VERSION ""

NS_ :

BS_:

BU_:

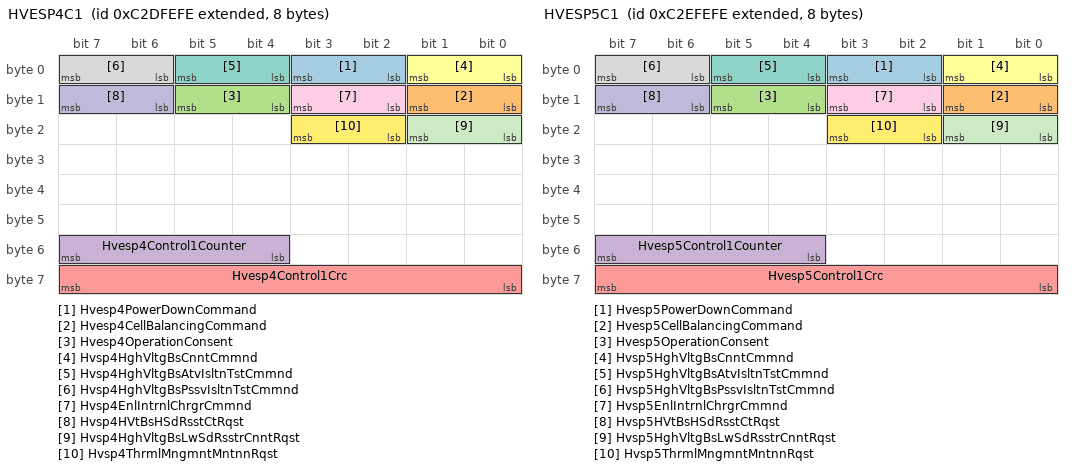
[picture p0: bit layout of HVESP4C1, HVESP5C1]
BO_ 2351824638 HVESP4C1: 8 Vector__XXX
 SG_ Hvesp4PowerDownCommand : 2|2@1+ (1,0) [0|3] "" Vector__XXX
 SG_ Hvesp4CellBalancingCommand : 8|2@1+ (1,0) [0|3] "" Vector__XXX
 SG_ Hvesp4OperationConsent : 12|2@1+ (1,0) [0|3] "" Vector__XXX
 SG_ Hvesp4Control1Counter : 52|4@1+ (1,0) [0|15] "" Vector__XXX
 SG_ Hvesp4Control1Crc : 56|8@1+ (1,0) [0|250] "count" Vector__XXX
 SG_ Hvsp4HghVltgBsCnntCmmnd : 0|2@1+ (1,0) [0|3] "" Vector__XXX
 SG_ Hvsp4HghVltgBsAtvIsltnTstCmmnd : 4|2@1+ (1,0) [0|3] "" Vector__XXX
 SG_ Hvsp4HghVltgBsPssvIsltnTstCmmnd : 6|2@1+ (1,0) [0|3] "" Vector__XXX
 SG_ Hvsp4EnlIntrnlChrgrCmmnd : 10|2@1+ (1,0) [0|3] "" Vector__XXX
 SG_ Hvsp4HVtBsHSdRsstCtRqst : 14|2@1+ (1,0) [0|3] "" Vector__XXX
 SG_ Hvsp4HghVltgBsLwSdRsstrCnntRqst : 16|2@1+ (1,0) [0|3] "" Vector__XXX
 SG_ Hvsp4ThrmlMngmntMntnnRqst : 18|2@1+ (1,0) [0|3] "" Vector__XXX

BO_ 2351890174 HVESP5C1: 8 Vector__XXX
 SG_ Hvesp5PowerDownCommand : 2|2@1+ (1,0) [0|3] "" Vector__XXX
 SG_ Hvesp5CellBalancingCommand : 8|2@1+ (1,0) [0|3] "" Vector__XXX
 SG_ Hvesp5OperationConsent : 12|2@1+ (1,0) [0|3] "" Vector__XXX
 SG_ Hvesp5Control1Counter : 52|4@1+ (1,0) [0|15] "" Vector__XXX
 SG_ Hvesp5Control1Crc : 56|8@1+ (1,0) [0|250] "count" Vector__XXX
 SG_ Hvsp5HghVltgBsCnntCmmnd : 0|2@1+ (1,0) [0|3] "" Vector__XXX
 SG_ Hvsp5HghVltgBsAtvIsltnTstCmmnd : 4|2@1+ (1,0) [0|3] "" Vector__XXX
 SG_ Hvsp5HghVltgBsPssvIsltnTstCmmnd : 6|2@1+ (1,0) [0|3] "" Vector__XXX
 SG_ Hvsp5EnlIntrnlChrgrCmmnd : 10|2@1+ (1,0) [0|3] "" Vector__XXX
 SG_ Hvsp5HVtBsHSdRsstCtRqst : 14|2@1+ (1,0) [0|3] "" Vector__XXX
 SG_ Hvsp5HghVltgBsLwSdRsstrCnntRqst : 16|2@1+ (1,0) [0|3] "" Vector__XXX
 SG_ Hvsp5ThrmlMngmntMntnnRqst : 18|2@1+ (1,0) [0|3] "" Vector__XXX

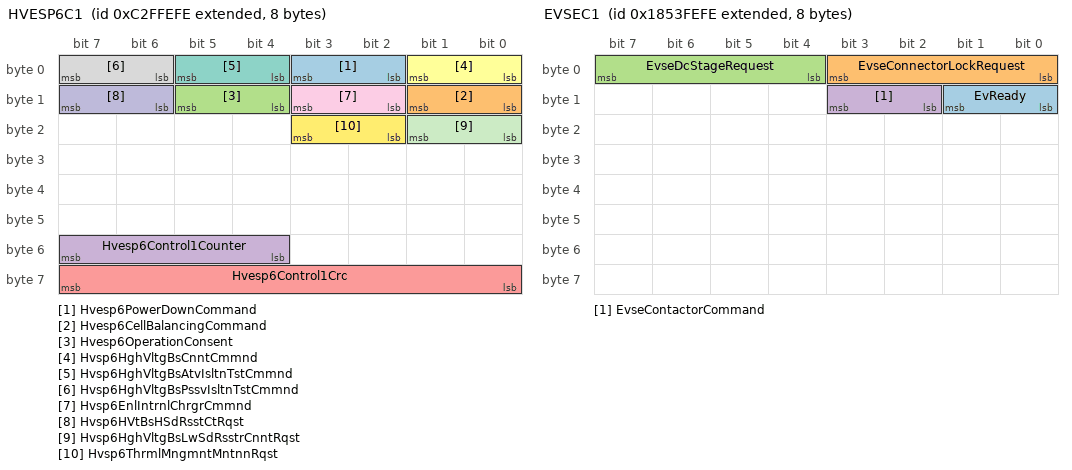
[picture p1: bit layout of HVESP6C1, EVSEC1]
BO_ 2351955710 HVESP6C1: 8 Vector__XXX
 SG_ Hvesp6PowerDownCommand : 2|2@1+ (1,0) [0|3] "" Vector__XXX
 SG_ Hvesp6CellBalancingCommand : 8|2@1+ (1,0) [0|3] "" Vector__XXX
 SG_ Hvesp6OperationConsent : 12|2@1+ (1,0) [0|3] "" Vector__XXX
 SG_ Hvesp6Control1Counter : 52|4@1+ (1,0) [0|15] "" Vector__XXX
 SG_ Hvesp6Control1Crc : 56|8@1+ (1,0) [0|250] "count" Vector__XXX
 SG_ Hvsp6HghVltgBsCnntCmmnd : 0|2@1+ (1,0) [0|3] "" Vector__XXX
 SG_ Hvsp6HghVltgBsAtvIsltnTstCmmnd : 4|2@1+ (1,0) [0|3] "" Vector__XXX
 SG_ Hvsp6HghVltgBsPssvIsltnTstCmmnd : 6|2@1+ (1,0) [0|3] "" Vector__XXX
 SG_ Hvsp6EnlIntrnlChrgrCmmnd : 10|2@1+ (1,0) [0|3] "" Vector__XXX
 SG_ Hvsp6HVtBsHSdRsstCtRqst : 14|2@1+ (1,0) [0|3] "" Vector__XXX
 SG_ Hvsp6HghVltgBsLwSdRsstrCnntRqst : 16|2@1+ (1,0) [0|3] "" Vector__XXX
 SG_ Hvsp6ThrmlMngmntMntnnRqst : 18|2@1+ (1,0) [0|3] "" Vector__XXX

BO_ 2555641598 EVSEC1: 8 Vector__XXX
 SG_ EvReady : 8|2@1+ (1,0) [0|3] "" Vector__XXX
 SG_ EvseConnectorLockRequest : 0|4@1+ (1,0) [0|15] "" Vector__XXX
 SG_ EvseDcStageRequest : 4|4@1+ (1,0) [0|15] "" Vector__XXX
 SG_ EvseContactorCommand : 10|2@1+ (1,0) [0|3] "" Vector__XXX

BO_ 2555707134 WINCH3: 8 Vector__XXX
 SG_ WinchPositionReset : 0|2@1+ (1,0) [0|3] "" Vector__XXX

BO_ 2354446078 ASC8: 8 Vector__XXX
 SG_ LiftAxle3PositionCommand : 0|2@1+ (1,0) [0|3] "" Vector__XXX

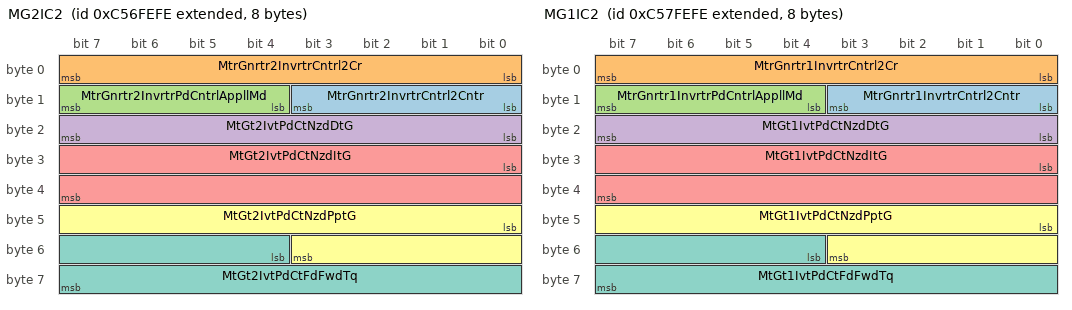
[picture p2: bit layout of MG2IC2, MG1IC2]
BO_ 2354511614 MG2IC2: 8 Vector__XXX
 SG_ MtrGnrtr2InvrtrCntrl2Cntr : 8|4@1+ (1,0) [0|15] "" Vector__XXX
 SG_ MtrGnrtr2InvrtrCntrl2Cr : 0|8@1+ (1,0) [0|250] "count" Vector__XXX
 SG_ MtrGnrtr2InvrtrPdCntrlAppllMd : 12|4@1+ (1,0) [0|15] "" Vector__XXX
 SG_ MtGt2IvtPdCtNzdDtG : 16|8@1+ (0.03125,0) [0|7.8125] "%/(%/s)" Vector__XXX
 SG_ MtGt2IvtPdCtNzdItG : 24|16@1+ (0.015625,0) [0|1003.984375] "%/(%/s)" Vector__XXX
 SG_ MtGt2IvtPdCtNzdPptG : 40|12@1+ (0.0625,0) [0|250.9375] "%/%" Vector__XXX
 SG_ MtGt2IvtPdCtFdFwdTq : 52|12@1+ (0.0625,-125) [-125|125.9375] "%" Vector__XXX

BO_ 2354577150 MG1IC2: 8 Vector__XXX
 SG_ MtrGnrtr1InvrtrCntrl2Cntr : 8|4@1+ (1,0) [0|15] "" Vector__XXX
 SG_ MtrGnrtr1InvrtrCntrl2Cr : 0|8@1+ (1,0) [0|250] "count" Vector__XXX
 SG_ MtrGnrtr1InvrtrPdCntrlAppllMd : 12|4@1+ (1,0) [0|15] "" Vector__XXX
 SG_ MtGt1IvtPdCtNzdDtG : 16|8@1+ (0.03125,0) [0|7.8125] "%/(%/s)" Vector__XXX
 SG_ MtGt1IvtPdCtNzdItG : 24|16@1+ (0.015625,0) [0|1003.984375] "%/(%/s)" Vector__XXX
 SG_ MtGt1IvtPdCtNzdPptG : 40|12@1+ (0.0625,0) [0|250.9375] "%/%" Vector__XXX
 SG_ MtGt1IvtPdCtFdFwdTq : 52|12@1+ (0.0625,-125) [-125|125.9375] "%" Vector__XXX

BO_ 2488860414 HCI2: 8 Vector__XXX
 SG_ HoistCommand : 0|16@1+ (0.005,-150) [-100|100] "%" Vector__XXX
 SG_ HoistDetentStatus : 16|2@1+ (1,0) [0|3] "" Vector__XXX

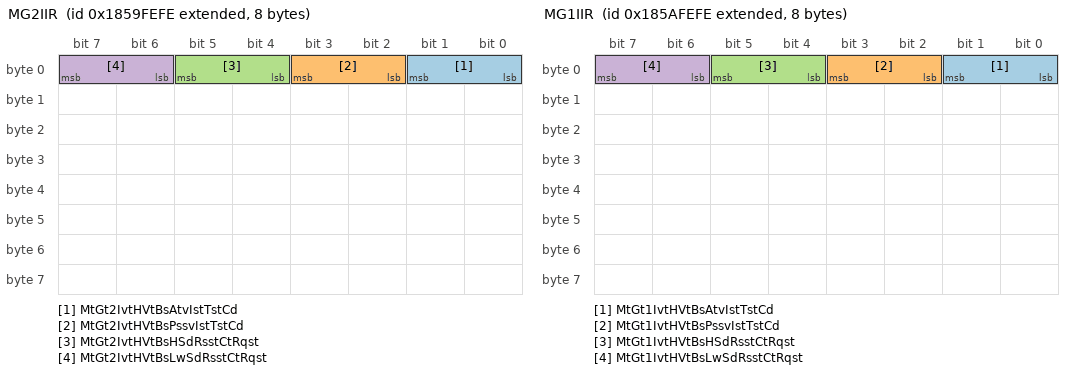
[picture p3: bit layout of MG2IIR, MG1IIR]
BO_ 2556034814 MG2IIR: 8 Vector__XXX
 SG_ MtGt2IvtHVtBsAtvIstTstCd : 0|2@1+ (1,0) [0|3] "" Vector__XXX
 SG_ MtGt2IvtHVtBsPssvIstTstCd : 2|2@1+ (1,0) [0|3] "" Vector__XXX
 SG_ MtGt2IvtHVtBsHSdRsstCtRqst : 4|2@1+ (1,0) [0|3] "" Vector__XXX
 SG_ MtGt2IvtHVtBsLwSdRsstCtRqst : 6|2@1+ (1,0) [0|3] "" Vector__XXX

BO_ 2556100350 MG1IIR: 8 Vector__XXX
 SG_ MtGt1IvtHVtBsAtvIstTstCd : 0|2@1+ (1,0) [0|3] "" Vector__XXX
 SG_ MtGt1IvtHVtBsPssvIstTstCd : 2|2@1+ (1,0) [0|3] "" Vector__XXX
 SG_ MtGt1IvtHVtBsHSdRsstCtRqst : 4|2@1+ (1,0) [0|3] "" Vector__XXX
 SG_ MtGt1IvtHVtBsLwSdRsstCtRqst : 6|2@1+ (1,0) [0|3] "" Vector__XXX

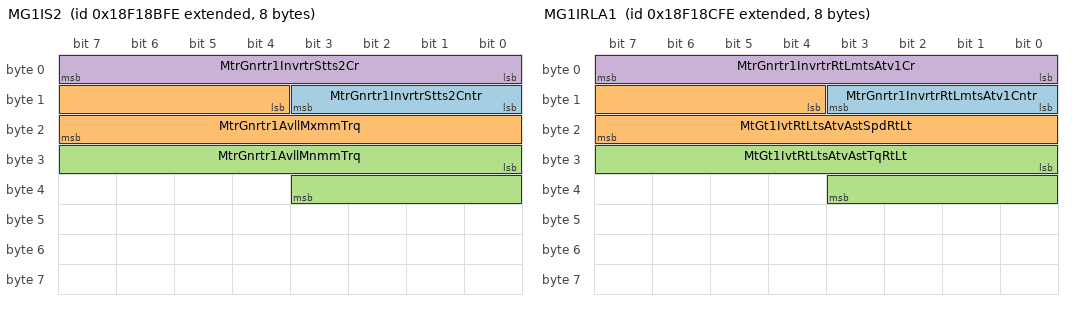
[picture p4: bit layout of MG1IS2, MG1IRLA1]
BO_ 2565966846 MG1IS2: 8 Vector__XXX
 SG_ MtrGnrtr1InvrtrStts2Cntr : 8|4@1+ (1,0) [0|15] "" Vector__XXX
 SG_ MtrGnrtr1AvllMxmmTrq : 12|12@1+ (0.0625,-125) [-125|125.9375] "%" Vector__XXX
 SG_ MtrGnrtr1AvllMnmmTrq : 24|12@1+ (0.0625,-125) [-125|125.9375] "%" Vector__XXX
 SG_ MtrGnrtr1InvrtrStts2Cr : 0|8@1+ (1,0) [0|250] "count" Vector__XXX

BO_ 2565967102 MG1IRLA1: 8 Vector__XXX
 SG_ MtrGnrtr1InvrtrRtLmtsAtv1Cntr : 8|4@1+ (1,0) [0|15] "" Vector__XXX
 SG_ MtGt1IvtRtLtsAtvAstSpdRtLt : 12|12@1+ (0.25,0) [0|1003.75] "%/s" Vector__XXX
 SG_ MtGt1IvtRtLtsAtvAstTqRtLt : 24|12@1+ (2,0) [0|8030] "%/s" Vector__XXX
 SG_ MtrGnrtr1InvrtrRtLmtsAtv1Cr : 0|8@1+ (1,0) [0|250] "count" Vector__XXX

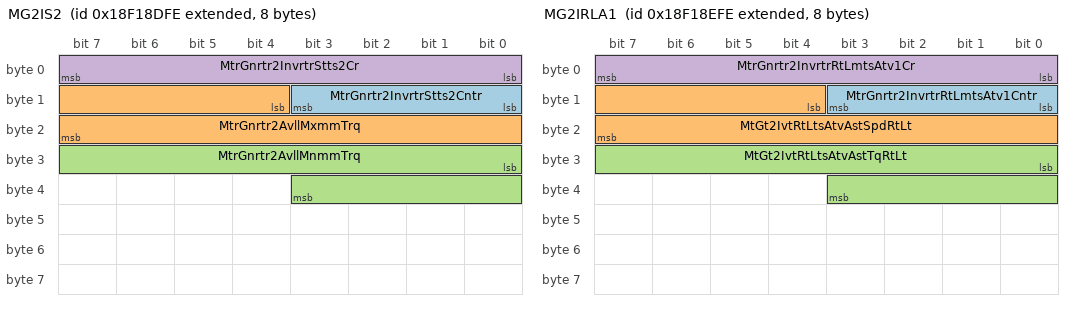
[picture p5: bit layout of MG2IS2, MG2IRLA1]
BO_ 2565967358 MG2IS2: 8 Vector__XXX
 SG_ MtrGnrtr2InvrtrStts2Cntr : 8|4@1+ (1,0) [0|15] "" Vector__XXX
 SG_ MtrGnrtr2AvllMxmmTrq : 12|12@1+ (0.0625,-125) [-125|125.9375] "%" Vector__XXX
 SG_ MtrGnrtr2AvllMnmmTrq : 24|12@1+ (0.0625,-125) [-125|125.9375] "%" Vector__XXX
 SG_ MtrGnrtr2InvrtrStts2Cr : 0|8@1+ (1,0) [0|250] "count" Vector__XXX

BO_ 2565967614 MG2IRLA1: 8 Vector__XXX
 SG_ MtrGnrtr2InvrtrRtLmtsAtv1Cntr : 8|4@1+ (1,0) [0|15] "" Vector__XXX
 SG_ MtGt2IvtRtLtsAtvAstSpdRtLt : 12|12@1+ (0.25,0) [0|1003.75] "%/s" Vector__XXX
 SG_ MtGt2IvtRtLtsAtvAstTqRtLt : 24|12@1+ (2,0) [0|8030] "%/s" Vector__XXX
 SG_ MtrGnrtr2InvrtrRtLmtsAtv1Cr : 0|8@1+ (1,0) [0|250] "count" Vector__XXX

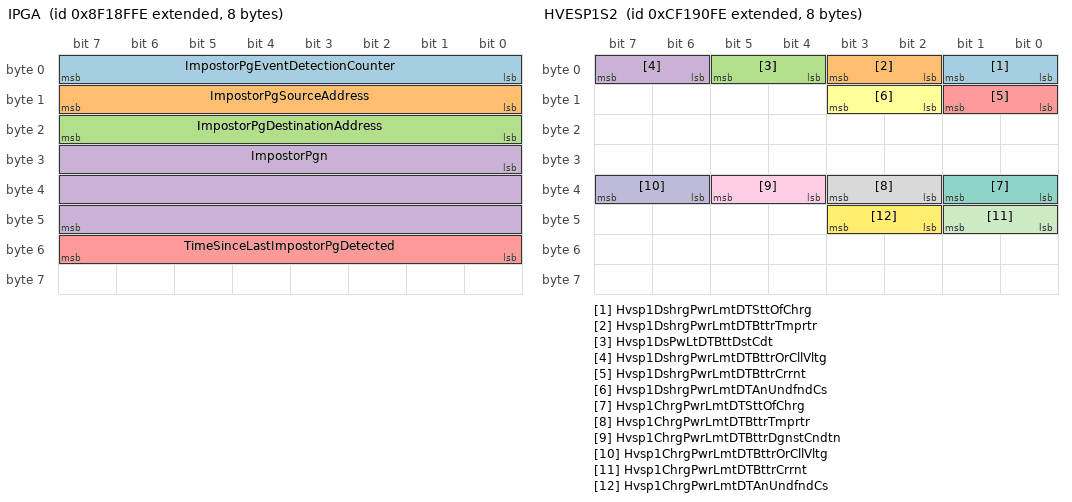
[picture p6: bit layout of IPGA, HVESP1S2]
BO_ 2297532414 IPGA: 8 Vector__XXX
 SG_ ImpostorPgEventDetectionCounter : 0|8@1+ (1,0) [0|250] "count" Vector__XXX
 SG_ ImpostorPgSourceAddress : 8|8@1+ (1,0) [0|250] "sourceadr" Vector__XXX
 SG_ ImpostorPgDestinationAddress : 16|8@1+ (1,0) [0|250] "sourceadr" Vector__XXX
 SG_ ImpostorPgn : 24|24@1+ (1,0) [0|16449535] "" Vector__XXX
 SG_ TimeSinceLastImpostorPgDetected : 48|8@1+ (1,0) [0|250] "min" Vector__XXX

BO_ 2364641534 HVESP1S2: 8 Vector__XXX
 SG_ Hvsp1DshrgPwrLmtDTSttOfChrg : 0|2@1+ (1,0) [0|3] "" Vector__XXX
 SG_ Hvsp1DshrgPwrLmtDTBttrTmprtr : 2|2@1+ (1,0) [0|3] "" Vector__XXX
 SG_ Hvsp1DsPwLtDTBttDstCdt : 4|2@1+ (1,0) [0|3] "" Vector__XXX
 SG_ Hvsp1DshrgPwrLmtDTBttrOrCllVltg : 6|2@1+ (1,0) [0|3] "" Vector__XXX
 SG_ Hvsp1DshrgPwrLmtDTBttrCrrnt : 8|2@1+ (1,0) [0|3] "" Vector__XXX
 SG_ Hvsp1DshrgPwrLmtDTAnUndfndCs : 10|2@1+ (1,0) [0|3] "" Vector__XXX
 SG_ Hvsp1ChrgPwrLmtDTSttOfChrg : 32|2@1+ (1,0) [0|3] "" Vector__XXX
 SG_ Hvsp1ChrgPwrLmtDTBttrTmprtr : 34|2@1+ (1,0) [0|3] "" Vector__XXX
 SG_ Hvsp1ChrgPwrLmtDTBttrDgnstCndtn : 36|2@1+ (1,0) [0|3] "" Vector__XXX
 SG_ Hvsp1ChrgPwrLmtDTBttrOrCllVltg : 38|2@1+ (1,0) [0|3] "" Vector__XXX
 SG_ Hvsp1ChrgPwrLmtDTBttrCrrnt : 40|2@1+ (1,0) [0|3] "" Vector__XXX
 SG_ Hvsp1ChrgPwrLmtDTAnUndfndCs : 42|2@1+ (1,0) [0|3] "" Vector__XXX

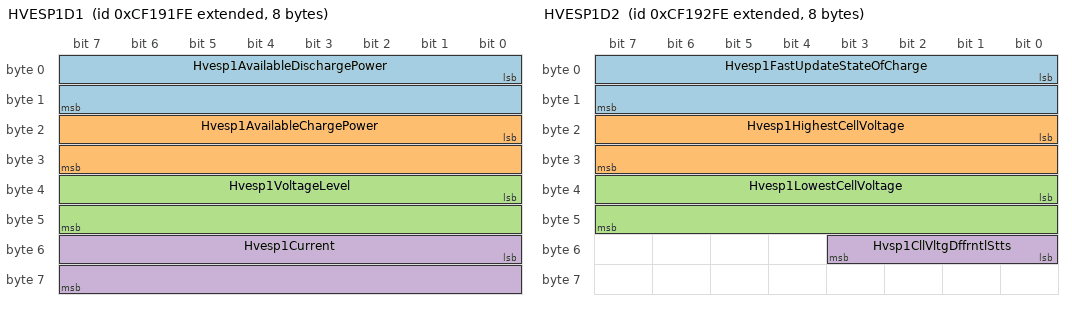
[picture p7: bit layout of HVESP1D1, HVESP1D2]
BO_ 2364641790 HVESP1D1: 8 Vector__XXX
 SG_ Hvesp1AvailableDischargePower : 0|16@1+ (0.05,0) [0|3212.75] "kW" Vector__XXX
 SG_ Hvesp1AvailableChargePower : 16|16@1+ (0.05,0) [0|3212.75] "kW" Vector__XXX
 SG_ Hvesp1VoltageLevel : 32|16@1+ (0.05,0) [0|3212.75] "V" Vector__XXX
 SG_ Hvesp1Current : 48|16@1+ (0.05,-1600) [-1600|1612.75] "A" Vector__XXX

BO_ 2364642046 HVESP1D2: 8 Vector__XXX
 SG_ Hvesp1FastUpdateStateOfCharge : 0|16@1+ (0.0015625,0) [0|100.3984375] "%" Vector__XXX
 SG_ Hvesp1HighestCellVoltage : 16|16@1+ (0.001,0) [0|64.255] "V" Vector__XXX
 SG_ Hvesp1LowestCellVoltage : 32|16@1+ (0.001,0) [0|64.255] "V" Vector__XXX
 SG_ Hvsp1CllVltgDffrntlStts : 48|4@1+ (1,0) [0|15] "" Vector__XXX

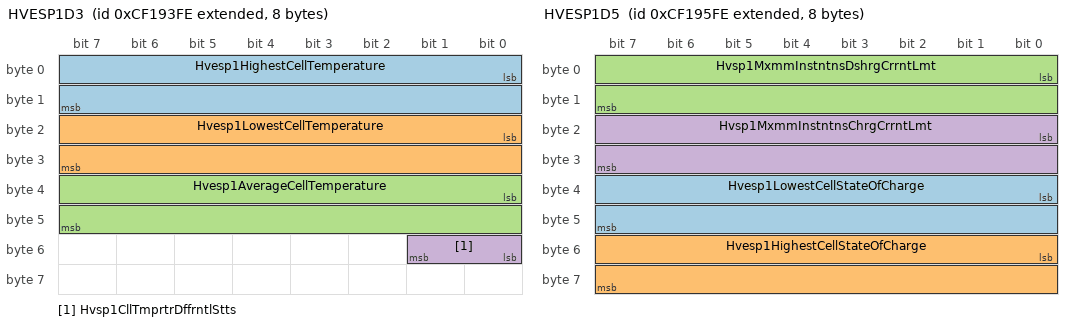
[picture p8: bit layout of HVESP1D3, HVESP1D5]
BO_ 2364642302 HVESP1D3: 8 Vector__XXX
 SG_ Hvesp1HighestCellTemperature : 0|16@1+ (0.03125,-273) [-273|1734.96875] "degC" Vector__XXX
 SG_ Hvesp1LowestCellTemperature : 16|16@1+ (0.03125,-273) [-273|1734.96875] "degC" Vector__XXX
 SG_ Hvesp1AverageCellTemperature : 32|16@1+ (0.03125,-273) [-273|1734.96875] "degC" Vector__XXX
 SG_ Hvsp1CllTmprtrDffrntlStts : 48|2@1+ (1,0) [0|3] "" Vector__XXX

BO_ 2364642558 HVESP1D4: 8 Vector__XXX
 SG_ Hvesp1DischargeCapacity : 0|16@1+ (0.01,0) [0|642.55] "Ah" Vector__XXX
 SG_ Hvesp1ChargeCapacity : 16|16@1+ (0.01,0) [0|642.55] "Ah" Vector__XXX
 SG_ Hvesp1CellBalancingCount : 32|16@1+ (1,0) [0|64255] "count" Vector__XXX

BO_ 2364642814 HVESP1D5: 8 Vector__XXX
 SG_ Hvesp1LowestCellStateOfCharge : 32|16@1+ (0.0015625,0) [0|100.3984375] "%" Vector__XXX
 SG_ Hvesp1HighestCellStateOfCharge : 48|16@1+ (0.0015625,0) [0|100.3984375] "%" Vector__XXX
 SG_ Hvsp1MxmmInstntnsDshrgCrrntLmt : 0|16@1+ (0.05,-1600) [-1600|0] "A" Vector__XXX
 SG_ Hvsp1MxmmInstntnsChrgCrrntLmt : 16|16@1+ (0.05,-1600) [0|1612.75] "A" Vector__XXX

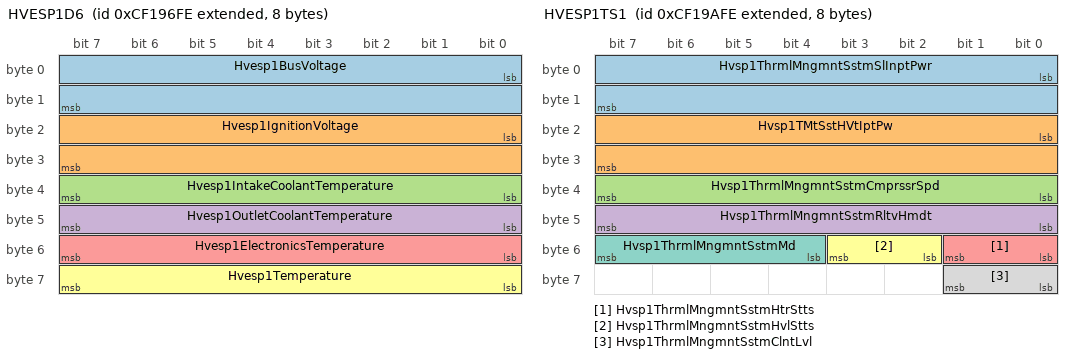
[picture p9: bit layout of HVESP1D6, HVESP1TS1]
BO_ 2364643070 HVESP1D6: 8 Vector__XXX
 SG_ Hvesp1BusVoltage : 0|16@1+ (0.05,0) [0|3212.75] "V" Vector__XXX
 SG_ Hvesp1IgnitionVoltage : 16|16@1+ (0.01,0) [0|642.55] "V" Vector__XXX
 SG_ Hvesp1IntakeCoolantTemperature : 32|8@1+ (1,-40) [-40|210] "degC" Vector__XXX
 SG_ Hvesp1OutletCoolantTemperature : 40|8@1+ (1,-40) [-40|210] "degC" Vector__XXX
 SG_ Hvesp1ElectronicsTemperature : 48|8@1+ (1,-40) [-40|210] "degC" Vector__XXX
 SG_ Hvesp1Temperature : 56|8@1+ (1,-40) [-40|210] "degC" Vector__XXX

BO_ 2364643326 HVESP1S1: 8 Vector__XXX
 SG_ Hvesp1HvilStatus : 20|2@1+ (1,0) [0|3] "" Vector__XXX
 SG_ Hvesp1InertiaSwitchStatus : 22|2@1+ (1,0) [0|3] "" Vector__XXX
 SG_ Hvesp1StateOfChargeStatus : 24|4@1+ (1,0) [0|15] "" Vector__XXX
 SG_ Hvesp1CellBalanceStatus : 28|2@1+ (1,0) [0|3] "" Vector__XXX
 SG_ Hvesp1CellBalancingActive : 30|2@1+ (1,0) [0|3] "" Vector__XXX
 SG_ Hvesp1InternalChargerStatus : 32|2@1+ (1,0) [0|3] "" Vector__XXX
 SG_ Hvesp1OperationalStatus : 44|4@1+ (1,0) [0|15] "" Vector__XXX
 SG_ Hvesp1Status1Counter : 52|4@1+ (1,0) [0|15] "" Vector__XXX
 SG_ Hvesp1Status1Crc : 56|8@1+ (1,0) [0|250] "count" Vector__XXX
 SG_ Hvsp1HghVltgBsPstvCnttrStt : 0|2@1+ (1,0) [0|3] "" Vector__XXX
 SG_ Hvsp1HghVltgBsNgtvCnttrStt : 2|2@1+ (1,0) [0|3] "" Vector__XXX
 SG_ Hvsp1HghVltgBsDsnntFrwrnng : 4|4@1+ (1,0) [0|15] "" Vector__XXX
 SG_ Hvsp1HghVltgBsPrChrgRlStt : 8|2@1+ (1,0) [0|3] "" Vector__XXX
 SG_ Hvsp1CntrOfPkCnttrStt : 10|2@1+ (1,0) [0|3] "" Vector__XXX
 SG_ Hvsp1HghVltgBsAtvIsltnTstStts : 12|4@1+ (1,0) [0|15] "" Vector__XXX
 SG_ Hvsp1HghVltgBsPssvIsltnTstStts : 16|4@1+ (1,0) [0|15] "" Vector__XXX
 SG_ Hvsp1HghVltgBsCnntnStts : 40|4@1+ (1,0) [0|15] "" Vector__XXX

BO_ 2364643582 HVESP1D7: 8 Vector__XXX
 SG_ Hvesp1DischargeEnergyCapacity : 0|24@1+ (0.001,0) [0|16449.535] "kWh" Vector__XXX
 SG_ Hvesp1ChargeEnergyCapacity : 24|24@1+ (0.001,0) [0|16449.535] "kWh" Vector__XXX
 SG_ Hvesp1MaximumChargeVoltageLimit : 48|16@1+ (0.05,0) [0|3212.75] "V" Vector__XXX

BO_ 2364643838 HVESP1MS1: 8 Vector__XXX
 SG_ Hvesp1Module1OperationalStatus : 0|2@1+ (1,0) [0|3] "" Vector__XXX
 SG_ Hvesp1Module2OperationalStatus : 2|2@1+ (1,0) [0|3] "" Vector__XXX
 SG_ Hvesp1Module3OperationalStatus : 4|2@1+ (1,0) [0|3] "" Vector__XXX
 SG_ Hvesp1Module4OperationalStatus : 6|2@1+ (1,0) [0|3] "" Vector__XXX
 SG_ Hvesp1Module5OperationalStatus : 8|2@1+ (1,0) [0|3] "" Vector__XXX
 SG_ Hvesp1Module6OperationalStatus : 10|2@1+ (1,0) [0|3] "" Vector__XXX
 SG_ Hvesp1Module7OperationalStatus : 12|2@1+ (1,0) [0|3] "" Vector__XXX
 SG_ Hvesp1Module8OperationalStatus : 14|2@1+ (1,0) [0|3] "" Vector__XXX
 SG_ Hvesp1Module9OperationalStatus : 16|2@1+ (1,0) [0|3] "" Vector__XXX
 SG_ Hvesp1Module10OperationalStatus : 18|2@1+ (1,0) [0|3] "" Vector__XXX
 SG_ Hvesp1Module11OperationalStatus : 20|2@1+ (1,0) [0|3] "" Vector__XXX
 SG_ Hvesp1Module12OperationalStatus : 22|2@1+ (1,0) [0|3] "" Vector__XXX
 SG_ Hvesp1Module13OperationalStatus : 24|2@1+ (1,0) [0|3] "" Vector__XXX
 SG_ Hvesp1Module14OperationalStatus : 26|2@1+ (1,0) [0|3] "" Vector__XXX
 SG_ Hvesp1Module15OperationalStatus : 28|2@1+ (1,0) [0|3] "" Vector__XXX
 SG_ Hvesp1Module16OperationalStatus : 30|2@1+ (1,0) [0|3] "" Vector__XXX
 SG_ Hvesp1Module17OperationalStatus : 32|2@1+ (1,0) [0|3] "" Vector__XXX
 SG_ Hvesp1Module18OperationalStatus : 34|2@1+ (1,0) [0|3] "" Vector__XXX
 SG_ Hvesp1Module19OperationalStatus : 36|2@1+ (1,0) [0|3] "" Vector__XXX
 SG_ Hvesp1Module20OperationalStatus : 38|2@1+ (1,0) [0|3] "" Vector__XXX
 SG_ Hvesp1Module21OperationalStatus : 40|2@1+ (1,0) [0|3] "" Vector__XXX
 SG_ Hvesp1Module22OperationalStatus : 42|2@1+ (1,0) [0|3] "" Vector__XXX
 SG_ Hvesp1Module23OperationalStatus : 44|2@1+ (1,0) [0|3] "" Vector__XXX
 SG_ Hvesp1Module24OperationalStatus : 46|2@1+ (1,0) [0|3] "" Vector__XXX
 SG_ Hvesp1Module25OperationalStatus : 48|2@1+ (1,0) [0|3] "" Vector__XXX
 SG_ Hvesp1Module26OperationalStatus : 50|2@1+ (1,0) [0|3] "" Vector__XXX
 SG_ Hvesp1Module27OperationalStatus : 52|2@1+ (1,0) [0|3] "" Vector__XXX
 SG_ Hvesp1Module28OperationalStatus : 54|2@1+ (1,0) [0|3] "" Vector__XXX
 SG_ Hvesp1Module29OperationalStatus : 56|2@1+ (1,0) [0|3] "" Vector__XXX
 SG_ Hvesp1Module30OperationalStatus : 58|2@1+ (1,0) [0|3] "" Vector__XXX
 SG_ Hvesp1Module31OperationalStatus : 60|2@1+ (1,0) [0|3] "" Vector__XXX
 SG_ Hvesp1Module32OperationalStatus : 62|2@1+ (1,0) [0|3] "" Vector__XXX

BO_ 2364644094 HVESP1TS1: 8 Vector__XXX
 SG_ Hvsp1ThrmlMngmntSstmSlInptPwr : 0|16@1+ (0.5,0) [0|32127.5] "W" Vector__XXX
 SG_ Hvsp1TMtSstHVtIptPw : 16|16@1+ (0.5,0) [0|32127.5] "W" Vector__XXX
 SG_ Hvsp1ThrmlMngmntSstmCmprssrSpd : 32|8@1+ (32,0) [0|8000] "rpm" Vector__XXX
 SG_ Hvsp1ThrmlMngmntSstmRltvHmdt : 40|8@1+ (0.4,0) [0|100] "%" Vector__XXX
 SG_ Hvsp1ThrmlMngmntSstmHtrStts : 48|2@1+ (1,0) [0|3] "" Vector__XXX
 SG_ Hvsp1ThrmlMngmntSstmHvlStts : 50|2@1+ (1,0) [0|3] "" Vector__XXX
 SG_ Hvsp1ThrmlMngmntSstmMd : 52|4@1+ (1,0) [0|15] "" Vector__XXX
 SG_ Hvsp1ThrmlMngmntSstmClntLvl : 56|2@1+ (1,0) [0|3] "" Vector__XXX

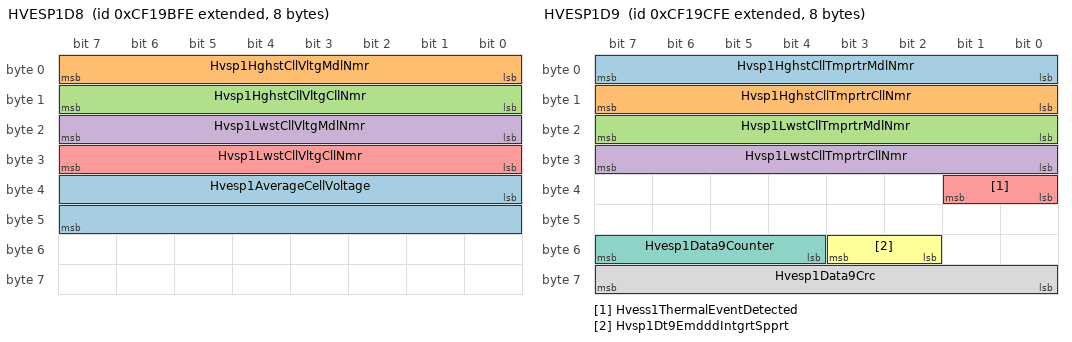
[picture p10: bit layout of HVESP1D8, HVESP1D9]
BO_ 2364644350 HVESP1D8: 8 Vector__XXX
 SG_ Hvesp1AverageCellVoltage : 32|16@1+ (0.001,0) [0|64.255] "V" Vector__XXX
 SG_ Hvsp1HghstCllVltgMdlNmr : 0|8@1+ (1,0) [0|250] "count" Vector__XXX
 SG_ Hvsp1HghstCllVltgCllNmr : 8|8@1+ (1,0) [0|250] "count" Vector__XXX
 SG_ Hvsp1LwstCllVltgMdlNmr : 16|8@1+ (1,0) [0|250] "count" Vector__XXX
 SG_ Hvsp1LwstCllVltgCllNmr : 24|8@1+ (1,0) [0|250] "count" Vector__XXX

BO_ 2364644606 HVESP1D9: 8 Vector__XXX
 SG_ Hvsp1HghstCllTmprtrMdlNmr : 0|8@1+ (1,0) [0|250] "count" Vector__XXX
 SG_ Hvsp1HghstCllTmprtrCllNmr : 8|8@1+ (1,0) [0|250] "count" Vector__XXX
 SG_ Hvsp1LwstCllTmprtrMdlNmr : 16|8@1+ (1,0) [0|250] "count" Vector__XXX
 SG_ Hvsp1LwstCllTmprtrCllNmr : 24|8@1+ (1,0) [0|250] "count" Vector__XXX
 SG_ Hvess1ThermalEventDetected : 32|2@1+ (1,0) [0|3] "" Vector__XXX
 SG_ Hvsp1Dt9EmdddIntgrtSpprt : 50|2@1+ (1,0) [0|3] "" Vector__XXX
 SG_ Hvesp1Data9Counter : 52|4@1+ (1,0) [0|15] "" Vector__XXX
 SG_ Hvesp1Data9Crc : 56|8@1+ (1,0) [0|250] "count" Vector__XXX

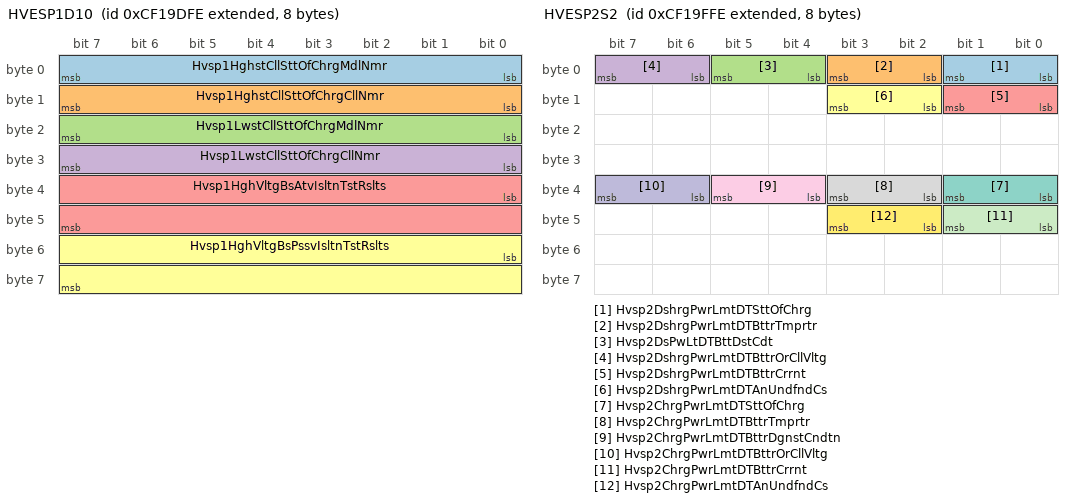
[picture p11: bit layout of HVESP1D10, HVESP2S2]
BO_ 2364644862 HVESP1D10: 8 Vector__XXX
 SG_ Hvsp1HghstCllSttOfChrgMdlNmr : 0|8@1+ (1,0) [0|250] "count" Vector__XXX
 SG_ Hvsp1HghstCllSttOfChrgCllNmr : 8|8@1+ (1,0) [0|250] "count" Vector__XXX
 SG_ Hvsp1LwstCllSttOfChrgMdlNmr : 16|8@1+ (1,0) [0|250] "count" Vector__XXX
 SG_ Hvsp1LwstCllSttOfChrgCllNmr : 24|8@1+ (1,0) [0|250] "count" Vector__XXX
 SG_ Hvsp1HghVltgBsAtvIsltnTstRslts : 32|16@1+ (0.1,0) [0|6425.5] "OhmPerV" Vector__XXX
 SG_ Hvsp1HghVltgBsPssvIsltnTstRslts : 48|16@1+ (0.1,0) [0|6425.5] "OhmPerV" Vector__XXX

BO_ 2364645118 HVESP1D11: 8 Vector__XXX
 SG_ Hvesp1ActualChargeRate : 32|16@1+ (0.05,0) [0|3212.75] "kW" Vector__XXX
 SG_ Hvsp1BsVltgNgtvTChsssGrndVltg : 0|16@1+ (0.05,0) [0|3212.75] "V" Vector__XXX
 SG_ Hvsp1VltgLvlNgtvTChsssGrndVltg : 16|16@1+ (0.05,0) [0|3212.75] "V" Vector__XXX

BO_ 2364645374 HVESP2S2: 8 Vector__XXX
 SG_ Hvsp2DshrgPwrLmtDTSttOfChrg : 0|2@1+ (1,0) [0|3] "" Vector__XXX
 SG_ Hvsp2DshrgPwrLmtDTBttrTmprtr : 2|2@1+ (1,0) [0|3] "" Vector__XXX
 SG_ Hvsp2DsPwLtDTBttDstCdt : 4|2@1+ (1,0) [0|3] "" Vector__XXX
 SG_ Hvsp2DshrgPwrLmtDTBttrOrCllVltg : 6|2@1+ (1,0) [0|3] "" Vector__XXX
 SG_ Hvsp2DshrgPwrLmtDTBttrCrrnt : 8|2@1+ (1,0) [0|3] "" Vector__XXX
 SG_ Hvsp2DshrgPwrLmtDTAnUndfndCs : 10|2@1+ (1,0) [0|3] "" Vector__XXX
 SG_ Hvsp2ChrgPwrLmtDTSttOfChrg : 32|2@1+ (1,0) [0|3] "" Vector__XXX
 SG_ Hvsp2ChrgPwrLmtDTBttrTmprtr : 34|2@1+ (1,0) [0|3] "" Vector__XXX
 SG_ Hvsp2ChrgPwrLmtDTBttrDgnstCndtn : 36|2@1+ (1,0) [0|3] "" Vector__XXX
 SG_ Hvsp2ChrgPwrLmtDTBttrOrCllVltg : 38|2@1+ (1,0) [0|3] "" Vector__XXX
 SG_ Hvsp2ChrgPwrLmtDTBttrCrrnt : 40|2@1+ (1,0) [0|3] "" Vector__XXX
 SG_ Hvsp2ChrgPwrLmtDTAnUndfndCs : 42|2@1+ (1,0) [0|3] "" Vector__XXX

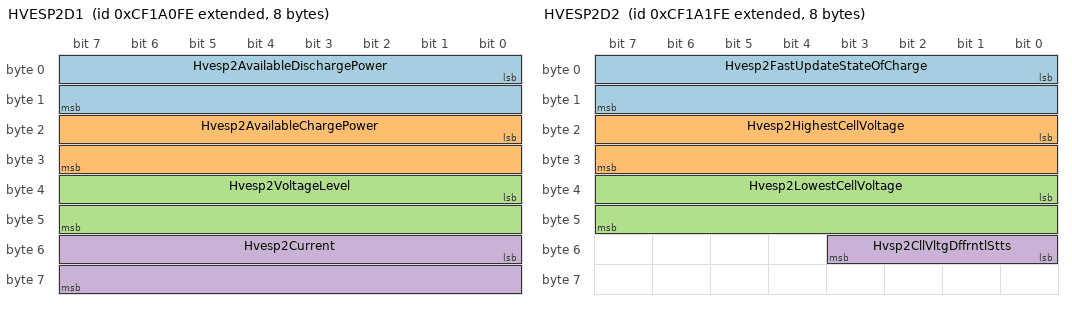
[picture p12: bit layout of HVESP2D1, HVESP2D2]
BO_ 2364645630 HVESP2D1: 8 Vector__XXX
 SG_ Hvesp2AvailableDischargePower : 0|16@1+ (0.05,0) [0|3212.75] "kW" Vector__XXX
 SG_ Hvesp2AvailableChargePower : 16|16@1+ (0.05,0) [0|3212.75] "kW" Vector__XXX
 SG_ Hvesp2VoltageLevel : 32|16@1+ (0.05,0) [0|3212.75] "V" Vector__XXX
 SG_ Hvesp2Current : 48|16@1+ (0.05,-1600) [-1600|1612.75] "A" Vector__XXX

BO_ 2364645886 HVESP2D2: 8 Vector__XXX
 SG_ Hvesp2FastUpdateStateOfCharge : 0|16@1+ (0.0015625,0) [0|100.3984375] "%" Vector__XXX
 SG_ Hvesp2HighestCellVoltage : 16|16@1+ (0.001,0) [0|64.255] "V" Vector__XXX
 SG_ Hvesp2LowestCellVoltage : 32|16@1+ (0.001,0) [0|64.255] "V" Vector__XXX
 SG_ Hvsp2CllVltgDffrntlStts : 48|4@1+ (1,0) [0|15] "" Vector__XXX

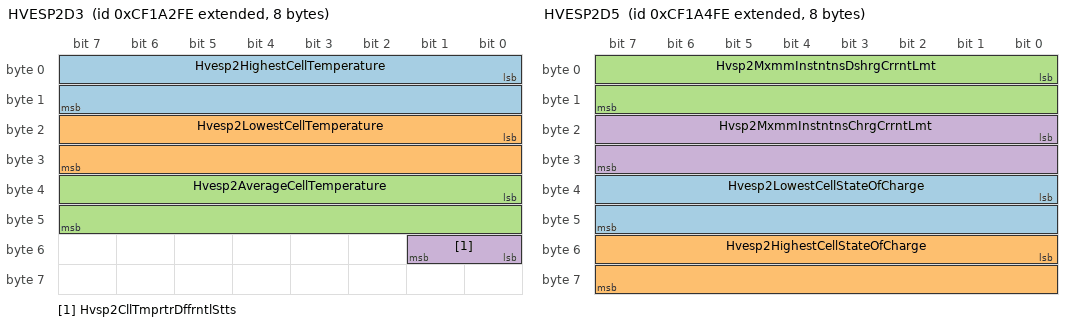
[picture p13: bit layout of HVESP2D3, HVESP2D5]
BO_ 2364646142 HVESP2D3: 8 Vector__XXX
 SG_ Hvesp2HighestCellTemperature : 0|16@1+ (0.03125,-273) [-273|1734.96875] "degC" Vector__XXX
 SG_ Hvesp2LowestCellTemperature : 16|16@1+ (0.03125,-273) [-273|1734.96875] "degC" Vector__XXX
 SG_ Hvesp2AverageCellTemperature : 32|16@1+ (0.03125,-273) [-273|1734.96875] "degC" Vector__XXX
 SG_ Hvsp2CllTmprtrDffrntlStts : 48|2@1+ (1,0) [0|3] "" Vector__XXX

BO_ 2364646398 HVESP2D4: 8 Vector__XXX
 SG_ Hvesp2DischargeCapacity : 0|16@1+ (0.01,0) [0|642.55] "Ah" Vector__XXX
 SG_ Hvesp2ChargeCapacity : 16|16@1+ (0.01,0) [0|642.55] "Ah" Vector__XXX
 SG_ Hvesp2CellBalancingCount : 32|16@1+ (1,0) [0|64255] "count" Vector__XXX

BO_ 2364646654 HVESP2D5: 8 Vector__XXX
 SG_ Hvesp2LowestCellStateOfCharge : 32|16@1+ (0.0015625,0) [0|100.3984375] "%" Vector__XXX
 SG_ Hvesp2HighestCellStateOfCharge : 48|16@1+ (0.0015625,0) [0|100.3984375] "%" Vector__XXX
 SG_ Hvsp2MxmmInstntnsDshrgCrrntLmt : 0|16@1+ (0.05,-1600) [-1600|0] "A" Vector__XXX
 SG_ Hvsp2MxmmInstntnsChrgCrrntLmt : 16|16@1+ (0.05,-1600) [0|1612.75] "A" Vector__XXX

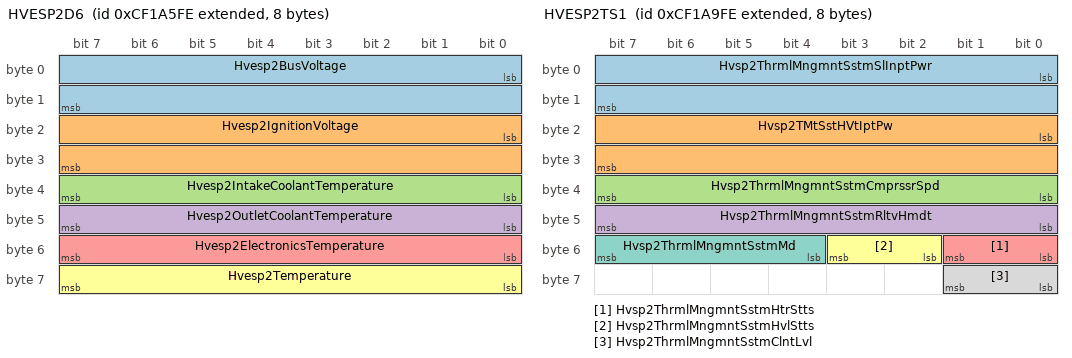
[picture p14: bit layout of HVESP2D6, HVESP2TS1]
BO_ 2364646910 HVESP2D6: 8 Vector__XXX
 SG_ Hvesp2BusVoltage : 0|16@1+ (0.05,0) [0|3212.75] "V" Vector__XXX
 SG_ Hvesp2IgnitionVoltage : 16|16@1+ (0.01,0) [0|642.55] "V" Vector__XXX
 SG_ Hvesp2IntakeCoolantTemperature : 32|8@1+ (1,-40) [-40|210] "degC" Vector__XXX
 SG_ Hvesp2OutletCoolantTemperature : 40|8@1+ (1,-40) [-40|210] "degC" Vector__XXX
 SG_ Hvesp2ElectronicsTemperature : 48|8@1+ (1,-40) [-40|210] "degC" Vector__XXX
 SG_ Hvesp2Temperature : 56|8@1+ (1,-40) [-40|210] "degC" Vector__XXX

BO_ 2364647166 HVESP2S1: 8 Vector__XXX
 SG_ Hvesp2HvilStatus : 20|2@1+ (1,0) [0|3] "" Vector__XXX
 SG_ Hvesp2InertiaSwitchStatus : 22|2@1+ (1,0) [0|3] "" Vector__XXX
 SG_ Hvesp2StateOfChargeStatus : 24|4@1+ (1,0) [0|15] "" Vector__XXX
 SG_ Hvesp2CellBalanceStatus : 28|2@1+ (1,0) [0|3] "" Vector__XXX
 SG_ Hvesp2CellBalancingActive : 30|2@1+ (1,0) [0|3] "" Vector__XXX
 SG_ Hvesp2InternalChargerStatus : 32|2@1+ (1,0) [0|3] "" Vector__XXX
 SG_ Hvesp2OperationalStatus : 44|4@1+ (1,0) [0|15] "" Vector__XXX
 SG_ Hvesp2Status1Counter : 52|4@1+ (1,0) [0|15] "" Vector__XXX
 SG_ Hvesp2Status1Crc : 56|8@1+ (1,0) [0|250] "count" Vector__XXX
 SG_ Hvsp2HghVltgBsPstvCnttrStt : 0|2@1+ (1,0) [0|3] "" Vector__XXX
 SG_ Hvsp2HghVltgBsNgtvCnttrStt : 2|2@1+ (1,0) [0|3] "" Vector__XXX
 SG_ Hvsp2HghVltgBsDsnntFrwrnng : 4|4@1+ (1,0) [0|15] "" Vector__XXX
 SG_ Hvsp2HghVltgBsPrChrgRlStt : 8|2@1+ (1,0) [0|3] "" Vector__XXX
 SG_ Hvsp2CntrOfPkCnttrStt : 10|2@1+ (1,0) [0|3] "" Vector__XXX
 SG_ Hvsp2HghVltgBsAtvIsltnTstStts : 12|4@1+ (1,0) [0|15] "" Vector__XXX
 SG_ Hvsp2HghVltgBsPssvIsltnTstStts : 16|4@1+ (1,0) [0|15] "" Vector__XXX
 SG_ Hvsp2HghVltgBsCnntnStts : 40|4@1+ (1,0) [0|15] "" Vector__XXX

BO_ 2364647422 HVESP2D7: 8 Vector__XXX
 SG_ Hvesp2DischargeEnergyCapacity : 0|24@1+ (0.001,0) [0|16449.535] "kWh" Vector__XXX
 SG_ Hvesp2ChargeEnergyCapacity : 24|24@1+ (0.001,0) [0|16449.535] "kWh" Vector__XXX
 SG_ Hvesp2MaximumChargeVoltageLimit : 48|16@1+ (0.05,0) [0|3212.75] "V" Vector__XXX

BO_ 2364647678 HVESP2MS1: 8 Vector__XXX
 SG_ Hvesp2Module1OperationalStatus : 0|2@1+ (1,0) [0|3] "" Vector__XXX
 SG_ Hvesp2Module2OperationalStatus : 2|2@1+ (1,0) [0|3] "" Vector__XXX
 SG_ Hvesp2Module3OperationalStatus : 4|2@1+ (1,0) [0|3] "" Vector__XXX
 SG_ Hvesp2Module4OperationalStatus : 6|2@1+ (1,0) [0|3] "" Vector__XXX
 SG_ Hvesp2Module5OperationalStatus : 8|2@1+ (1,0) [0|3] "" Vector__XXX
 SG_ Hvesp2Module6OperationalStatus : 10|2@1+ (1,0) [0|3] "" Vector__XXX
 SG_ Hvesp2Module7OperationalStatus : 12|2@1+ (1,0) [0|3] "" Vector__XXX
 SG_ Hvesp2Module8OperationalStatus : 14|2@1+ (1,0) [0|3] "" Vector__XXX
 SG_ Hvesp2Module9OperationalStatus : 16|2@1+ (1,0) [0|3] "" Vector__XXX
 SG_ Hvesp2Module10OperationalStatus : 18|2@1+ (1,0) [0|3] "" Vector__XXX
 SG_ Hvesp2Module11OperationalStatus : 20|2@1+ (1,0) [0|3] "" Vector__XXX
 SG_ Hvesp2Module12OperationalStatus : 22|2@1+ (1,0) [0|3] "" Vector__XXX
 SG_ Hvesp2Module13OperationalStatus : 24|2@1+ (1,0) [0|3] "" Vector__XXX
 SG_ Hvesp2Module14OperationalStatus : 26|2@1+ (1,0) [0|3] "" Vector__XXX
 SG_ Hvesp2Module15OperationalStatus : 28|2@1+ (1,0) [0|3] "" Vector__XXX
 SG_ Hvesp2Module16OperationalStatus : 30|2@1+ (1,0) [0|3] "" Vector__XXX
 SG_ Hvesp2Module17OperationalStatus : 32|2@1+ (1,0) [0|3] "" Vector__XXX
 SG_ Hvesp2Module18OperationalStatus : 34|2@1+ (1,0) [0|3] "" Vector__XXX
 SG_ Hvesp2Module19OperationalStatus : 36|2@1+ (1,0) [0|3] "" Vector__XXX
 SG_ Hvesp2Module20OperationalStatus : 38|2@1+ (1,0) [0|3] "" Vector__XXX
 SG_ Hvesp2Module21OperationalStatus : 40|2@1+ (1,0) [0|3] "" Vector__XXX
 SG_ Hvesp2Module22OperationalStatus : 42|2@1+ (1,0) [0|3] "" Vector__XXX
 SG_ Hvesp2Module23OperationalStatus : 44|2@1+ (1,0) [0|3] "" Vector__XXX
 SG_ Hvesp2Module24OperationalStatus : 46|2@1+ (1,0) [0|3] "" Vector__XXX
 SG_ Hvesp2Module25OperationalStatus : 48|2@1+ (1,0) [0|3] "" Vector__XXX
 SG_ Hvesp2Module26OperationalStatus : 50|2@1+ (1,0) [0|3] "" Vector__XXX
 SG_ Hvesp2Module27OperationalStatus : 52|2@1+ (1,0) [0|3] "" Vector__XXX
 SG_ Hvesp2Module28OperationalStatus : 54|2@1+ (1,0) [0|3] "" Vector__XXX
 SG_ Hvesp2Module29OperationalStatus : 56|2@1+ (1,0) [0|3] "" Vector__XXX
 SG_ Hvesp2Module30OperationalStatus : 58|2@1+ (1,0) [0|3] "" Vector__XXX
 SG_ Hvesp2Module31OperationalStatus : 60|2@1+ (1,0) [0|3] "" Vector__XXX
 SG_ Hvesp2Module32OperationalStatus : 62|2@1+ (1,0) [0|3] "" Vector__XXX

BO_ 2364647934 HVESP2TS1: 8 Vector__XXX
 SG_ Hvsp2ThrmlMngmntSstmSlInptPwr : 0|16@1+ (0.5,0) [0|32127.5] "W" Vector__XXX
 SG_ Hvsp2TMtSstHVtIptPw : 16|16@1+ (0.5,0) [0|32127.5] "W" Vector__XXX
 SG_ Hvsp2ThrmlMngmntSstmCmprssrSpd : 32|8@1+ (32,0) [0|8000] "rpm" Vector__XXX
 SG_ Hvsp2ThrmlMngmntSstmRltvHmdt : 40|8@1+ (0.4,0) [0|100] "%" Vector__XXX
 SG_ Hvsp2ThrmlMngmntSstmHtrStts : 48|2@1+ (1,0) [0|3] "" Vector__XXX
 SG_ Hvsp2ThrmlMngmntSstmHvlStts : 50|2@1+ (1,0) [0|3] "" Vector__XXX
 SG_ Hvsp2ThrmlMngmntSstmMd : 52|4@1+ (1,0) [0|15] "" Vector__XXX
 SG_ Hvsp2ThrmlMngmntSstmClntLvl : 56|2@1+ (1,0) [0|3] "" Vector__XXX

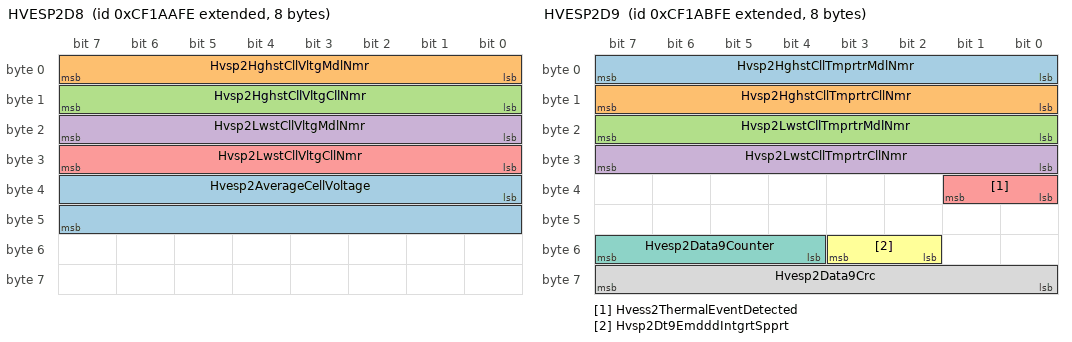
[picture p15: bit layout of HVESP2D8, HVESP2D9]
BO_ 2364648190 HVESP2D8: 8 Vector__XXX
 SG_ Hvesp2AverageCellVoltage : 32|16@1+ (0.001,0) [0|64.255] "V" Vector__XXX
 SG_ Hvsp2HghstCllVltgMdlNmr : 0|8@1+ (1,0) [0|250] "count" Vector__XXX
 SG_ Hvsp2HghstCllVltgCllNmr : 8|8@1+ (1,0) [0|250] "count" Vector__XXX
 SG_ Hvsp2LwstCllVltgMdlNmr : 16|8@1+ (1,0) [0|250] "count" Vector__XXX
 SG_ Hvsp2LwstCllVltgCllNmr : 24|8@1+ (1,0) [0|250] "count" Vector__XXX

BO_ 2364648446 HVESP2D9: 8 Vector__XXX
 SG_ Hvsp2HghstCllTmprtrMdlNmr : 0|8@1+ (1,0) [0|250] "count" Vector__XXX
 SG_ Hvsp2HghstCllTmprtrCllNmr : 8|8@1+ (1,0) [0|250] "count" Vector__XXX
 SG_ Hvsp2LwstCllTmprtrMdlNmr : 16|8@1+ (1,0) [0|250] "count" Vector__XXX
 SG_ Hvsp2LwstCllTmprtrCllNmr : 24|8@1+ (1,0) [0|250] "count" Vector__XXX
 SG_ Hvess2ThermalEventDetected : 32|2@1+ (1,0) [0|3] "" Vector__XXX
 SG_ Hvsp2Dt9EmdddIntgrtSpprt : 50|2@1+ (1,0) [0|3] "" Vector__XXX
 SG_ Hvesp2Data9Counter : 52|4@1+ (1,0) [0|15] "" Vector__XXX
 SG_ Hvesp2Data9Crc : 56|8@1+ (1,0) [0|250] "count" Vector__XXX

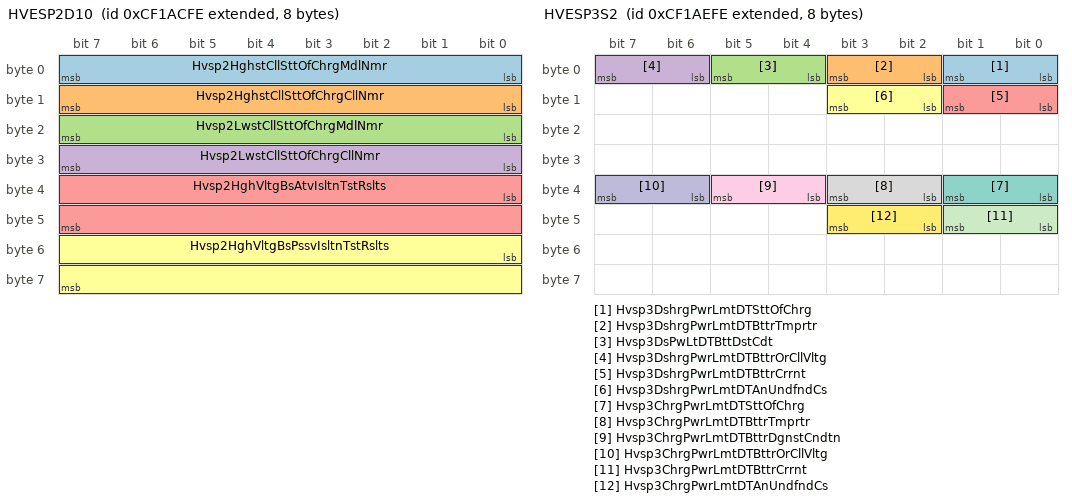
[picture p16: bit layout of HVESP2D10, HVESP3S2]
BO_ 2364648702 HVESP2D10: 8 Vector__XXX
 SG_ Hvsp2HghstCllSttOfChrgMdlNmr : 0|8@1+ (1,0) [0|250] "count" Vector__XXX
 SG_ Hvsp2HghstCllSttOfChrgCllNmr : 8|8@1+ (1,0) [0|250] "count" Vector__XXX
 SG_ Hvsp2LwstCllSttOfChrgMdlNmr : 16|8@1+ (1,0) [0|250] "count" Vector__XXX
 SG_ Hvsp2LwstCllSttOfChrgCllNmr : 24|8@1+ (1,0) [0|250] "count" Vector__XXX
 SG_ Hvsp2HghVltgBsAtvIsltnTstRslts : 32|16@1+ (0.1,0) [0|6425.5] "OhmPerV" Vector__XXX
 SG_ Hvsp2HghVltgBsPssvIsltnTstRslts : 48|16@1+ (0.1,0) [0|6425.5] "OhmPerV" Vector__XXX

BO_ 2364648958 HVESP2D11: 8 Vector__XXX
 SG_ Hvesp2ActualChargeRate : 32|16@1+ (0.05,0) [0|3212.75] "kW" Vector__XXX
 SG_ Hvsp2BsVltgNgtvTChsssGrndVltg : 0|16@1+ (0.05,0) [0|3212.75] "V" Vector__XXX
 SG_ Hvsp2VltgLvlNgtvTChsssGrndVltg : 16|16@1+ (0.05,0) [0|3212.75] "V" Vector__XXX

BO_ 2364649214 HVESP3S2: 8 Vector__XXX
 SG_ Hvsp3DshrgPwrLmtDTSttOfChrg : 0|2@1+ (1,0) [0|3] "" Vector__XXX
 SG_ Hvsp3DshrgPwrLmtDTBttrTmprtr : 2|2@1+ (1,0) [0|3] "" Vector__XXX
 SG_ Hvsp3DsPwLtDTBttDstCdt : 4|2@1+ (1,0) [0|3] "" Vector__XXX
 SG_ Hvsp3DshrgPwrLmtDTBttrOrCllVltg : 6|2@1+ (1,0) [0|3] "" Vector__XXX
 SG_ Hvsp3DshrgPwrLmtDTBttrCrrnt : 8|2@1+ (1,0) [0|3] "" Vector__XXX
 SG_ Hvsp3DshrgPwrLmtDTAnUndfndCs : 10|2@1+ (1,0) [0|3] "" Vector__XXX
 SG_ Hvsp3ChrgPwrLmtDTSttOfChrg : 32|2@1+ (1,0) [0|3] "" Vector__XXX
 SG_ Hvsp3ChrgPwrLmtDTBttrTmprtr : 34|2@1+ (1,0) [0|3] "" Vector__XXX
 SG_ Hvsp3ChrgPwrLmtDTBttrDgnstCndtn : 36|2@1+ (1,0) [0|3] "" Vector__XXX
 SG_ Hvsp3ChrgPwrLmtDTBttrOrCllVltg : 38|2@1+ (1,0) [0|3] "" Vector__XXX
 SG_ Hvsp3ChrgPwrLmtDTBttrCrrnt : 40|2@1+ (1,0) [0|3] "" Vector__XXX
 SG_ Hvsp3ChrgPwrLmtDTAnUndfndCs : 42|2@1+ (1,0) [0|3] "" Vector__XXX

BO_ 2364649470 HVESP3D1: 8 Vector__XXX
 SG_ Hvesp3AvailableDischargePower : 0|16@1+ (0.05,0) [0|3212.75] "kW" Vector__XXX
 SG_ Hvesp3AvailableChargePower : 16|16@1+ (0.05,0) [0|3212.75] "kW" Vector__XXX
 SG_ Hvesp3VoltageLevel : 32|16@1+ (0.05,0) [0|3212.75] "V" Vector__XXX
 SG_ Hvesp3Current : 48|16@1+ (0.05,-1600) [-1600|1612.75] "A" Vector__XXX

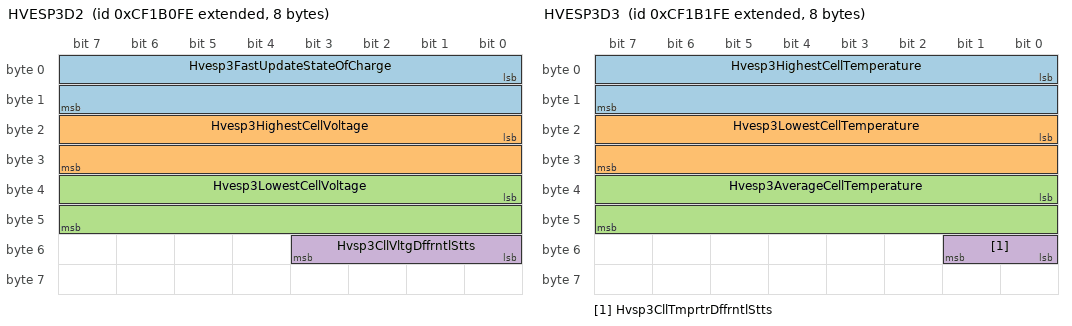
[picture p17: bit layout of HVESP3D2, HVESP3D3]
BO_ 2364649726 HVESP3D2: 8 Vector__XXX
 SG_ Hvesp3FastUpdateStateOfCharge : 0|16@1+ (0.0015625,0) [0|100.3984375] "%" Vector__XXX
 SG_ Hvesp3HighestCellVoltage : 16|16@1+ (0.001,0) [0|64.255] "V" Vector__XXX
 SG_ Hvesp3LowestCellVoltage : 32|16@1+ (0.001,0) [0|64.255] "V" Vector__XXX
 SG_ Hvsp3CllVltgDffrntlStts : 48|4@1+ (1,0) [0|15] "" Vector__XXX

BO_ 2364649982 HVESP3D3: 8 Vector__XXX
 SG_ Hvesp3HighestCellTemperature : 0|16@1+ (0.03125,-273) [-273|1734.96875] "degC" Vector__XXX
 SG_ Hvesp3LowestCellTemperature : 16|16@1+ (0.03125,-273) [-273|1734.96875] "degC" Vector__XXX
 SG_ Hvesp3AverageCellTemperature : 32|16@1+ (0.03125,-273) [-273|1734.96875] "degC" Vector__XXX
 SG_ Hvsp3CllTmprtrDffrntlStts : 48|2@1+ (1,0) [0|3] "" Vector__XXX

BO_ 2364650238 HVESP3D4: 8 Vector__XXX
 SG_ Hvesp3DischargeCapacity : 0|16@1+ (0.01,0) [0|642.55] "Ah" Vector__XXX
 SG_ Hvesp3ChargeCapacity : 16|16@1+ (0.01,0) [0|642.55] "Ah" Vector__XXX
 SG_ Hvesp3CellBalancingCount : 32|16@1+ (1,0) [0|64255] "count" Vector__XXX

BO_ 2364650494 HVESP3D5: 8 Vector__XXX
 SG_ Hvesp3LowestCellStateOfCharge : 32|16@1+ (0.0015625,0) [0|100.3984375] "%" Vector__XXX
 SG_ Hvesp3HighestCellStateOfCharge : 48|16@1+ (0.0015625,0) [0|100.3984375] "%" Vector__XXX
 SG_ Hvsp3MxmmInstntnsDshrgCrrntLmt : 0|16@1+ (0.05,-1600) [-1600|0] "A" Vector__XXX
 SG_ Hvsp3MxmmInstntnsChrgCrrntLmt : 16|16@1+ (0.05,-1600) [0|1612.75] "A" Vector__XXX

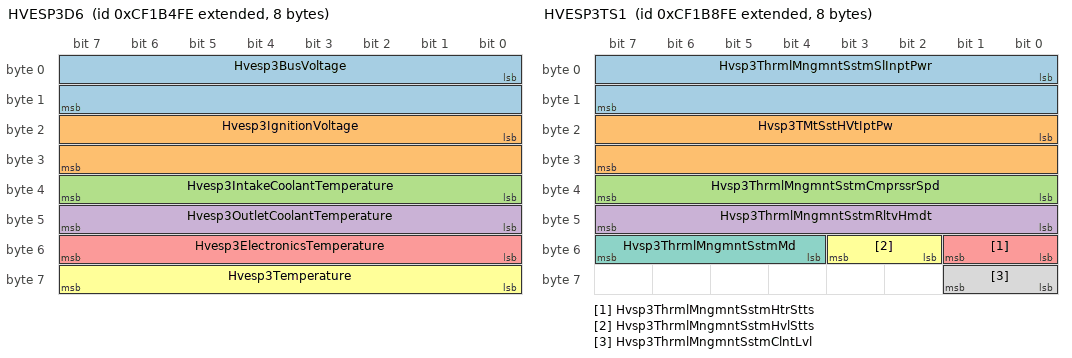
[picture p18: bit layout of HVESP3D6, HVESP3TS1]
BO_ 2364650750 HVESP3D6: 8 Vector__XXX
 SG_ Hvesp3BusVoltage : 0|16@1+ (0.05,0) [0|3212.75] "V" Vector__XXX
 SG_ Hvesp3IgnitionVoltage : 16|16@1+ (0.01,0) [0|642.55] "V" Vector__XXX
 SG_ Hvesp3IntakeCoolantTemperature : 32|8@1+ (1,-40) [-40|210] "degC" Vector__XXX
 SG_ Hvesp3OutletCoolantTemperature : 40|8@1+ (1,-40) [-40|210] "degC" Vector__XXX
 SG_ Hvesp3ElectronicsTemperature : 48|8@1+ (1,-40) [-40|210] "degC" Vector__XXX
 SG_ Hvesp3Temperature : 56|8@1+ (1,-40) [-40|210] "degC" Vector__XXX

BO_ 2364651006 HVESP3S1: 8 Vector__XXX
 SG_ Hvesp3HvilStatus : 20|2@1+ (1,0) [0|3] "" Vector__XXX
 SG_ Hvesp3InertiaSwitchStatus : 22|2@1+ (1,0) [0|3] "" Vector__XXX
 SG_ Hvesp3StateOfChargeStatus : 24|4@1+ (1,0) [0|15] "" Vector__XXX
 SG_ Hvesp3CellBalanceStatus : 28|2@1+ (1,0) [0|3] "" Vector__XXX
 SG_ Hvesp3CellBalancingActive : 30|2@1+ (1,0) [0|3] "" Vector__XXX
 SG_ Hvesp3InternalChargerStatus : 32|2@1+ (1,0) [0|3] "" Vector__XXX
 SG_ Hvesp3OperationalStatus : 44|4@1+ (1,0) [0|15] "" Vector__XXX
 SG_ Hvesp3Status1Counter : 52|4@1+ (1,0) [0|15] "" Vector__XXX
 SG_ Hvesp3Status1Crc : 56|8@1+ (1,0) [0|250] "count" Vector__XXX
 SG_ Hvsp3HghVltgBsPstvCnttrStt : 0|2@1+ (1,0) [0|3] "" Vector__XXX
 SG_ Hvsp3HghVltgBsNgtvCnttrStt : 2|2@1+ (1,0) [0|3] "" Vector__XXX
 SG_ Hvsp3HghVltgBsDsnntFrwrnng : 4|4@1+ (1,0) [0|15] "" Vector__XXX
 SG_ Hvsp3HghVltgBsPrChrgRlStt : 8|2@1+ (1,0) [0|3] "" Vector__XXX
 SG_ Hvsp3CntrOfPkCnttrStt : 10|2@1+ (1,0) [0|3] "" Vector__XXX
 SG_ Hvsp3HghVltgBsAtvIsltnTstStts : 12|4@1+ (1,0) [0|15] "" Vector__XXX
 SG_ Hvsp3HghVltgBsPssvIsltnTstStts : 16|4@1+ (1,0) [0|15] "" Vector__XXX
 SG_ Hvsp3HghVltgBsCnntnStts : 40|4@1+ (1,0) [0|15] "" Vector__XXX

BO_ 2364651262 HVESP3D7: 8 Vector__XXX
 SG_ Hvesp3DischargeEnergyCapacity : 0|24@1+ (0.001,0) [0|16449.535] "kWh" Vector__XXX
 SG_ Hvesp3ChargeEnergyCapacity : 24|24@1+ (0.001,0) [0|16449.535] "kWh" Vector__XXX
 SG_ Hvesp3MaximumChargeVoltageLimit : 48|16@1+ (0.05,0) [0|3212.75] "V" Vector__XXX

BO_ 2364651518 HVESP3MS1: 8 Vector__XXX
 SG_ Hvesp3Module1OperationalStatus : 0|2@1+ (1,0) [0|3] "" Vector__XXX
 SG_ Hvesp3Module2OperationalStatus : 2|2@1+ (1,0) [0|3] "" Vector__XXX
 SG_ Hvesp3Module3OperationalStatus : 4|2@1+ (1,0) [0|3] "" Vector__XXX
 SG_ Hvesp3Module4OperationalStatus : 6|2@1+ (1,0) [0|3] "" Vector__XXX
 SG_ Hvesp3Module5OperationalStatus : 8|2@1+ (1,0) [0|3] "" Vector__XXX
 SG_ Hvesp3Module6OperationalStatus : 10|2@1+ (1,0) [0|3] "" Vector__XXX
 SG_ Hvesp3Module7OperationalStatus : 12|2@1+ (1,0) [0|3] "" Vector__XXX
 SG_ Hvesp3Module8OperationalStatus : 14|2@1+ (1,0) [0|3] "" Vector__XXX
 SG_ Hvesp3Module9OperationalStatus : 16|2@1+ (1,0) [0|3] "" Vector__XXX
 SG_ Hvesp3Module10OperationalStatus : 18|2@1+ (1,0) [0|3] "" Vector__XXX
 SG_ Hvesp3Module11OperationalStatus : 20|2@1+ (1,0) [0|3] "" Vector__XXX
 SG_ Hvesp3Module12OperationalStatus : 22|2@1+ (1,0) [0|3] "" Vector__XXX
 SG_ Hvesp3Module13OperationalStatus : 24|2@1+ (1,0) [0|3] "" Vector__XXX
 SG_ Hvesp3Module14OperationalStatus : 26|2@1+ (1,0) [0|3] "" Vector__XXX
 SG_ Hvesp3Module15OperationalStatus : 28|2@1+ (1,0) [0|3] "" Vector__XXX
 SG_ Hvesp3Module16OperationalStatus : 30|2@1+ (1,0) [0|3] "" Vector__XXX
 SG_ Hvesp3Module17OperationalStatus : 32|2@1+ (1,0) [0|3] "" Vector__XXX
 SG_ Hvesp3Module18OperationalStatus : 34|2@1+ (1,0) [0|3] "" Vector__XXX
 SG_ Hvesp3Module19OperationalStatus : 36|2@1+ (1,0) [0|3] "" Vector__XXX
 SG_ Hvesp3Module20OperationalStatus : 38|2@1+ (1,0) [0|3] "" Vector__XXX
 SG_ Hvesp3Module21OperationalStatus : 40|2@1+ (1,0) [0|3] "" Vector__XXX
 SG_ Hvesp3Module22OperationalStatus : 42|2@1+ (1,0) [0|3] "" Vector__XXX
 SG_ Hvesp3Module23OperationalStatus : 44|2@1+ (1,0) [0|3] "" Vector__XXX
 SG_ Hvesp3Module24OperationalStatus : 46|2@1+ (1,0) [0|3] "" Vector__XXX
 SG_ Hvesp3Module25OperationalStatus : 48|2@1+ (1,0) [0|3] "" Vector__XXX
 SG_ Hvesp3Module26OperationalStatus : 50|2@1+ (1,0) [0|3] "" Vector__XXX
 SG_ Hvesp3Module27OperationalStatus : 52|2@1+ (1,0) [0|3] "" Vector__XXX
 SG_ Hvesp3Module28OperationalStatus : 54|2@1+ (1,0) [0|3] "" Vector__XXX
 SG_ Hvesp3Module29OperationalStatus : 56|2@1+ (1,0) [0|3] "" Vector__XXX
 SG_ Hvesp3Module30OperationalStatus : 58|2@1+ (1,0) [0|3] "" Vector__XXX
 SG_ Hvesp3Module31OperationalStatus : 60|2@1+ (1,0) [0|3] "" Vector__XXX
 SG_ Hvesp3Module32OperationalStatus : 62|2@1+ (1,0) [0|3] "" Vector__XXX

BO_ 2364651774 HVESP3TS1: 8 Vector__XXX
 SG_ Hvsp3ThrmlMngmntSstmSlInptPwr : 0|16@1+ (0.5,0) [0|32127.5] "W" Vector__XXX
 SG_ Hvsp3TMtSstHVtIptPw : 16|16@1+ (0.5,0) [0|32127.5] "W" Vector__XXX
 SG_ Hvsp3ThrmlMngmntSstmCmprssrSpd : 32|8@1+ (32,0) [0|8000] "rpm" Vector__XXX
 SG_ Hvsp3ThrmlMngmntSstmRltvHmdt : 40|8@1+ (0.4,0) [0|100] "%" Vector__XXX
 SG_ Hvsp3ThrmlMngmntSstmHtrStts : 48|2@1+ (1,0) [0|3] "" Vector__XXX
 SG_ Hvsp3ThrmlMngmntSstmHvlStts : 50|2@1+ (1,0) [0|3] "" Vector__XXX
 SG_ Hvsp3ThrmlMngmntSstmMd : 52|4@1+ (1,0) [0|15] "" Vector__XXX
 SG_ Hvsp3ThrmlMngmntSstmClntLvl : 56|2@1+ (1,0) [0|3] "" Vector__XXX

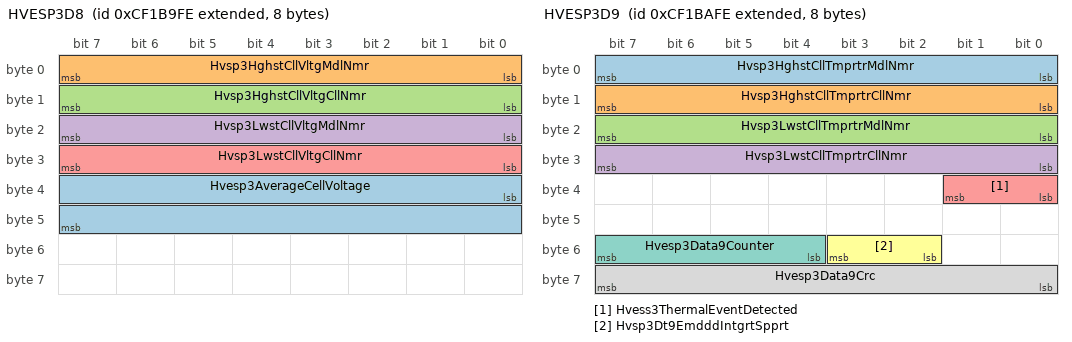
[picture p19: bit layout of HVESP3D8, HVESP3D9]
BO_ 2364652030 HVESP3D8: 8 Vector__XXX
 SG_ Hvesp3AverageCellVoltage : 32|16@1+ (0.001,0) [0|64.255] "V" Vector__XXX
 SG_ Hvsp3HghstCllVltgMdlNmr : 0|8@1+ (1,0) [0|250] "count" Vector__XXX
 SG_ Hvsp3HghstCllVltgCllNmr : 8|8@1+ (1,0) [0|250] "count" Vector__XXX
 SG_ Hvsp3LwstCllVltgMdlNmr : 16|8@1+ (1,0) [0|250] "count" Vector__XXX
 SG_ Hvsp3LwstCllVltgCllNmr : 24|8@1+ (1,0) [0|250] "count" Vector__XXX

BO_ 2364652286 HVESP3D9: 8 Vector__XXX
 SG_ Hvsp3HghstCllTmprtrMdlNmr : 0|8@1+ (1,0) [0|250] "count" Vector__XXX
 SG_ Hvsp3HghstCllTmprtrCllNmr : 8|8@1+ (1,0) [0|250] "count" Vector__XXX
 SG_ Hvsp3LwstCllTmprtrMdlNmr : 16|8@1+ (1,0) [0|250] "count" Vector__XXX
 SG_ Hvsp3LwstCllTmprtrCllNmr : 24|8@1+ (1,0) [0|250] "count" Vector__XXX
 SG_ Hvess3ThermalEventDetected : 32|2@1+ (1,0) [0|3] "" Vector__XXX
 SG_ Hvsp3Dt9EmdddIntgrtSpprt : 50|2@1+ (1,0) [0|3] "" Vector__XXX
 SG_ Hvesp3Data9Counter : 52|4@1+ (1,0) [0|15] "" Vector__XXX
 SG_ Hvesp3Data9Crc : 56|8@1+ (1,0) [0|250] "count" Vector__XXX

CM_ BO_ 2351824638 "High Voltage Energy Storage Pack 4 Control 1";
CM_ SG_ 2351824638 Hvesp4PowerDownCommand "HVESP4 Power-Down Command: Command to shut down this High Voltage Energy Storage Pack instance.  A normal power-down may involve steps that take some period of time (tests, writing of data, etc.).  However, an emergency power-down should shut down th...";
CM_ SG_ 2351824638 Hvesp4CellBalancingCommand "HVESP4 Cell Balancing Command: Command for this High Voltage Energy Storage Pack instance to perform cell balancing.This parameter is for one of multiple packs in an HVESS.  If there is only one pack in the system, the HVESS parameters should be used...";
CM_ SG_ 2351824638 Hvesp4OperationConsent "HVESP4 Operation Consent: This parameter provides an indication to this High Voltage Energy Storage Pack instance that an external device is ready for this HVES instance to proceed with normal operation.  In applications which support this parameter,...";
CM_ SG_ 2351824638 Hvesp4Control1Counter "HVESP4 Control 1 Counter: The message counter is used to detect situations where the transmitting ECU malfunction repeats the same frame all the time. The receiver of the information may use the counter parameter to detect this situation. The transmi...";
CM_ SG_ 2351824638 Hvesp4Control1Crc "HVESP4 Control 1 CRC: The CRC is defined as follows: - Length: 8 bits- Polynomial: x^8+x^5+x^3+x^2+x+1- Initial Value: FFh- Input Data Reflection: Not reflected- Result Data Reflection: Not reflected- XOR value: FFh SAE makes no claim of the function...";
CM_ SG_ 2351824638 Hvsp4HghVltgBsCnntCmmnd "HVESP4 High-Voltage Bus Connect Command: Command to connect this High Voltage Energy Storage Pack instance to the high-voltage bus.  The emergency contactor closure request may be used in situations where one or more faults in the hybrid or EV powert...";
CM_ SG_ 2351824638 Hvsp4HghVltgBsAtvIsltnTstCmmnd "HVESP4 High-Voltage Bus Active Isolation Test Command: Command for this High Voltage Energy Storage Pack instance to perform an active electrical isolation test on the high voltage bus.An active isolation test might use a generated signal (e.g. an in...";
CM_ SG_ 2351824638 Hvsp4HghVltgBsPssvIsltnTstCmmnd "HVESP4 High-Voltage Bus Passive Isolation Test Command: Command for this High Voltage Energy Storage Pack instance to perform a passive electrical isolation test on the high voltage bus.A passive isolation test uses additional circuitry (e.g. a high ...";
CM_ SG_ 2351824638 Hvsp4EnlIntrnlChrgrCmmnd "HVESP4 Enable Internal Charger Command: When the HVES has an internal charger this parameter will enable it.   External chargers may use the External Energy Source Connection Demand (SPN 7890) and related SPs.This parameter is for one of multiple pac...";
CM_ SG_ 2351824638 Hvsp4HVtBsHSdRsstCtRqst "HVESP4 High-Voltage Bus High Side Resistor Connect Request: This parameter is used to request connection of this HVES instance High-Voltage bus high side resistor in order to perform an isolation test.  See also SPN 11385  (HVESP4 High-Voltage Bus Lo...";
CM_ SG_ 2351824638 Hvsp4HghVltgBsLwSdRsstrCnntRqst "HVESP4 High-Voltage Bus Low Side Resistor Connect Request: This parameter is used to request connection of this HVES instance High-Voltage bus low side resistor in order to perform an isolation test.  See also SPN 11384  (HVESP4 High-Voltage Bus High...";
CM_ SG_ 2351824638 Hvsp4ThrmlMngmntMntnnRqst "HVESP4 Thermal Management Maintenance Request: Request to engage Thermal Management Maintenance Mode for this High Voltage Energy Storage System Pack instance.00b = HVESS Thermal Management Maintenance Mode is not requested01b = HVESS Thermal Managem...";
CM_ BO_ 2351890174 "High Voltage Energy Storage Pack 5 Control 1";
CM_ SG_ 2351890174 Hvesp5PowerDownCommand "HVESP5 Power-Down Command: Command to shut down this High Voltage Energy Storage Pack instance.  A normal power-down may involve steps that take some period of time (tests, writing of data, etc.).  However, an emergency power-down should shut down th...";
CM_ SG_ 2351890174 Hvesp5CellBalancingCommand "HVESP5 Cell Balancing Command: Command for this High Voltage Energy Storage Pack instance to perform cell balancing.This parameter is for one of multiple packs in an HVESS.  If there is only one pack in the system, the HVESS parameters should be used...";
CM_ SG_ 2351890174 Hvesp5OperationConsent "HVESP5 Operation Consent: This parameter provides an indication to this High Voltage Energy Storage Pack instance that an external device is ready for this HVES instance to proceed with normal operation.  In applications which support this parameter,...";
CM_ SG_ 2351890174 Hvesp5Control1Counter "HVESP5 Control 1 Counter: The message counter is used to detect situations where the transmitting ECU malfunction repeats the same frame all the time. The receiver of the information may use the counter parameter to detect this situation. The transmi...";
CM_ SG_ 2351890174 Hvesp5Control1Crc "HVESP5 Control 1 CRC: The CRC is defined as follows: - Length: 8 bits- Polynomial: x^8+x^5+x^3+x^2+x+1- Initial Value: FFh- Input Data Reflection: Not reflected- Result Data Reflection: Not reflected- XOR value: FFh SAE makes no claim of the function...";
CM_ SG_ 2351890174 Hvsp5HghVltgBsCnntCmmnd "HVESP5 High-Voltage Bus Connect Command: Command to connect this High Voltage Energy Storage Pack instance to the high-voltage bus.  The emergency contactor closure request may be used in situations where one or more faults in the hybrid or EV powert...";
CM_ SG_ 2351890174 Hvsp5HghVltgBsAtvIsltnTstCmmnd "HVESP5 High-Voltage Bus Active Isolation Test Command: Command for this High Voltage Energy Storage Pack instance to perform an active electrical isolation test on the high voltage bus.An active isolation test might use a generated signal (e.g. an in...";
CM_ SG_ 2351890174 Hvsp5HghVltgBsPssvIsltnTstCmmnd "HVESP5 High-Voltage Bus Passive Isolation Test Command: Command for this High Voltage Energy Storage Pack instance to perform a passive electrical isolation test on the high voltage bus.A passive isolation test uses additional circuitry (e.g. a high ...";
CM_ SG_ 2351890174 Hvsp5EnlIntrnlChrgrCmmnd "HVESP5 Enable Internal Charger Command: When the HVES has an internal charger this parameter will enable it.   External chargers may use the External Energy Source Connection Demand (SPN 7890) and related SPs.This parameter is for one of multiple pac...";
CM_ SG_ 2351890174 Hvsp5HVtBsHSdRsstCtRqst "HVESP5 High-Voltage Bus High Side Resistor Connect Request: This parameter is used to request connection of this HVES instance High-Voltage bus high side resistor in order to perform an isolation test.  See also SPN 11501  (HVESP5 High-Voltage Bus Lo...";
CM_ SG_ 2351890174 Hvsp5HghVltgBsLwSdRsstrCnntRqst "HVESP5 High-Voltage Bus Low Side Resistor Connect Request: This parameter is used to request connection of this HVES instance High-Voltage bus low side resistor in order to perform an isolation test.  See also SPN 11500  (HVESP5 High-Voltage Bus High...";
CM_ SG_ 2351890174 Hvsp5ThrmlMngmntMntnnRqst "HVESP5 Thermal Management Maintenance Request: Request to engage Thermal Management Maintenance Mode for this High Voltage Energy Storage System Pack instance.00b = HVESS Thermal Management Maintenance Mode is not requested01b = HVESS Thermal Managem...";
CM_ BO_ 2351955710 "High Voltage Energy Storage Pack 6 Control 1";
CM_ SG_ 2351955710 Hvesp6PowerDownCommand "HVESP6 Power-Down Command: Command to shut down this High Voltage Energy Storage Pack instance.  A normal power-down may involve steps that take some period of time (tests, writing of data, etc.).  However, an emergency power-down should shut down th...";
CM_ SG_ 2351955710 Hvesp6CellBalancingCommand "HVESP6 Cell Balancing Command: Command for this High Voltage Energy Storage Pack instance to perform cell balancing.This parameter is for one of multiple packs in an HVESS.  If there is only one pack in the system, the HVESS parameters should be used...";
CM_ SG_ 2351955710 Hvesp6OperationConsent "HVESP6 Operation Consent: This parameter provides an indication to this High Voltage Energy Storage Pack instance that an external device is ready for this HVES instance to proceed with normal operation.  In applications which support this parameter,...";
CM_ SG_ 2351955710 Hvesp6Control1Counter "HVESP6 Control 1 Counter: The message counter is used to detect situations where the transmitting ECU malfunction repeats the same frame all the time. The receiver of the information may use the counter parameter to detect this situation. The transmi...";
CM_ SG_ 2351955710 Hvesp6Control1Crc "HVESP6 Control 1 CRC: The CRC is defined as follows: - Length: 8 bits- Polynomial: x^8+x^5+x^3+x^2+x+1- Initial Value: FFh- Input Data Reflection: Not reflected- Result Data Reflection: Not reflected- XOR value: FFh SAE makes no claim of the function...";
CM_ SG_ 2351955710 Hvsp6HghVltgBsCnntCmmnd "HVESP6 High-Voltage Bus Connect Command: Command to connect this High Voltage Energy Storage Pack instance to the high-voltage bus.  The emergency contactor closure request may be used in situations where one or more faults in the hybrid or EV powert...";
CM_ SG_ 2351955710 Hvsp6HghVltgBsAtvIsltnTstCmmnd "HVESP6 High-Voltage Bus Active Isolation Test Command: Command for this High Voltage Energy Storage Pack instance to perform an active electrical isolation test on the high voltage bus.An active isolation test might use a generated signal (e.g. an in...";
CM_ SG_ 2351955710 Hvsp6HghVltgBsPssvIsltnTstCmmnd "HVESP6 High-Voltage Bus Passive Isolation Test Command: Command for this High Voltage Energy Storage Pack instance to perform a passive electrical isolation test on the high voltage bus.A passive isolation test uses additional circuitry (e.g. a high ...";
CM_ SG_ 2351955710 Hvsp6EnlIntrnlChrgrCmmnd "HVESP6 Enable Internal Charger Command: When the HVES has an internal charger this parameter will enable it.   External chargers may use the External Energy Source Connection Demand (SPN 7890) and related SPs.This parameter is for one of multiple pac...";
CM_ SG_ 2351955710 Hvsp6HVtBsHSdRsstCtRqst "HVESP6 High-Voltage Bus High Side Resistor Connect Request: This parameter is used to request connection of this HVES instance High-Voltage bus high side resistor in order to perform an isolation test.  See also SPN 11617  (HVESP6 High-Voltage Bus Lo...";
CM_ SG_ 2351955710 Hvsp6HghVltgBsLwSdRsstrCnntRqst "HVESP6 High-Voltage Bus Low Side Resistor Connect Request: This parameter is used to request connection of this HVES instance High-Voltage bus low side resistor in order to perform an isolation test.  See also SPN 11616  (HVESP6 High-Voltage Bus High...";
CM_ SG_ 2351955710 Hvsp6ThrmlMngmntMntnnRqst "HVESP6 Thermal Management Maintenance Request: Request to engage Thermal Management Maintenance Mode for this High Voltage Energy Storage System Pack instance.00b = HVESS Thermal Management Maintenance Mode is not requested01b = HVESS Thermal Managem...";
CM_ BO_ 2555641598 "EVSE Control 1";
CM_ SG_ 2555641598 EvReady "EV Ready: Informs the EVSE that the EV is ready to charge.Intended for use by systems that support multiple active power sources. If the connection to the EVSE has a control pilot signal, this parameter can be used to to switch the Control Pilot betw...";
CM_ SG_ 2555641598 EvseConnectorLockRequest "EVSE Connector Lock Request: Request to engage or disengage the locking mechanism fitted to this EVSE connector to the vehicle.The actual Lock state will be reported via SPN 12863 (EVSE1 Connector Lock State).This parameter shall be from only one sou...";
CM_ SG_ 2555641598 EvseDcStageRequest "EVSE DC Stage Request: DC EVSE Charging stage request that may be used to cycle the connection to the EVSE through various phases of the charging cycle.Some EVCC implementations will handle this sequencing internally, in which case this SP should be ...";
CM_ SG_ 2555641598 EvseContactorCommand "EVSE Contactor Command: Contactor command to control any contactors between the vehicle inlet and the internal AC or DC bus.00b = Open Contactor01b = Close Contactor10b = Reserved11b = Don't Care / Take no action";
CM_ BO_ 2555707134 "Winch Information 3";
CM_ SG_ 2555707134 WinchPositionReset "Winch Position Reset: Command to reset or zero the Winch Motor Encoder Position (SPN 12309) and Winch Revolution Counter (SPN 12310). The Winch Lifetime Revolution Counter (SPN 12311) is not reset.00b = Reset not requested01b = Reset requested10b = R...";
CM_ BO_ 2354446078 "Air Suspension Control 8";
CM_ SG_ 2354446078 LiftAxle3PositionCommand "Lift Axle 3 Position Command: Signal to command the position/load condition of lift/tag axle 3. Numbering of lift/tag axles starts at front axle.00b = Lift axle position down / tag axle laden01b = Lift axle position up / tag axle unladen10b = Reserve...";
CM_ BO_ 2354511614 "Motor/Generator 2 Inverter Control 2";
CM_ SG_ 2354511614 MtrGnrtr2InvrtrCntrl2Cntr "Motor/Generator 2 Inverter Control 2 Counter: The message counter is used to detect situations where the transmitting ECU malfunction repeats the same frame all the time. The receiver of the information may use the counter parameter to detect this si...";
CM_ SG_ 2354511614 MtrGnrtr2InvrtrCntrl2Cr "Motor/Generator 2 Inverter Control 2 CRC: The CRC is defined as follows: - Length: 8 bits- Polynomial: x^8+x^5+x^3+x^2+x+1- Initial Value: FFh- Input Data Reflection: Not reflected- Result Data Reflection: Not reflected- XOR value: FFh SAE makes no c...";
CM_ SG_ 2354511614 MtrGnrtr2InvrtrPdCntrlAppllMd "Motor/Generator 2 Inverter PID Control Applicable Mode : Defines the Mode for which the PID Gain parameters apply within this instance of the inverter. See SPN 10233 [Control Setpoint Mode] for a definition of modes for control purposes.Applicable mo...";
CM_ SG_ 2354511614 MtGt2IvtPdCtNzdDtG "Motor/Generator 2 Inverter PID Control Normalized Differential Gain: A PID controller can be parametrized by factors Kp, Ki and Kd. This parameter defines the normalized differential gain (Kdn) for control applications in this inverter instance. The ...";
CM_ SG_ 2354511614 MtGt2IvtPdCtNzdItG "Motor/Generator 2 Inverter PID Control Normalized Integral Gain: A PID controller can be parametrized by factors Kp, Ki and Kd. This parameter defines the normalized integral gain (Kin) for control applications in this inverter instance. The normaliz...";
CM_ SG_ 2354511614 MtGt2IvtPdCtNzdPptG "Motor/Generator 2 Inverter PID Control Normalized Proportional Gain: A PID controller can be parametrized by factors Kp, Ki and Kd. This parameter defines the normalized proportional gain (Kpn) for control applications in this inverter instance. The ...";
CM_ SG_ 2354511614 MtGt2IvtPdCtFdFwdTq "Motor/Generator 2 Inverter PID Control Feed-Forward Torque: A PID controller can have a Feed-Forward Torque added to its output. This parameter defines the Feed-Forward Torque Setpoint for control applications in this inverter instance. The Setpoint ...";
CM_ BO_ 2354577150 "Motor/Generator 1 Inverter Control 2";
CM_ SG_ 2354577150 MtrGnrtr1InvrtrCntrl2Cntr "Motor/Generator 1 Inverter Control 2 Counter: The message counter is used to detect situations where the transmitting ECU malfunction repeats the same frame all the time. The receiver of the information may use the counter parameter to detect this si...";
CM_ SG_ 2354577150 MtrGnrtr1InvrtrCntrl2Cr "Motor/Generator 1 Inverter Control 2 CRC: The CRC is defined as follows: - Length: 8 bits- Polynomial: x^8+x^5+x^3+x^2+x+1- Initial Value: FFh- Input Data Reflection: Not reflected- Result Data Reflection: Not reflected- XOR value: FFh SAE makes no c...";
CM_ SG_ 2354577150 MtrGnrtr1InvrtrPdCntrlAppllMd "Motor/Generator 1 Inverter PID Control Applicable Mode : Defines the Mode for which the PID Gain parameters apply within this instance of the inverter. See SPN 10167 [Control Setpoint Mode] for a definition of modes for control purposes.Applicable mo...";
CM_ SG_ 2354577150 MtGt1IvtPdCtNzdDtG "Motor/Generator 1 Inverter PID Control Normalized Differential Gain: A PID controller can be parametrized by factors Kp, Ki and Kd. This parameter defines the normalized differential gain (Kdn) for control applications in this inverter instance. The ...";
CM_ SG_ 2354577150 MtGt1IvtPdCtNzdItG "Motor/Generator 1 Inverter PID Control Normalized Integral Gain: A PID controller can be parametrized by factors Kp, Ki and Kd. This parameter defines the normalized integral gain (Kin) for control applications in this inverter instance. The normaliz...";
CM_ SG_ 2354577150 MtGt1IvtPdCtNzdPptG "Motor/Generator 1 Inverter PID Control Normalized Proportional Gain: A PID controller can be parametrized by factors Kp, Ki and Kd. This parameter defines the normalized proportional gain (Kpn) for control applications in this inverter instance. The ...";
CM_ SG_ 2354577150 MtGt1IvtPdCtFdFwdTq "Motor/Generator 1 Inverter PID Control Feed-Forward Torque: A PID controller can have a Feed-Forward Torque added to its output. This parameter defines the Feed-Forward Torque Setpoint for control applications in this inverter instance. The Setpoint ...";
CM_ BO_ 2488860414 "Hoist Command Information";
CM_ SG_ 2488860414 HoistCommand "Hoist Command: Hoist operation being requested to the control that directly controls the hoist used for a dump body.  The sign of the value indicates mode of operation (raise or lower) and the magnitude of the value indicates the speed as a percentag...";
CM_ SG_ 2488860414 HoistDetentStatus "Hoist Detent Status: Indicates the detent status for the hoist command used for a dump body.00b = Not in the Detent01b = In the Detent10b = Error Indicator11b = Not Available";
CM_ BO_ 2556034814 "Motor/Generator 2 Inverter Isolation Integrity Request";
CM_ SG_ 2556034814 MtGt2IvtHVtBsAtvIstTstCd "Motor/Generator 2 Inverter High-Voltage Bus Active Isolation Test Command: Command for the inverter to perform an active electrical isolation test on the high voltage bus.An active isolation test might use a generated signal (e.g. an injected AC sign...";
CM_ SG_ 2556034814 MtGt2IvtHVtBsPssvIstTstCd "Motor/Generator 2 Inverter High-Voltage Bus Passive Isolation Test Command: Command for the inverter to perform a passive electrical isolation test on the high voltage bus.A passive isolation test uses additional circuitry (e.g. a high impedance netw...";
CM_ SG_ 2556034814 MtGt2IvtHVtBsHSdRsstCtRqst "Motor/Generator 2 Inverter High-Voltage Bus High Side Resistor Connect Request: This parameter is used to request connection of the inverter High-Voltage bus high side resistor in order to perform an isolation test.00b = Connection not Requested01b =...";
CM_ SG_ 2556034814 MtGt2IvtHVtBsLwSdRsstCtRqst "Motor/Generator 2 Inverter High-Voltage Bus Low Side Resistor Connect Request: This parameter is used to request connection of the inverter High-Voltage bus low side resistor in order to perform an isolation test.00b = Connection not Requested01b = C...";
CM_ BO_ 2556100350 "Motor/Generator 1 Inverter Isolation Integrity Request";
CM_ SG_ 2556100350 MtGt1IvtHVtBsAtvIstTstCd "Motor/Generator 1 Inverter High-Voltage Bus Active Isolation Test Command: Command for the inverter to perform an active electrical isolation test on the high voltage bus.An active isolation test might use a generated signal (e.g. an injected AC sign...";
CM_ SG_ 2556100350 MtGt1IvtHVtBsPssvIstTstCd "Motor/Generator 1 Inverter High-Voltage Bus Passive Isolation Test Command: Command for the inverter to perform a passive electrical isolation test on the high voltage bus.A passive isolation test uses additional circuitry (e.g. a high impedance netw...";
CM_ SG_ 2556100350 MtGt1IvtHVtBsHSdRsstCtRqst "Motor/Generator 1 Inverter High-Voltage Bus High Side Resistor Connect Request: This parameter is used to request connection of the inverter High-Voltage bus high side resistor in order to perform an isolation test. 00b = Connection not Requested01b ...";
CM_ SG_ 2556100350 MtGt1IvtHVtBsLwSdRsstCtRqst "Motor/Generator 1 Inverter High-Voltage Bus Low Side Resistor Connect Request: This parameter is used to request connection of the inverter High-Voltage bus low side resistor in order to perform an isolation test.  00b = Connection not Requested01b =...";
CM_ BO_ 2565966846 "Motor/Generator 1 Inverter Status 2";
CM_ SG_ 2565966846 MtrGnrtr1InvrtrStts2Cntr "Motor/Generator 1 Inverter Status 2 Counter: The message counter is used to detect situations where the transmitting ECU malfunction repeats the same frame all the time. The receiver of the information may use the counter parameter to detect this sit...";
CM_ SG_ 2565966846 MtrGnrtr1AvllMxmmTrq "Motor/Generator 1 Available Maximum Torque: This is an estimate of the maximum available motor torque including active deratings at the present motor speed.  This refers to the motor rotor output and excludes any gearbox that may be attached to the m...";
CM_ SG_ 2565966846 MtrGnrtr1AvllMnmmTrq "Motor/Generator 1 Available Minimum Torque: This is an estimate of the minimum available motor torque including active deratings at the present motor speed.  This refers to the motor rotor output and excludes any gearbox that may be attached to the m...";
CM_ SG_ 2565966846 MtrGnrtr1InvrtrStts2Cr "Motor/Generator 1 Inverter Status 2 CRC: The CRC is defined as follows: - Length: 8 bits- Polynomial: x^8+x^5+x^3+x^2+x+1- Initial Value: FFh- Input Data Reflection: Not reflected- Result Data Reflection: Not reflected- XOR value: FFh SAE makes no cl...";
CM_ BO_ 2565967102 "Motor/Generator 1 Inverter Rate Limits Active 1";
CM_ SG_ 2565967102 MtrGnrtr1InvrtrRtLmtsAtv1Cntr "Motor/Generator 1 Inverter Rate Limits Active 1 Counter: The message counter is used to detect situations where the transmitting ECU malfunction repeats the same frame all the time. The receiver of the information may use the counter parameter to det...";
CM_ SG_ 2565967102 MtGt1IvtRtLtsAtvAstSpdRtLt "Motor/Generator 1 Inverter Rate Limits Active Absolute Speed Rate Limit: The active maximum rate of change for the absolute motor speed  (i.e. |d(speed)|/dt) in all control modes of this motor/generator inverter instance. Refer to SPN 10171 [Referenc...";
CM_ SG_ 2565967102 MtGt1IvtRtLtsAtvAstTqRtLt "Motor/Generator 1 Inverter Rate Limits Active Absolute Torque Rate Limit: The active maximum rate of change for the absolute motor torque (i.e. |d(torque)|/dt) in all control modes of this motor/generator inverter instance. Refer to SPN 10170 [Refere...";
CM_ SG_ 2565967102 MtrGnrtr1InvrtrRtLmtsAtv1Cr "Motor/Generator 1 Inverter Rate Limits Active 1 CRC: The CRC is defined as follows: - Length: 8 bits- Polynomial: x^8+x^5+x^3+x^2+x+1- Initial Value: FFh- Input Data Reflection: Not reflected- Result Data Reflection: Not reflected- XOR value: FFh SAE...";
CM_ BO_ 2565967358 "Motor/Generator 2 Inverter Status 2";
CM_ SG_ 2565967358 MtrGnrtr2InvrtrStts2Cntr "Motor/Generator 2 Inverter Status 2 Counter: The message counter is used to detect situations where the transmitting ECU malfunction repeats the same frame all the time. The receiver of the information may use the counter parameter to detect this sit...";
CM_ SG_ 2565967358 MtrGnrtr2AvllMxmmTrq "Motor/Generator 2 Available Maximum Torque: This is an estimate of the maximum available motor torque including active deratings at the present motor speed.  This refers to the motor rotor output and excludes any gearbox that may be attached to the m...";
CM_ SG_ 2565967358 MtrGnrtr2AvllMnmmTrq "Motor/Generator 2 Available Minimum Torque: This is an estimate of the minimum available motor torque including active deratings at the present motor speed.  This refers to the motor rotor output and excludes any gearbox that may be attached to the m...";
CM_ SG_ 2565967358 MtrGnrtr2InvrtrStts2Cr "Motor/Generator 2 Inverter Status 2 CRC: The CRC is defined as follows: - Length: 8 bits- Polynomial: x^8+x^5+x^3+x^2+x+1- Initial Value: FFh- Input Data Reflection: Not reflected- Result Data Reflection: Not reflected- XOR value: FFh SAE makes no cl...";
CM_ BO_ 2565967614 "Motor/Generator 2 Inverter Rate Limits Active 1";
CM_ SG_ 2565967614 MtrGnrtr2InvrtrRtLmtsAtv1Cntr "Motor/Generator 2 Inverter Rate Limits Active 1 Counter: The message counter is used to detect situations where the transmitting ECU malfunction repeats the same frame all the time. The receiver of the information may use the counter parameter to det...";
CM_ SG_ 2565967614 MtGt2IvtRtLtsAtvAstSpdRtLt "Motor/Generator 2 Inverter Rate Limits Active Absolute Speed Rate Limit: The Inverter reports its active maximum rate of change for the absolute motor speed  (i.e. |d(speed)|/dt) in all control modes. Refer to SPN 10237 [Reference Speed] to convert %...";
CM_ SG_ 2565967614 MtGt2IvtRtLtsAtvAstTqRtLt "Motor/Generator 2 Inverter Rate Limits Active Absolute Torque Rate Limit: The inverter reports its active maximum rate of change for the absolute motor torque (i.e. |d(torque)|/dt) in all control modes. Refer to SPN 10236 [Reference Torque] to conver...";
CM_ SG_ 2565967614 MtrGnrtr2InvrtrRtLmtsAtv1Cr "Motor/Generator 2 Inverter Rate Limits Active 1 CRC: The CRC is defined as follows: - Length: 8 bits- Polynomial: x^8+x^5+x^3+x^2+x+1- Initial Value: FFh- Input Data Reflection: Not reflected- Result Data Reflection: Not reflected- XOR value: FFh SAE...";
CM_ BO_ 2297532414 "Impostor PG Alert";
CM_ SG_ 2297532414 ImpostorPgEventDetectionCounter "Impostor PG Event Detection Counter: For a given detected impostor PG being reported on, this parameter indicates the number of impostor message sequences that have been detected by the legitimate sender since the counter was last reset.The counter i...";
CM_ SG_ 2297532414 ImpostorPgSourceAddress "Impostor PG Source Address: Indicates the source address from which an impostor is broadcasting the detected PG. If no impostor PG(s) have been detected, this parameter shall be set to a value of 254.";
CM_ SG_ 2297532414 ImpostorPgDestinationAddress "Impostor PG Destination Address: Indicates the destination address to which the impostor is broadcasting the detected PG. If no impostor PG(s) have been detected, this parameter shall be set to a value of 254.";
CM_ SG_ 2297532414 ImpostorPgn "Impostor PGN: This parameter identifies an unexpected duplicate PG (message) being broadcast from a source address that is already rightfully claimed. If no impostor PG(s) have been detected, each byte of this parameter shall be set to a value of 255...";
CM_ SG_ 2297532414 TimeSinceLastImpostorPgDetected "Time Since Last Impostor PG Detected: For the given impostor PG being reported on, this parameter indicates how much time has elapsed since the impostor PG instance was last detected during the current ECU power cycle, i.e. when the last attack ended...";
CM_ BO_ 2364641534 "High Voltage Energy Storage Pack 1 Status 2";
CM_ SG_ 2364641534 Hvsp1DshrgPwrLmtDTSttOfChrg "HVESP1 Discharge Power Limit Due to State of Charge: Indicates whether or not discharge power of this HVES instance is being limited due to state of charge.This parameter is for one of multiple packs in an HVESS.  If there is only one pack in the sys...";
CM_ SG_ 2364641534 Hvsp1DshrgPwrLmtDTBttrTmprtr "HVESP1 Discharge Power Limit Due to Battery Temperature: Indicates whether or not discharge power of this HVES instance is being limited due to battery temperature.This parameter is for one of multiple packs in an HVESS.  If there is only one pack in...";
CM_ SG_ 2364641534 Hvsp1DsPwLtDTBttDstCdt "HVESP1 Discharge Power Limit Due to Battery Diagnostic Condition: Indicates whether or not discharge power of this HVES instance is being limited due to a battery diagnostic condition.This parameter is for one of multiple packs in an HVESS.  If there...";
CM_ SG_ 2364641534 Hvsp1DshrgPwrLmtDTBttrOrCllVltg "HVESP1 Discharge Power Limit Due to Battery or Cell Voltage: Indicates whether or not discharge power of this HVES instance is being limited due to a battery or cell voltage level.This parameter is for one of multiple packs in an HVESS.  If there is ...";
CM_ SG_ 2364641534 Hvsp1DshrgPwrLmtDTBttrCrrnt "HVESP1 Discharge Power Limit Due to Battery Current: Indicates whether or not discharge power of this HVES instance is being limited due to battery current.This parameter is for one of multiple packs in an HVESS.  If there is only one pack in the sys...";
CM_ SG_ 2364641534 Hvsp1DshrgPwrLmtDTAnUndfndCs "HVESP1 Discharge Power Limit Due to an Undefined Cause: Indicates whether or not discharge power of this HVES instance is being limited due to an undefined cause.This parameter is for one of multiple packs in an HVESS.  If there is only one pack in t...";
CM_ SG_ 2364641534 Hvsp1ChrgPwrLmtDTSttOfChrg "HVESP1 Charge Power Limit Due to State of Charge: Indicates whether or not charge power of this HVES instance is being limited due to state of charge.This parameter is for one of multiple packs in an HVESS.  If there is only one pack in the system, t...";
CM_ SG_ 2364641534 Hvsp1ChrgPwrLmtDTBttrTmprtr "HVESP1 Charge Power Limit Due to Battery Temperature: Indicates whether or not charge power of this HVES instance is being limited due to battery temperature.This parameter is for one of multiple packs in an HVESS.  If there is only one pack in the s...";
CM_ SG_ 2364641534 Hvsp1ChrgPwrLmtDTBttrDgnstCndtn "HVESP1 Charge Power Limit Due to Battery Diagnostic Condition: Indicates whether or not charge power of this HVES instance is being limited due to a battery diagnostic condition.This parameter is for one of multiple packs in an HVESS.  If there is on...";
CM_ SG_ 2364641534 Hvsp1ChrgPwrLmtDTBttrOrCllVltg "HVESP1 Charge Power Limit Due to Battery or Cell Voltage: Indicates whether or not charge power of this HVES instance is being limited due to a battery or cell voltage level.This parameter is for one of multiple packs in an HVESS.  If there is only o...";
CM_ SG_ 2364641534 Hvsp1ChrgPwrLmtDTBttrCrrnt "HVESP1 Charge Power Limit Due to Battery Current: Indicates whether or not charge power of this HVES instance is being limited due to battery current.This parameter is for one of multiple packs in an HVESS.  If there is only one pack in the system, t...";
CM_ SG_ 2364641534 Hvsp1ChrgPwrLmtDTAnUndfndCs "HVESP1 Charge Power Limit Due to an Undefined Cause: Indicates whether or not charge power of this HVES instance is being limited due to an undefined cause.This parameter is for one of multiple packs in an HVESS.  If there is only one pack in the sys...";
CM_ BO_ 2364641790 "High Voltage Energy Storage Pack 1 Data 1";
CM_ SG_ 2364641790 Hvesp1AvailableDischargePower "HVESP1 Available Discharge Power: The rate at which this High Voltage Energy Storage Pack instance can currently provide energy for propulsion or other uses.This parameter is for one of multiple packs in an HVESS.  If there is only one pack in the sy...";
CM_ SG_ 2364641790 Hvesp1AvailableChargePower "HVESP1 Available Charge Power: The rate at which this High Voltage Energy Storage Pack instance can currently receive energy from a regenerative or recharging system.This parameter is for one of multiple packs in an HVESS.  If there is only one pack ...";
CM_ SG_ 2364641790 Hvesp1VoltageLevel "HVESP1 Voltage Level: The voltage level of this High Voltage Energy Storage Pack instance. This parameter should be synchronized with SPN 11053 (HVESP1 Current) such that a realized power value can be calculated.  If the HVES component physically con...";
CM_ SG_ 2364641790 Hvesp1Current "HVESP1 Current: The current in or out of this High Voltage Energy Storage Pack instance. This parameter should be synchronized with SPN 11052 (HVESP1 Voltage Level) such that a realized power value can be calculated.  This parameter is defined from t...";
CM_ BO_ 2364642046 "High Voltage Energy Storage Pack 1 Data 2";
CM_ SG_ 2364642046 Hvesp1FastUpdateStateOfCharge "HVESP1 Fast Update State of Charge: Indicates this High Voltage Energy Storage Pack instance state of charge.  0% means no charge remaining, 100% means the system is fully charged in terms of physical limits of this energy storage pack instance.  Acc...";
CM_ SG_ 2364642046 Hvesp1HighestCellVoltage "HVESP1 Highest Cell Voltage: The highest voltage level reported by any cell in this High Voltage Energy Storage Pack instance. If a single voltage sensor covers more than one cell, the value in this parameter is for the smallest group of cells measur...";
CM_ SG_ 2364642046 Hvesp1LowestCellVoltage "HVESP1 Lowest Cell Voltage: The lowest voltage level reported by any cell in this High Voltage Energy Storage Pack instance. If a single voltage sensor covers more than one cell, the value in this parameter is for the smallest group of cells measured...";
CM_ SG_ 2364642046 Hvsp1CllVltgDffrntlStts "HVESP1 Cell Voltage Differential Status: Indicates whether or not the differential between the highest and lowest cell voltages are within acceptable limits, according to this High Voltage Energy Storage Pack instance. The actual voltage differential...";
CM_ BO_ 2364642302 "High Voltage Energy Storage Pack 1 Data 3";
CM_ SG_ 2364642302 Hvesp1HighestCellTemperature "HVESP1 Highest Cell Temperature: The highest temperature level reported by any cell in this High Voltage Energy Storage Pack instance.  If a single temperature sensor covers more than one cell, the value in this parameter is for the smallest group of...";
CM_ SG_ 2364642302 Hvesp1LowestCellTemperature "HVESP1 Lowest Cell Temperature: The lowest temperature level reported by any cell in this High Voltage Energy Storage Pack instance.  If a single temperature sensor covers more than one cell, the value in this parameter is for the smallest group of c...";
CM_ SG_ 2364642302 Hvesp1AverageCellTemperature "HVESP1 Average Cell Temperature: The average temperature level of all cells in this High Voltage Energy Storage Pack instance.This parameter is for one of multiple packs in an HVESS.  If there is only one pack in the system, the HVESS parameters shou...";
CM_ SG_ 2364642302 Hvsp1CllTmprtrDffrntlStts "HVESP1 Cell Temperature Differential Status: Indicates whether or not the differential between the highest and lowest cell temperatures are within acceptable limits per this High Voltage Energy Storage Pack instance.  The actual temperature different...";
CM_ BO_ 2364642558 "High Voltage Energy Storage Pack 1 Data 4";
CM_ SG_ 2364642558 Hvesp1DischargeCapacity "HVESP1 Discharge Capacity: The amount of stored electrical charge in this High Voltage Energy Storage Pack instance that is available for use by the hybrid or EV system, i.e. 'how full is the tank'.  See SPN 11090 (HVESP1 Discharge Energy Capacity) f...";
CM_ SG_ 2364642558 Hvesp1ChargeCapacity "HVESP1 Charge Capacity: The amount of unused electrical charge storage in this High Voltage Energy Storage Pack instance that is available to be filled by charging, i.e. 'how much empty space is remaining in the tank'.  See SPN 11091 (HVESP1 Charge E...";
CM_ SG_ 2364642558 Hvesp1CellBalancingCount "HVESP1 Cell Balancing Count: The number of cells that are currently being balanced in this High Voltage Energy Storage Pack instance.This parameter is for one of multiple packs in an HVESS.  If there is only one pack in the system, the HVESS paramete...";
CM_ BO_ 2364642814 "High Voltage Energy Storage Pack 1 Data 5";
CM_ SG_ 2364642814 Hvesp1LowestCellStateOfCharge "HVESP1 Lowest Cell State of Charge: Indicates the state of charge of the lowest-charged cell in this High Voltage Energy Storage Pack instance.  0% means no charge remaining, 100% means the cell is fully charged.   If a single state of charge value c...";
CM_ SG_ 2364642814 Hvesp1HighestCellStateOfCharge "HVESP1 Highest Cell State of Charge: Indicates the state of charge of the highest-charged cell in this High Voltage Energy Storage Pack instance.  0% means no charge remaining, 100% means the cell is fully charged.  If a single state of charge value ...";
CM_ SG_ 2364642814 Hvsp1MxmmInstntnsDshrgCrrntLmt "HVESP1 Maximum Instantaneous Discharge Current Limit: The maximum instantaneous current flow limit out of this High Voltage Energy Storage Pack instance. This parameter is defined from the high voltage energy storage pack's point of view and should r...";
CM_ SG_ 2364642814 Hvsp1MxmmInstntnsChrgCrrntLmt "HVESP1 Maximum Instantaneous Charge Current Limit: The maximum instantaneous current flow limit into this High Voltage Energy Storage Pack instance. This parameter is defined from the high voltage energy storage pack's point of view and should reflec...";
CM_ BO_ 2364643070 "High Voltage Energy Storage Pack 1 Data 6";
CM_ SG_ 2364643070 Hvesp1BusVoltage "HVESP1 Bus Voltage: The voltage level of the high voltage bus, as measured by this High Voltage Energy Storage Pack instance on the bus side (not the battery side) of its contactors.This parameter is for one of multiple packs in an HVESS.  If there i...";
CM_ SG_ 2364643070 Hvesp1IgnitionVoltage "HVESP1 Ignition Voltage: The voltage level at the ignition input of this High Voltage Energy Storage Pack controller.This parameter is for one of multiple packs in an HVESS.  If there is only one pack in the system, the HVESS parameters should be use...";
CM_ SG_ 2364643070 Hvesp1IntakeCoolantTemperature "HVESP1 Intake Coolant Temperature: The temperature of liquid coolant as it enters this High Voltage Energy Storage Pack instance.This parameter is for one of multiple packs in an HVESS.  If there is only one pack in the system, the HVESS parameters s...";
CM_ SG_ 2364643070 Hvesp1OutletCoolantTemperature "HVESP1 Outlet Coolant Temperature: The temperature of liquid coolant as it exits this High Voltage Energy Storage Pack instance.This parameter is for one of multiple packs in an HVESS.  If there is only one pack in the system, the HVESS parameters sh...";
CM_ SG_ 2364643070 Hvesp1ElectronicsTemperature "HVESP1 Electronics Temperature: The temperature of the electronics or control modules in this High Voltage Energy Storage Pack instance.  If there are multiple temperature sensors then this parameter would be set to the maximum sensor reading.This pa...";
CM_ SG_ 2364643070 Hvesp1Temperature "HVESP1 Temperature: The temperature of this High Voltage Energy Storage Pack instance. The value may be determined from a unique sensor specifically for this purpose, or by aggregating various temperature sensor readings within the pack.This paramete...";
CM_ BO_ 2364643326 "High Voltage Energy Storage Pack 1 Status 1";
CM_ SG_ 2364643326 Hvesp1HvilStatus "HVESP1 HVIL Status: Status of the High Voltage Interlock Loop from the viewpoint of this High Voltage Energy Storage Pack instance.This parameter is for one of multiple packs in an HVESS. If there is only one pack in the system, the HVESS parameters ...";
CM_ SG_ 2364643326 Hvesp1InertiaSwitchStatus "HVESP1 Inertia Switch Status: Switch indicating that an impact has been sensed by this High Voltage Energy Storage Pack instance. The impact indication may require action by another controller, or by this HVES instance itself.  For example, a control...";
CM_ SG_ 2364643326 Hvesp1StateOfChargeStatus "HVESP1 State of Charge Status: Status of this High Voltage Energy Storage Pack instance State of Charge (SOC).  Note:  A given HVES controller may not support all of the states.This parameter is for one of multiple packs in an HVESS.  If there is onl...";
CM_ SG_ 2364643326 Hvesp1CellBalanceStatus "HVESP1 Cell Balance Status: Indicates whether or not the cells in this High Voltage Energy Storage Pack instance are balanced.This parameter is for one of multiple packs in an HVESS.  If there is only one pack in the system, the HVESS parameters shou...";
CM_ SG_ 2364643326 Hvesp1CellBalancingActive "HVESP1 Cell Balancing Active: Indicates whether or not the cells in this High Voltage Energy Storage Pack instance are currently being balanced.This parameter is for one of multiple packs in an HVESS.  If there is only one pack in the system, the HVE...";
CM_ SG_ 2364643326 Hvesp1InternalChargerStatus "HVESP1 Internal Charger Status: Indicates that the charger in this HVES instance is on.  External chargers may use the External Energy Source Connection Status (SPN 7898) and related SPs.This parameter is for one of multiple packs in an HVESS. If the...";
CM_ SG_ 2364643326 Hvesp1OperationalStatus "HVESP1 Operational Status: Provides feedback on where this High Voltage Energy Storage Pack instance is in its operating spectrum, and includes feedback in response to the Operation Consent [i.e. SPN 11035 (HVESP1 Operation Consent)] and Power Down C...";
CM_ SG_ 2364643326 Hvesp1Status1Counter "HVESP1 Status 1 Counter: The message counter is used to detect situations where the transmitting ECU malfunction repeats the same frame all the time. The receiver of the information may use the counter parameter to detect this situation. The transmit...";
CM_ SG_ 2364643326 Hvesp1Status1Crc "HVESP1 Status 1 CRC: The CRC is defined as follows: - Length: 8 bits- Polynomial: x^8+x^5+x^3+x^2+x+1- Initial Value: FFh- Input Data Reflection: Not reflected- Result Data Reflection: Not reflected- XOR value: FFh SAE makes no claim of the functiona...";
CM_ SG_ 2364643326 Hvsp1HghVltgBsPstvCnttrStt "HVESP1 High-Voltage Bus (Positive) Contactor State: Position of this High Voltage Energy Storage Pack instance positive side bus contactor.  When this contactor is closed, the positive side of this HVES instance is connected to the positive side of t...";
CM_ SG_ 2364643326 Hvsp1HghVltgBsNgtvCnttrStt "HVESP1 High-Voltage Bus (Negative) Contactor State: Position of this High Voltage Energy Storage Pack instance negative side bus contactor.  When this contactor is closed, the negative side of this HVES instance is connected to the negative side of t...";
CM_ SG_ 2364643326 Hvsp1HghVltgBsDsnntFrwrnng "HVESP1 High-Voltage Bus Disconnect Forewarning: Indicates that this High Voltage Energy Storage Pack instance is about to disconnect from the high voltage bus due to unacceptable conditions.This parameter is for one of multiple packs in an HVESS. If ...";
CM_ SG_ 2364643326 Hvsp1HghVltgBsPrChrgRlStt "HVESP1 High-Voltage Bus Pre-Charge Relay State: Position of the high-voltage bus contactor pre-charge relay.  When this relay is closed, this High Voltage Energy Storage Pack instance is bringing the high-voltage bus up to its operating level.This pa...";
CM_ SG_ 2364643326 Hvsp1CntrOfPkCnttrStt "HVESP1 Center of Pack Contactor State: Position of the center high-voltage contactor.  When this contactor is closed, the positive half of this High Voltage Energy Storage Pack instance is connected to the negative half.  If a system controls the pos...";
CM_ SG_ 2364643326 Hvsp1HghVltgBsAtvIsltnTstStts "HVESP1 High-Voltage Bus Active Isolation Test Status: Status of the high-voltage bus electrical active isolation test as performed by this High Voltage Energy Storage Pack instance.This parameter is for one of multiple packs in an HVESS. If there is ...";
CM_ SG_ 2364643326 Hvsp1HghVltgBsPssvIsltnTstStts "HVESP1 High-Voltage Bus Passive Isolation Test Status: Status of the high-voltage bus electrical passive isolation test as performed by this High Voltage Energy Storage Pack instance.This parameter is for one of multiple packs in an HVESS. If there i...";
CM_ SG_ 2364643326 Hvsp1HghVltgBsCnntnStts "HVESP1 High-Voltage Bus Connection Status: This parameter provides high level feedback on this High Voltage Energy Storage Pack instance high voltage bus connection.  For specific contactor information, see SPN 11075 (HVESP1 High-Voltage Bus (Positiv...";
CM_ BO_ 2364643582 "High Voltage Energy Storage Pack 1 Data 7";
CM_ SG_ 2364643582 Hvesp1DischargeEnergyCapacity "HVESP1 Discharge Energy Capacity: The amount of stored electrical energy in this High Voltage Energy Storage Pack instance that is available for use by the hybrid or EV system, i.e. 'how full is the tank'.  See SPN 11062 (HVESP1 Discharge Capacity) f...";
CM_ SG_ 2364643582 Hvesp1ChargeEnergyCapacity "HVESP1 Charge Energy Capacity: The amount of unused electrical energy storage available to be filled by charging this High Voltage Energy Storage Pack instance, i.e. 'how much empty space is remaining in the tank'.  See SPN 11063 (HVESP1 Charge Capac...";
CM_ SG_ 2364643582 Hvesp1MaximumChargeVoltageLimit "HVESP1 Maximum Charge Voltage Limit: The maximum voltage level not to be exceeded while charging this High Voltage Energy Storage Pack instance.  If this parameter is not supported, the maximum charge voltage should be limited to SPN 11134 (HVESP1 Re...";
CM_ BO_ 2364643838 "High Voltage Energy Storage Pack 1 Module Status 1";
CM_ SG_ 2364643838 Hvesp1Module1OperationalStatus "HVESP1 Module 1 Operational Status: Operational Status of Module 1 in this High Voltage Energy Storage Pack Instance.  Not Operational is used when the module is initializing or not able to function (e.g. internal module level monitors have failed). ...";
CM_ SG_ 2364643838 Hvesp1Module2OperationalStatus "HVESP1 Module 2 Operational Status: Operational Status of Module 2 in this High Voltage Energy Storage Pack Instance.  Not Operational is used when the module is initializing or not able to function (e.g. internal module level monitors have failed). ...";
CM_ SG_ 2364643838 Hvesp1Module3OperationalStatus "HVESP1 Module 3 Operational Status: Operational Status of Module 3 in this High Voltage Energy Storage Pack Instance.  Not Operational is used when the module is initializing or not able to function (e.g. internal module level monitors have failed). ...";
CM_ SG_ 2364643838 Hvesp1Module4OperationalStatus "HVESP1 Module 4 Operational Status: Operational Status of Module 4 in this High Voltage Energy Storage Pack Instance.  Not Operational is used when the module is initializing or not able to function (e.g. internal module level monitors have failed). ...";
CM_ SG_ 2364643838 Hvesp1Module5OperationalStatus "HVESP1 Module 5 Operational Status: Operational Status of Module 5 in this High Voltage Energy Storage Pack Instance.  Not Operational is used when the module is initializing or not able to function (e.g. internal module level monitors have failed). ...";
CM_ SG_ 2364643838 Hvesp1Module6OperationalStatus "HVESP1 Module 6 Operational Status: Operational Status of Module 6 in this High Voltage Energy Storage Pack Instance.  Not Operational is used when the module is initializing or not able to function (e.g. internal module level monitors have failed). ...";
CM_ SG_ 2364643838 Hvesp1Module7OperationalStatus "HVESP1 Module 7 Operational Status: Operational Status of Module 7 in this High Voltage Energy Storage Pack Instance.  Not Operational is used when the module is initializing or not able to function (e.g. internal module level monitors have failed). ...";
CM_ SG_ 2364643838 Hvesp1Module8OperationalStatus "HVESP1 Module 8 Operational Status: Operational Status of Module 8 in this High Voltage Energy Storage Pack Instance.  Not Operational is used when the module is initializing or not able to function (e.g. internal module level monitors have failed). ...";
CM_ SG_ 2364643838 Hvesp1Module9OperationalStatus "HVESP1 Module 9 Operational Status: Operational Status of Module 9 in this High Voltage Energy Storage Pack Instance.  Not Operational is used when the module is initializing or not able to function (e.g. internal module level monitors have failed). ...";
CM_ SG_ 2364643838 Hvesp1Module10OperationalStatus "HVESP1 Module 10 Operational Status: Operational Status of Module 10 in this High Voltage Energy Storage Pack Instance.  Not Operational is used when the module is initializing or not able to function (e.g. internal module level monitors have failed)...";
CM_ SG_ 2364643838 Hvesp1Module11OperationalStatus "HVESP1 Module 11 Operational Status: Operational Status of Module 11 in this High Voltage Energy Storage Pack Instance.  Not Operational is used when the module is initializing or not able to function (e.g. internal module level monitors have failed)...";
CM_ SG_ 2364643838 Hvesp1Module12OperationalStatus "HVESP1 Module 12 Operational Status: Operational Status of Module 12 in this High Voltage Energy Storage Pack Instance.  Not Operational is used when the module is initializing or not able to function (e.g. internal module level monitors have failed)...";
CM_ SG_ 2364643838 Hvesp1Module13OperationalStatus "HVESP1 Module 13 Operational Status: Operational Status of Module 13 in this High Voltage Energy Storage Pack Instance.  Not Operational is used when the module is initializing or not able to function (e.g. internal module level monitors have failed)...";
CM_ SG_ 2364643838 Hvesp1Module14OperationalStatus "HVESP1 Module 14 Operational Status: Operational Status of Module 14 in this High Voltage Energy Storage Pack Instance.  Not Operational is used when the module is initializing or not able to function (e.g. internal module level monitors have failed)...";
CM_ SG_ 2364643838 Hvesp1Module15OperationalStatus "HVESP1 Module 15 Operational Status: Operational Status of Module 15 in this High Voltage Energy Storage Pack Instance.  Not Operational is used when the module is initializing or not able to function (e.g. internal module level monitors have failed)...";
CM_ SG_ 2364643838 Hvesp1Module16OperationalStatus "HVESP1 Module 16 Operational Status: Operational Status of Module 16 in this High Voltage Energy Storage Pack Instance.  Not Operational is used when the module is initializing or not able to function (e.g. internal module level monitors have failed)...";
CM_ SG_ 2364643838 Hvesp1Module17OperationalStatus "HVESP1 Module 17 Operational Status: Operational Status of Module 17 in this High Voltage Energy Storage System (or Pack 1 in systems with only one pack).  Not Operational is used when the module is initializing or not able to function (e.g. internal...";
CM_ SG_ 2364643838 Hvesp1Module18OperationalStatus "HVESP1 Module 18 Operational Status: Operational Status of Module 18 in this High Voltage Energy Storage System (or Pack 1 in systems with only one pack).  Not Operational is used when the module is initializing or not able to function (e.g. internal...";
CM_ SG_ 2364643838 Hvesp1Module19OperationalStatus "HVESP1 Module 19 Operational Status: Operational Status of Module 19 in this High Voltage Energy Storage System (or Pack 1 in systems with only one pack).  Not Operational is used when the module is initializing or not able to function (e.g. internal...";
CM_ SG_ 2364643838 Hvesp1Module20OperationalStatus "HVESP1 Module 20 Operational Status: Operational Status of Module 20 in this High Voltage Energy Storage System (or Pack 1 in systems with only one pack).  Not Operational is used when the module is initializing or not able to function (e.g. internal...";
CM_ SG_ 2364643838 Hvesp1Module21OperationalStatus "HVESP1 Module 21 Operational Status: Operational Status of Module 21 in this High Voltage Energy Storage System (or Pack 1 in systems with only one pack).  Not Operational is used when the module is initializing or not able to function (e.g. internal...";
CM_ SG_ 2364643838 Hvesp1Module22OperationalStatus "HVESP1 Module 22 Operational Status: Operational Status of Module 22 in this High Voltage Energy Storage System (or Pack 1 in systems with only one pack).  Not Operational is used when the module is initializing or not able to function (e.g. internal...";
CM_ SG_ 2364643838 Hvesp1Module23OperationalStatus "HVESP1 Module 23 Operational Status: Operational Status of Module 23 in this High Voltage Energy Storage System (or Pack 1 in systems with only one pack).  Not Operational is used when the module is initializing or not able to function (e.g. internal...";
CM_ SG_ 2364643838 Hvesp1Module24OperationalStatus "HVESP1 Module 24 Operational Status: Operational Status of Module 24 in this High Voltage Energy Storage System (or Pack 1 in systems with only one pack).  Not Operational is used when the module is initializing or not able to function (e.g. internal...";
CM_ SG_ 2364643838 Hvesp1Module25OperationalStatus "HVESP1 Module 25 Operational Status: Operational Status of Module 25 in this High Voltage Energy Storage System (or Pack 1 in systems with only one pack).  Not Operational is used when the module is initializing or not able to function (e.g. internal...";
CM_ SG_ 2364643838 Hvesp1Module26OperationalStatus "HVESP1 Module 26 Operational Status: Operational Status of Module 26 in this High Voltage Energy Storage System (or Pack 1 in systems with only one pack).  Not Operational is used when the module is initializing or not able to function (e.g. internal...";
CM_ SG_ 2364643838 Hvesp1Module27OperationalStatus "HVESP1 Module 27 Operational Status: Operational Status of Module 27 in this High Voltage Energy Storage System (or Pack 1 in systems with only one pack).  Not Operational is used when the module is initializing or not able to function (e.g. internal...";
CM_ SG_ 2364643838 Hvesp1Module28OperationalStatus "HVESP1 Module 28 Operational Status: Operational Status of Module 28 in this High Voltage Energy Storage System (or Pack 1 in systems with only one pack).  Not Operational is used when the module is initializing or not able to function (e.g. internal...";
CM_ SG_ 2364643838 Hvesp1Module29OperationalStatus "HVESP1 Module 29 Operational Status: Operational Status of Module 29 in this High Voltage Energy Storage System (or Pack 1 in systems with only one pack).  Not Operational is used when the module is initializing or not able to function (e.g. internal...";
CM_ SG_ 2364643838 Hvesp1Module30OperationalStatus "HVESP1 Module 30 Operational Status: Operational Status of Module 30 in this High Voltage Energy Storage System (or Pack 1 in systems with only one pack).  Not Operational is used when the module is initializing or not able to function (e.g. internal...";
CM_ SG_ 2364643838 Hvesp1Module31OperationalStatus "HVESP1 Module 31 Operational Status: Operational Status of Module 31 in this High Voltage Energy Storage System (or Pack 1 in systems with only one pack).  Not Operational is used when the module is initializing or not able to function (e.g. internal...";
CM_ SG_ 2364643838 Hvesp1Module32OperationalStatus "HVESP1 Module 32 Operational Status: Operational Status of Module 32 in this High Voltage Energy Storage System (or Pack 1 in systems with only one pack).  Not Operational is used when the module is initializing or not able to function (e.g. internal...";
CM_ BO_ 2364644094 "High Voltage Energy Storage Pack 1 Thermal Management System Status 1";
CM_ SG_ 2364644094 Hvsp1ThrmlMngmntSstmSlInptPwr "HVESP1 Thermal Management System SLI Input Power: This is the low-voltage power consumed by this HVES Thermal Management System (TMS).This parameter is for one of multiple packs in an HVESS.  If there is only one pack in the system, the HVESS paramet...";
CM_ SG_ 2364644094 Hvsp1TMtSstHVtIptPw "HVESP1 Thermal Management System High-Voltage Input Power: This is the high-voltage power consumed by this HVES Thermal Management System (TMS).This parameter is for one of multiple packs in an HVESS.  If there is only one pack in the system, the HVE...";
CM_ SG_ 2364644094 Hvsp1ThrmlMngmntSstmCmprssrSpd "HVESP1 Thermal Management System Compressor Speed: When this High Voltage Energy Storage Pack Thermal Management System is equipped with an active cooling system (e.g. air conditioner), this is the Compressor Speed.This parameter is for one of multip...";
CM_ SG_ 2364644094 Hvsp1ThrmlMngmntSstmRltvHmdt "HVESP1 Thermal Management System Relative Humidty: When this High Voltage Energy Storage Pack Thermal Management System is equipped with a relative humidity sensor, this is the  measured Relative Humidity.This parameter is for one of multiple packs i...";
CM_ SG_ 2364644094 Hvsp1ThrmlMngmntSstmHtrStts "HVESP1 Thermal Management System Heater Status: The state of this High Voltage Energy Storage Pack heaterThis parameter is for one of multiple packs in an HVESS.  If there is only one pack in the system, the HVESS parameters should be used. If there ...";
CM_ SG_ 2364644094 Hvsp1ThrmlMngmntSstmHvlStts "HVESP1 Thermal Management System HVIL Status: In multiple HVES configurations, this is the status of the High Voltage Interlock Loop from the viewpoint of this Thermal Management System.00b = HVIL Closed01b = HVIL Open10b = Error11b = Not AvailableTh...";
CM_ SG_ 2364644094 Hvsp1ThrmlMngmntSstmMd "HVESP1 Thermal Management System Mode: Indicates the operating mode of the Thermal Management System.  The heat transfer medium may be (e.g. liquid or air).  The cooling system may be fans, liquid coolant, or a combination of mediums.  The system may...";
CM_ SG_ 2364644094 Hvsp1ThrmlMngmntSstmClntLvl "HVESP1 Thermal Management System Coolant Level: Indicates the coolant level in this HVES Thermal Management System (TMS).This parameter is for one of multiple packs in an HVESS.  If there is only one pack in the system, the HVESS parameters should be...";
CM_ BO_ 2364644350 "High Voltage Energy Storage Pack 1 Data 8";
CM_ SG_ 2364644350 Hvesp1AverageCellVoltage "HVESP1 Average Cell Voltage: The average cell voltage in this High Voltage Energy Storage Pack instance.This parameter is for one of multiple packs in an HVESS.  If there is only one pack in the system, the HVESS parameters should be used. If there a...";
CM_ SG_ 2364644350 Hvsp1HghstCllVltgMdlNmr "HVESP1 Highest Cell Voltage Module Number: Identifies the location of the module containing SPN 11055 (HVESP1 Highest Cell Voltage).This parameter is for one of multiple packs in an HVESS.  If there is only one pack in the system, the HVESS parameter...";
CM_ SG_ 2364644350 Hvsp1HghstCllVltgCllNmr "HVESP1 Highest Cell Voltage Cell Number: Identifies the location of SPN 11055 (HVESP1 Highest Cell Voltage) within SPN 11115 (HVESP1 Highest Cell Voltage Module Number).This parameter is for one of multiple packs in an HVESS.  If there is only one pa...";
CM_ SG_ 2364644350 Hvsp1LwstCllVltgMdlNmr "HVESP1 Lowest Cell Voltage Module Number: Identifies the location of the module containing SPN 11056 (HVESP1 Lowest Cell Voltage).This parameter is for one of multiple packs in an HVESS.  If there is only one pack in the system, the HVESS parameters ...";
CM_ SG_ 2364644350 Hvsp1LwstCllVltgCllNmr "HVESP1 Lowest Cell Voltage Cell Number: Identifies the location of SPN 11056 (HVESP1 Lowest Cell Voltage) within SPN 11117 (HVESP1 Lowest Cell Voltage Module Number).This parameter is for one of multiple packs in an HVESS.  If there is only one pack ...";
CM_ BO_ 2364644606 "High Voltage Energy Storage Pack 1 Data 9";
CM_ SG_ 2364644606 Hvsp1HghstCllTmprtrMdlNmr "HVESP1 Highest Cell Temperature Module Number: Identifies the location of the module containing SPN 11058 (HVESP1 Highest Cell Temperature).This parameter is for one of multiple packs in an HVESS.  If there is only one pack in the system, the HVESS p...";
CM_ SG_ 2364644606 Hvsp1HghstCllTmprtrCllNmr "HVESP1 Highest Cell Temperature Cell Number: Identifies the location of SPN 11058 (HVESP1 Highest Cell Temperature) within SPN 11120 (HVESP1 Highest Cell Temperature Module Number).This parameter is for one of multiple packs in an HVESS.  If there is...";
CM_ SG_ 2364644606 Hvsp1LwstCllTmprtrMdlNmr "HVESP1 Lowest Cell Temperature Module Number: Identifies the location of the module containing SPN 11059 (HVESP1 Lowest Cell Temperature).This parameter is for one of multiple packs in an HVESS.  If there is only one pack in the system, the HVESS par...";
CM_ SG_ 2364644606 Hvsp1LwstCllTmprtrCllNmr "HVESP1 Lowest Cell Temperature Cell Number: Identifies the location of SPN 11059 (HVESP1 Lowest Cell Temperature) within SPN 11122 (HVESP1 Lowest Cell Temperature Module Number).This parameter is for one of multiple packs in an HVESS.  If there is on...";
CM_ SG_ 2364644606 Hvess1ThermalEventDetected "HVESS1 Thermal Event Detected: A sensor has detected the presence of a thermal event at or near High Voltage Energy Storage Pack instance.00b = No Thermal Event Detected01b = Thermal Event Detected10b = Error11b = Not availableThis parameter is for o...";
CM_ SG_ 2364644606 Hvsp1Dt9EmdddIntgrtSpprt "HVESP1 Data 9 Embedded Integrity Support: Indicates SPN 22976 (HVESP1 Data 9 CRC) and SPN 22975 (HVESP1 Data 9 Counter) are supported by the sender.00b = Embedded CRC and Counter are supported by the sender01b = Protection is provided using an extern...";
CM_ SG_ 2364644606 Hvesp1Data9Counter "HVESP1 Data 9 Counter: The message counter is used to detect situations where the transmitting ECU malfunction repeats the same frame all the time. The receiver of the information may use the counter parameter to detect this situation. The transmitti...";
CM_ SG_ 2364644606 Hvesp1Data9Crc "HVESP1 Data 9 CRC: The CRC is defined as follows: - Length: 8 bits- Polynomial: x^8+x^5+x^3+x^2+x+1- Initial Value: FFh- Input Data Reflection: Not reflected- Result Data Reflection: Not reflected- XOR value: FFh SAE makes no claim of the functional ...";
CM_ BO_ 2364644862 "High Voltage Energy Storage Pack 1 Data 10";
CM_ SG_ 2364644862 Hvsp1HghstCllSttOfChrgMdlNmr "HVESP1 Highest Cell State of Charge Module Number: Identifies the location of the module containing SPN 11068 (HVESP1 Highest Cell State of Charge).This parameter is for one of multiple packs in an HVESS.  If there is only one pack in the system, the...";
CM_ SG_ 2364644862 Hvsp1HghstCllSttOfChrgCllNmr "HVESP1 Highest Cell State of Charge Cell Number: Identifies the location of SPN 11068 (HVESP1 Highest Cell State of Charge) within SPN 11124 (HVESP1 Highest Cell State of Charge Module Number).This parameter is for one of multiple packs in an HVESS. ...";
CM_ SG_ 2364644862 Hvsp1LwstCllSttOfChrgMdlNmr "HVESP1 Lowest Cell State of Charge Module Number: Identifies the location of the module containing SPN 11067 (HVESP1 Lowest Cell State of Charge).This parameter is for one of multiple packs in an HVESS.  If there is only one pack in the system, the H...";
CM_ SG_ 2364644862 Hvsp1LwstCllSttOfChrgCllNmr "HVESP1 Lowest Cell State of Charge Cell Number: Identifies the location of SPN 11067 (HVESP1 Lowest Cell State of Charge) within SPN 11126 (HVESP1 Lowest Cell State of Charge Module Number).This parameter is for one of multiple packs in an HVESS.  If...";
CM_ SG_ 2364644862 Hvsp1HghVltgBsAtvIsltnTstRslts "HVESP1 High-Voltage Bus Active Isolation Test Results: The isolation resistance expressed in Ohms per Volt that resulted from the High-Voltage Bus Active Isolation Test.See SPN 11080 (HVESP1 High-Voltage Bus Active Isolation Test Status) for test sta...";
CM_ SG_ 2364644862 Hvsp1HghVltgBsPssvIsltnTstRslts "HVESP1 High-Voltage Bus Passive Isolation Test Results: The isolation resistance expressed in Ohms per Volt that resulted from the High-Voltage Bus Passive Isolation Test.See SPN 11081 (HVESP1 High-Voltage Bus Passive Isolation Test Status) for test ...";
CM_ BO_ 2364645118 "High Voltage Energy Storage Pack 1 Data 11";
CM_ SG_ 2364645118 Hvesp1ActualChargeRate "HVESP1 Actual Charge Rate: This signal represents the actual present charge rate of this High Voltage Energy Storage Pack instance.This parameter is for one of multiple packs in an HVESS. If there is only one pack in the system, the HVESS parameters ...";
CM_ SG_ 2364645118 Hvsp1BsVltgNgtvTChsssGrndVltg "HVESP1 Bus Voltage Negative to Chassis Ground Voltage: Voltage difference between the most negative terminal of the HVES battery and chassis measured on the hybrid or EV system bus side (not the battery side) of any HVES contained output contactor.  ...";
CM_ SG_ 2364645118 Hvsp1VltgLvlNgtvTChsssGrndVltg "HVESP1 Voltage Level Negative to Chassis Ground Voltage: Voltage difference between the most negative terminal of the HVES battery and chassis measured at the battery side of any HVES contained output contactor.  This voltage may be used for system l...";
CM_ BO_ 2364645374 "High Voltage Energy Storage Pack 2 Status 2";
CM_ SG_ 2364645374 Hvsp2DshrgPwrLmtDTSttOfChrg "HVESP2 Discharge Power Limit Due to State of Charge: Indicates whether or not discharge power of this HVES instance is being limited due to state of charge.This parameter is for one of multiple packs in an HVESS.  If there is only one pack in the sys...";
CM_ SG_ 2364645374 Hvsp2DshrgPwrLmtDTBttrTmprtr "HVESP2 Discharge Power Limit Due to Battery Temperature: Indicates whether or not discharge power of this HVES instance is being limited due to battery temperature.This parameter is for one of multiple packs in an HVESS.  If there is only one pack in...";
CM_ SG_ 2364645374 Hvsp2DsPwLtDTBttDstCdt "HVESP2 Discharge Power Limit Due to Battery Diagnostic Condition: Indicates whether or not discharge power of this HVES instance is being limited due to a battery diagnostic condition.This parameter is for one of multiple packs in an HVESS.  If there...";
CM_ SG_ 2364645374 Hvsp2DshrgPwrLmtDTBttrOrCllVltg "HVESP2 Discharge Power Limit Due to Battery or Cell Voltage: Indicates whether or not discharge power of this HVES instance is being limited due to a battery or cell voltage level.This parameter is for one of multiple packs in an HVESS.  If there is ...";
CM_ SG_ 2364645374 Hvsp2DshrgPwrLmtDTBttrCrrnt "HVESP2 Discharge Power Limit Due to Battery Current: Indicates whether or not discharge power of this HVES instance is being limited due to battery current.This parameter is for one of multiple packs in an HVESS.  If there is only one pack in the sys...";
CM_ SG_ 2364645374 Hvsp2DshrgPwrLmtDTAnUndfndCs "HVESP2 Discharge Power Limit Due to an Undefined Cause: Indicates whether or not discharge power of this HVES instance is being limited due to an undefined cause.This parameter is for one of multiple packs in an HVESS.  If there is only one pack in t...";
CM_ SG_ 2364645374 Hvsp2ChrgPwrLmtDTSttOfChrg "HVESP2 Charge Power Limit Due to State of Charge: Indicates whether or not charge power of this HVES instance is being limited due to state of charge.This parameter is for one of multiple packs in an HVESS.  If there is only one pack in the system, t...";
CM_ SG_ 2364645374 Hvsp2ChrgPwrLmtDTBttrTmprtr "HVESP2 Charge Power Limit Due to Battery Temperature: Indicates whether or not charge power of this HVES instance is being limited due to battery temperature.This parameter is for one of multiple packs in an HVESS.  If there is only one pack in the s...";
CM_ SG_ 2364645374 Hvsp2ChrgPwrLmtDTBttrDgnstCndtn "HVESP2 Charge Power Limit Due to Battery Diagnostic Condition: Indicates whether or not charge power of this HVES instance is being limited due to a battery diagnostic condition.This parameter is for one of multiple packs in an HVESS.  If there is on...";
CM_ SG_ 2364645374 Hvsp2ChrgPwrLmtDTBttrOrCllVltg "HVESP2 Charge Power Limit Due to Battery or Cell Voltage: Indicates whether or not charge power of this HVES instance is being limited due to a battery or cell voltage level.This parameter is for one of multiple packs in an HVESS.  If there is only o...";
CM_ SG_ 2364645374 Hvsp2ChrgPwrLmtDTBttrCrrnt "HVESP2 Charge Power Limit Due to Battery Current: Indicates whether or not charge power of this HVES instance is being limited due to battery current.This parameter is for one of multiple packs in an HVESS.  If there is only one pack in the system, t...";
CM_ SG_ 2364645374 Hvsp2ChrgPwrLmtDTAnUndfndCs "HVESP2 Charge Power Limit Due to an Undefined Cause: Indicates whether or not charge power of this HVES instance is being limited due to an undefined cause.This parameter is for one of multiple packs in an HVESS.  If there is only one pack in the sys...";
CM_ BO_ 2364645630 "High Voltage Energy Storage Pack 2 Data 1";
CM_ SG_ 2364645630 Hvesp2AvailableDischargePower "HVESP2 Available Discharge Power: The rate at which this High Voltage Energy Storage Pack instance can currently provide energy for propulsion or other uses.This parameter is for one of multiple packs in an HVESS.  If there is only one pack in the sy...";
CM_ SG_ 2364645630 Hvesp2AvailableChargePower "HVESP2 Available Charge Power: The rate at which this High Voltage Energy Storage Pack instance can currently receive energy from a regenerative or recharging system.This parameter is for one of multiple packs in an HVESS.  If there is only one pack ...";
CM_ SG_ 2364645630 Hvesp2VoltageLevel "HVESP2 Voltage Level: The voltage level of this High Voltage Energy Storage Pack instance. This parameter should be synchronized with SPN 11169 (HVESP2 Current) such that a realized power value can be calculated.  If the HVES component physically con...";
CM_ SG_ 2364645630 Hvesp2Current "HVESP2 Current: The current in or out of this High Voltage Energy Storage Pack instance. This parameter should be synchronized with SPN 11168 (HVESP2 Voltage Level) such that a realized power value can be calculated.  This parameter is defined from t...";
CM_ BO_ 2364645886 "High Voltage Energy Storage Pack 2 Data 2";
CM_ SG_ 2364645886 Hvesp2FastUpdateStateOfCharge "HVESP2 Fast Update State of Charge: Indicates this High Voltage Energy Storage Pack instance state of charge.  0% means no charge remaining, 100% means the system is fully charged in terms of physical limits of this energy storage pack instance.  Acc...";
CM_ SG_ 2364645886 Hvesp2HighestCellVoltage "HVESP2 Highest Cell Voltage: The highest voltage level reported by any cell in this High Voltage Energy Storage Pack instance. If a single voltage sensor covers more than one cell, the value in this parameter is for the smallest group of cells measur...";
CM_ SG_ 2364645886 Hvesp2LowestCellVoltage "HVESP2 Lowest Cell Voltage: The lowest voltage level reported by any cell in this High Voltage Energy Storage Pack instance. If a single voltage sensor covers more than one cell, the value in this parameter is for the smallest group of cells measured...";
CM_ SG_ 2364645886 Hvsp2CllVltgDffrntlStts "HVESP2 Cell Voltage Differential Status: Indicates whether or not the differential between the highest and lowest cell voltages are within acceptable limits, according to this High Voltage Energy Storage Pack instance. The actual voltage differential...";
CM_ BO_ 2364646142 "High Voltage Energy Storage Pack 2 Data 3";
CM_ SG_ 2364646142 Hvesp2HighestCellTemperature "HVESP2 Highest Cell Temperature: The highest temperature level reported by any cell in this High Voltage Energy Storage Pack instance.  If a single temperature sensor covers more than one cell, the value in this parameter is for the smallest group of...";
CM_ SG_ 2364646142 Hvesp2LowestCellTemperature "HVESP2 Lowest Cell Temperature: The lowest temperature level reported by any cell in this High Voltage Energy Storage Pack instance.  If a single temperature sensor covers more than one cell, the value in this parameter is for the smallest group of c...";
CM_ SG_ 2364646142 Hvesp2AverageCellTemperature "HVESP2 Average Cell Temperature: The average temperature level of all cells in this High Voltage Energy Storage Pack instance.This parameter is for one of multiple packs in an HVESS.  If there is only one pack in the system, the HVESS parameters shou...";
CM_ SG_ 2364646142 Hvsp2CllTmprtrDffrntlStts "HVESP2 Cell Temperature Differential Status: Indicates whether or not the differential between the highest and lowest cell temperatures are within acceptable limits per this High Voltage Energy Storage Pack instance.  The actual temperature different...";
CM_ BO_ 2364646398 "High Voltage Energy Storage Pack 2 Data 4";
CM_ SG_ 2364646398 Hvesp2DischargeCapacity "HVESP2 Discharge Capacity: The amount of stored electrical charge in this High Voltage Energy Storage Pack instance that is available for use by the hybrid or EV system, i.e. 'how full is the tank'.  See SPN 11206 (HVESP2 Discharge Energy Capacity) f...";
CM_ SG_ 2364646398 Hvesp2ChargeCapacity "HVESP2 Charge Capacity: The amount of unused electrical charge storage in this High Voltage Energy Storage Pack instance that is available to be filled by charging, i.e. 'how much empty space is remaining in the tank'.  See SPN 11207 (HVESP2 Charge E...";
CM_ SG_ 2364646398 Hvesp2CellBalancingCount "HVESP2 Cell Balancing Count: The number of cells that are currently being balanced in this High Voltage Energy Storage Pack instance.This parameter is for one of multiple packs in an HVESS.  If there is only one pack in the system, the HVESS paramete...";
CM_ BO_ 2364646654 "High Voltage Energy Storage Pack 2 Data 5";
CM_ SG_ 2364646654 Hvesp2LowestCellStateOfCharge "HVESP2 Lowest Cell State of Charge: Indicates the state of charge of the lowest-charged cell in this High Voltage Energy Storage Pack instance.  0% means no charge remaining, 100% means the cell is fully charged.   If a single state of charge value c...";
CM_ SG_ 2364646654 Hvesp2HighestCellStateOfCharge "HVESP2 Highest Cell State of Charge: Indicates the state of charge of the highest-charged cell in this High Voltage Energy Storage Pack instance.  0% means no charge remaining, 100% means the cell is fully charged.  If a single state of charge value ...";
CM_ SG_ 2364646654 Hvsp2MxmmInstntnsDshrgCrrntLmt "HVESP2 Maximum Instantaneous Discharge Current Limit: The maximum instantaneous current flow limit out of this High Voltage Energy Storage Pack instance. This parameter is defined from the high voltage energy storage pack's point of view and should r...";
CM_ SG_ 2364646654 Hvsp2MxmmInstntnsChrgCrrntLmt "HVESP2 Maximum Instantaneous Charge Current Limit: The maximum instantaneous current flow limit into this High Voltage Energy Storage Pack instance. This parameter is defined from the high voltage energy storage pack's point of view and should reflec...";
CM_ BO_ 2364646910 "High Voltage Energy Storage Pack 2 Data 6";
CM_ SG_ 2364646910 Hvesp2BusVoltage "HVESP2 Bus Voltage: The voltage level of the high voltage bus, as measured by this High Voltage Energy Storage Pack instance on the bus side (not the battery side) of its contactors.This parameter is for one of multiple packs in an HVESS.  If there i...";
CM_ SG_ 2364646910 Hvesp2IgnitionVoltage "HVESP2 Ignition Voltage: The voltage level at the ignition input of this High Voltage Energy Storage Pack controller.This parameter is for one of multiple packs in an HVESS.  If there is only one pack in the system, the HVESS parameters should be use...";
CM_ SG_ 2364646910 Hvesp2IntakeCoolantTemperature "HVESP2 Intake Coolant Temperature: The temperature of liquid coolant as it enters this High Voltage Energy Storage Pack instance.This parameter is for one of multiple packs in an HVESS.  If there is only one pack in the system, the HVESS parameters s...";
CM_ SG_ 2364646910 Hvesp2OutletCoolantTemperature "HVESP2 Outlet Coolant Temperature: The temperature of liquid coolant as it exits this High Voltage Energy Storage Pack instance.This parameter is for one of multiple packs in an HVESS.  If there is only one pack in the system, the HVESS parameters sh...";
CM_ SG_ 2364646910 Hvesp2ElectronicsTemperature "HVESP2 Electronics Temperature: The temperature of the electronics or control modules in this High Voltage Energy Storage Pack instance.  If there are multiple temperature sensors then this parameter would be set to the maximum sensor reading.This pa...";
CM_ SG_ 2364646910 Hvesp2Temperature "HVESP2 Temperature: The temperature of this High Voltage Energy Storage Pack instance. The value may be determined from a unique sensor specifically for this purpose, or by aggregating various temperature sensor readings within the pack.This paramete...";
CM_ BO_ 2364647166 "High Voltage Energy Storage Pack 2 Status 1";
CM_ SG_ 2364647166 Hvesp2HvilStatus "HVESP2 HVIL Status: Status of the High Voltage Interlock Loop from the viewpoint of this High Voltage Energy Storage Pack instance.This parameter is for one of multiple packs in an HVESS. If there is only one pack in the system, the HVESS parameters ...";
CM_ SG_ 2364647166 Hvesp2InertiaSwitchStatus "HVESP2 Inertia Switch Status: Switch indicating that an impact has been sensed by this High Voltage Energy Storage Pack instance. The impact indication may require action by another controller, or by this HVES instance itself.  For example, a control...";
CM_ SG_ 2364647166 Hvesp2StateOfChargeStatus "HVESP2 State of Charge Status: Status of this High Voltage Energy Storage Pack instance State of Charge (SOC).  Note:  A given HVES controller may not support all of the states.This parameter is for one of multiple packs in an HVESS.  If there is onl...";
CM_ SG_ 2364647166 Hvesp2CellBalanceStatus "HVESP2 Cell Balance Status: Indicates whether or not the cells in this High Voltage Energy Storage Pack instance are balanced.This parameter is for one of multiple packs in an HVESS.  If there is only one pack in the system, the HVESS parameters shou...";
CM_ SG_ 2364647166 Hvesp2CellBalancingActive "HVESP2 Cell Balancing Active: Indicates whether or not the cells in this High Voltage Energy Storage Pack instance are currently being balanced.This parameter is for one of multiple packs in an HVESS.  If there is only one pack in the system, the HVE...";
CM_ SG_ 2364647166 Hvesp2InternalChargerStatus "HVESP2 Internal Charger Status: Indicates that the charger in this HVES instance is on.  External chargers may use the External Energy Source Connection Status (SPN 7898) and related SPs.This parameter is for one of multiple packs in an HVESS. If the...";
CM_ SG_ 2364647166 Hvesp2OperationalStatus "HVESP2 Operational Status: Provides feedback on where this High Voltage Energy Storage Pack instance is in its operating spectrum, and includes feedback in response to the Operation Consent [i.e. SPN 11151 (HVESP2 Operation Consent)] and Power Down C...";
CM_ SG_ 2364647166 Hvesp2Status1Counter "HVESP2 Status 1 Counter: The message counter is used to detect situations where the transmitting ECU malfunction repeats the same frame all the time. The receiver of the information may use the counter parameter to detect this situation. The transmit...";
CM_ SG_ 2364647166 Hvesp2Status1Crc "HVESP2 Status 1 CRC: The CRC is defined as follows: - Length: 8 bits- Polynomial: x^8+x^5+x^3+x^2+x+1- Initial Value: FFh- Input Data Reflection: Not reflected- Result Data Reflection: Not reflected- XOR value: FFh SAE makes no claim of the functiona...";
CM_ SG_ 2364647166 Hvsp2HghVltgBsPstvCnttrStt "HVESP2 High-Voltage Bus (Positive) Contactor State: Position of this High Voltage Energy Storage Pack instance positive side bus contactor.  When this contactor is closed, the positive side of this HVES instance is connected to the positive side of t...";
CM_ SG_ 2364647166 Hvsp2HghVltgBsNgtvCnttrStt "HVESP2 High-Voltage Bus (Negative) Contactor State: Position of this High Voltage Energy Storage Pack instance negative side bus contactor.  When this contactor is closed, the negative side of this HVES instance is connected to the negative side of t...";
CM_ SG_ 2364647166 Hvsp2HghVltgBsDsnntFrwrnng "HVESP2 High-Voltage Bus Disconnect Forewarning: Indicates that this High Voltage Energy Storage Pack instance is about to disconnect from the high voltage bus due to unacceptable conditions.This parameter is for one of multiple packs in an HVESS. If ...";
CM_ SG_ 2364647166 Hvsp2HghVltgBsPrChrgRlStt "HVESP2 High-Voltage Bus Pre-Charge Relay State: Position of the high-voltage bus contactor pre-charge relay.  When this relay is closed, this High Voltage Energy Storage Pack instance is bringing the high-voltage bus up to its operating level.This pa...";
CM_ SG_ 2364647166 Hvsp2CntrOfPkCnttrStt "HVESP2 Center of Pack Contactor State: Position of the center high-voltage contactor.  When this contactor is closed, the positive half of this High Voltage Energy Storage Pack instance is connected to the negative half.  If a system controls the pos...";
CM_ SG_ 2364647166 Hvsp2HghVltgBsAtvIsltnTstStts "HVESP2 High-Voltage Bus Active Isolation Test Status: Status of the high-voltage bus electrical active isolation test as performed by this High Voltage Energy Storage Pack instance.This parameter is for one of multiple packs in an HVESS. If there is ...";
CM_ SG_ 2364647166 Hvsp2HghVltgBsPssvIsltnTstStts "HVESP2 High-Voltage Bus Passive Isolation Test Status: Status of the high-voltage bus electrical passive isolation test as performed by this High Voltage Energy Storage Pack instance.This parameter is for one of multiple packs in an HVESS. If there i...";
CM_ SG_ 2364647166 Hvsp2HghVltgBsCnntnStts "HVESP2 High-Voltage Bus Connection Status: This parameter provides high level feedback on this High Voltage Energy Storage Pack instance high voltage bus connection.  For specific contactor information, see SPN 11191 (HVESP2 High-Voltage Bus (Positiv...";
CM_ BO_ 2364647422 "High Voltage Energy Storage Pack 2 Data 7";
CM_ SG_ 2364647422 Hvesp2DischargeEnergyCapacity "HVESP2 Discharge Energy Capacity: The amount of stored electrical energy in this High Voltage Energy Storage Pack instance that is available for use by the hybrid or EV system, i.e. 'how full is the tank'.  See SPN 11178 (HVESP2 Discharge Capacity) f...";
CM_ SG_ 2364647422 Hvesp2ChargeEnergyCapacity "HVESP2 Charge Energy Capacity: The amount of unused electrical energy storage available to be filled by charging this High Voltage Energy Storage Pack instance, i.e. 'how much empty space is remaining in the tank'.  See SPN 11179 (HVESP2 Charge Capac...";
CM_ SG_ 2364647422 Hvesp2MaximumChargeVoltageLimit "HVESP2 Maximum Charge Voltage Limit: The maximum voltage level not to be exceeded while charging this High Voltage Energy Storage Pack instance.  If this parameter is not supported, the maximum charge voltage should be limited to SPN 11250 (HVESP2 Re...";
CM_ BO_ 2364647678 "High Voltage Energy Storage Pack 2 Module Status 1";
CM_ SG_ 2364647678 Hvesp2Module1OperationalStatus "HVESP2 Module 1 Operational Status: Operational Status of Module 1 in this High Voltage Energy Storage Pack Instance.  Not Operational is used when the module is initializing or not able to function (e.g. internal module level monitors have failed). ...";
CM_ SG_ 2364647678 Hvesp2Module2OperationalStatus "HVESP2 Module 2 Operational Status: Operational Status of Module 2 in this High Voltage Energy Storage Pack Instance.  Not Operational is used when the module is initializing or not able to function (e.g. internal module level monitors have failed). ...";
CM_ SG_ 2364647678 Hvesp2Module3OperationalStatus "HVESP2 Module 3 Operational Status: Operational Status of Module 3 in this High Voltage Energy Storage Pack Instance.  Not Operational is used when the module is initializing or not able to function (e.g. internal module level monitors have failed). ...";
CM_ SG_ 2364647678 Hvesp2Module4OperationalStatus "HVESP2 Module 4 Operational Status: Operational Status of Module 4 in this High Voltage Energy Storage Pack Instance.  Not Operational is used when the module is initializing or not able to function (e.g. internal module level monitors have failed). ...";
CM_ SG_ 2364647678 Hvesp2Module5OperationalStatus "HVESP2 Module 5 Operational Status: Operational Status of Module 5 in this High Voltage Energy Storage Pack Instance.  Not Operational is used when the module is initializing or not able to function (e.g. internal module level monitors have failed). ...";
CM_ SG_ 2364647678 Hvesp2Module6OperationalStatus "HVESP2 Module 6 Operational Status: Operational Status of Module 6 in this High Voltage Energy Storage Pack Instance.  Not Operational is used when the module is initializing or not able to function (e.g. internal module level monitors have failed). ...";
CM_ SG_ 2364647678 Hvesp2Module7OperationalStatus "HVESP2 Module 7 Operational Status: Operational Status of Module 7 in this High Voltage Energy Storage Pack Instance.  Not Operational is used when the module is initializing or not able to function (e.g. internal module level monitors have failed). ...";
CM_ SG_ 2364647678 Hvesp2Module8OperationalStatus "HVESP2 Module 8 Operational Status: Operational Status of Module 8 in this High Voltage Energy Storage Pack Instance.  Not Operational is used when the module is initializing or not able to function (e.g. internal module level monitors have failed). ...";
CM_ SG_ 2364647678 Hvesp2Module9OperationalStatus "HVESP2 Module 9 Operational Status: Operational Status of Module 9 in this High Voltage Energy Storage Pack Instance.  Not Operational is used when the module is initializing or not able to function (e.g. internal module level monitors have failed). ...";
CM_ SG_ 2364647678 Hvesp2Module10OperationalStatus "HVESP2 Module 10 Operational Status: Operational Status of Module 10 in this High Voltage Energy Storage Pack Instance.  Not Operational is used when the module is initializing or not able to function (e.g. internal module level monitors have failed)...";
CM_ SG_ 2364647678 Hvesp2Module11OperationalStatus "HVESP2 Module 11 Operational Status: Operational Status of Module 11 in this High Voltage Energy Storage Pack Instance.  Not Operational is used when the module is initializing or not able to function (e.g. internal module level monitors have failed)...";
CM_ SG_ 2364647678 Hvesp2Module12OperationalStatus "HVESP2 Module 12 Operational Status: Operational Status of Module 12 in this High Voltage Energy Storage Pack Instance.  Not Operational is used when the module is initializing or not able to function (e.g. internal module level monitors have failed)...";
CM_ SG_ 2364647678 Hvesp2Module13OperationalStatus "HVESP2 Module 13 Operational Status: Operational Status of Module 13 in this High Voltage Energy Storage Pack Instance.  Not Operational is used when the module is initializing or not able to function (e.g. internal module level monitors have failed)...";
CM_ SG_ 2364647678 Hvesp2Module14OperationalStatus "HVESP2 Module 14 Operational Status: Operational Status of Module 14 in this High Voltage Energy Storage Pack Instance.  Not Operational is used when the module is initializing or not able to function (e.g. internal module level monitors have failed)...";
CM_ SG_ 2364647678 Hvesp2Module15OperationalStatus "HVESP2 Module 15 Operational Status: Operational Status of Module 15 in this High Voltage Energy Storage Pack Instance.  Not Operational is used when the module is initializing or not able to function (e.g. internal module level monitors have failed)...";
CM_ SG_ 2364647678 Hvesp2Module16OperationalStatus "HVESP2 Module 16 Operational Status: Operational Status of Module 16 in this High Voltage Energy Storage Pack Instance.  Not Operational is used when the module is initializing or not able to function (e.g. internal module level monitors have failed)...";
CM_ SG_ 2364647678 Hvesp2Module17OperationalStatus "HVESP2 Module 17 Operational Status: Operational Status of Module 17 in this High Voltage Energy Storage System (or Pack 1 in systems with only one pack).  Not Operational is used when the module is initializing or not able to function (e.g. internal...";
CM_ SG_ 2364647678 Hvesp2Module18OperationalStatus "HVESP2 Module 18 Operational Status: Operational Status of Module 18 in this High Voltage Energy Storage System (or Pack 1 in systems with only one pack).  Not Operational is used when the module is initializing or not able to function (e.g. internal...";
CM_ SG_ 2364647678 Hvesp2Module19OperationalStatus "HVESP2 Module 19 Operational Status: Operational Status of Module 19 in this High Voltage Energy Storage System (or Pack 1 in systems with only one pack).  Not Operational is used when the module is initializing or not able to function (e.g. internal...";
CM_ SG_ 2364647678 Hvesp2Module20OperationalStatus "HVESP2 Module 20 Operational Status: Operational Status of Module 20 in this High Voltage Energy Storage System (or Pack 1 in systems with only one pack).  Not Operational is used when the module is initializing or not able to function (e.g. internal...";
CM_ SG_ 2364647678 Hvesp2Module21OperationalStatus "HVESP2 Module 21 Operational Status: Operational Status of Module 21 in this High Voltage Energy Storage System (or Pack 1 in systems with only one pack).  Not Operational is used when the module is initializing or not able to function (e.g. internal...";
CM_ SG_ 2364647678 Hvesp2Module22OperationalStatus "HVESP2 Module 22 Operational Status: Operational Status of Module 22 in this High Voltage Energy Storage System (or Pack 1 in systems with only one pack).  Not Operational is used when the module is initializing or not able to function (e.g. internal...";
CM_ SG_ 2364647678 Hvesp2Module23OperationalStatus "HVESP2 Module 23 Operational Status: Operational Status of Module 23 in this High Voltage Energy Storage System (or Pack 1 in systems with only one pack).  Not Operational is used when the module is initializing or not able to function (e.g. internal...";
CM_ SG_ 2364647678 Hvesp2Module24OperationalStatus "HVESP2 Module 24 Operational Status: Operational Status of Module 24 in this High Voltage Energy Storage System (or Pack 1 in systems with only one pack).  Not Operational is used when the module is initializing or not able to function (e.g. internal...";
CM_ SG_ 2364647678 Hvesp2Module25OperationalStatus "HVESP2 Module 25 Operational Status: Operational Status of Module 25 in this High Voltage Energy Storage System (or Pack 1 in systems with only one pack).  Not Operational is used when the module is initializing or not able to function (e.g. internal...";
CM_ SG_ 2364647678 Hvesp2Module26OperationalStatus "HVESP2 Module 26 Operational Status: Operational Status of Module 26 in this High Voltage Energy Storage System (or Pack 1 in systems with only one pack).  Not Operational is used when the module is initializing or not able to function (e.g. internal...";
CM_ SG_ 2364647678 Hvesp2Module27OperationalStatus "HVESP2 Module 27 Operational Status: Operational Status of Module 27 in this High Voltage Energy Storage System (or Pack 1 in systems with only one pack).  Not Operational is used when the module is initializing or not able to function (e.g. internal...";
CM_ SG_ 2364647678 Hvesp2Module28OperationalStatus "HVESP2 Module 28 Operational Status: Operational Status of Module 28 in this High Voltage Energy Storage System (or Pack 1 in systems with only one pack).  Not Operational is used when the module is initializing or not able to function (e.g. internal...";
CM_ SG_ 2364647678 Hvesp2Module29OperationalStatus "HVESP2 Module 29 Operational Status: Operational Status of Module 29 in this High Voltage Energy Storage System (or Pack 1 in systems with only one pack).  Not Operational is used when the module is initializing or not able to function (e.g. internal...";
CM_ SG_ 2364647678 Hvesp2Module30OperationalStatus "HVESP2 Module 30 Operational Status: Operational Status of Module 30 in this High Voltage Energy Storage System (or Pack 1 in systems with only one pack).  Not Operational is used when the module is initializing or not able to function (e.g. internal...";
CM_ SG_ 2364647678 Hvesp2Module31OperationalStatus "HVESP2 Module 31 Operational Status: Operational Status of Module 31 in this High Voltage Energy Storage System (or Pack 1 in systems with only one pack).  Not Operational is used when the module is initializing or not able to function (e.g. internal...";
CM_ SG_ 2364647678 Hvesp2Module32OperationalStatus "HVESP2 Module 32 Operational Status: Operational Status of Module 32 in this High Voltage Energy Storage System (or Pack 1 in systems with only one pack).  Not Operational is used when the module is initializing or not able to function (e.g. internal...";
CM_ BO_ 2364647934 "High Voltage Energy Storage Pack 2 Thermal Management System Status 1";
CM_ SG_ 2364647934 Hvsp2ThrmlMngmntSstmSlInptPwr "HVESP2 Thermal Management System SLI Input Power: This is the low-voltage power consumed by this HVES Thermal Management System (TMS).This parameter is for one of multiple packs in an HVESS.  If there is only one pack in the system, the HVESS paramet...";
CM_ SG_ 2364647934 Hvsp2TMtSstHVtIptPw "HVESP2 Thermal Management System High-Voltage Input Power: This is the high-voltage power consumed by this HVES Thermal Management System (TMS).This parameter is for one of multiple packs in an HVESS.  If there is only one pack in the system, the HVE...";
CM_ SG_ 2364647934 Hvsp2ThrmlMngmntSstmCmprssrSpd "HVESP2 Thermal Management System Compressor Speed: When this High Voltage Energy Storage Pack Thermal Management System is equipped with an active cooling system (e.g. air conditioner), this is the Compressor Speed.This parameter is for one of multip...";
CM_ SG_ 2364647934 Hvsp2ThrmlMngmntSstmRltvHmdt "HVESP2 Thermal Management System Relative Humidty: When this High Voltage Energy Storage Pack Thermal Management System is equipped with a relative humidity sensor, this is the  measured Relative Humidity.This parameter is for one of multiple packs i...";
CM_ SG_ 2364647934 Hvsp2ThrmlMngmntSstmHtrStts "HVESP2 Thermal Management System Heater Status: The state of this High Voltage Energy Storage Pack heaterThis parameter is for one of multiple packs in an HVESS.  If there is only one pack in the system, the HVESS parameters should be used. If there ...";
CM_ SG_ 2364647934 Hvsp2ThrmlMngmntSstmHvlStts "HVESP2 Thermal Management System HVIL Status: In multiple HVES configurations, this is the status of the High Voltage Interlock Loop from the viewpoint of this Thermal Management System.00b = HVIL Closed01b = HVIL Open10b = Error11b = Not AvailableTh...";
CM_ SG_ 2364647934 Hvsp2ThrmlMngmntSstmMd "HVESP2 Thermal Management System Mode: Indicates the operating mode of the Thermal Management System.  The heat transfer medium may be (e.g. liquid or air).  The cooling system may be fans, liquid coolant, or a combination of mediums.  The system may...";
CM_ SG_ 2364647934 Hvsp2ThrmlMngmntSstmClntLvl "HVESP2 Thermal Management System Coolant Level: Indicates the coolant level in this HVES Thermal Management System (TMS).This parameter is for one of multiple packs in an HVESS.  If there is only one pack in the system, the HVESS parameters should be...";
CM_ BO_ 2364648190 "High Voltage Energy Storage Pack 2 Data 8";
CM_ SG_ 2364648190 Hvesp2AverageCellVoltage "HVESP2 Average Cell Voltage: The average cell voltage in this High Voltage Energy Storage Pack instance.This parameter is for one of multiple packs in an HVESS.  If there is only one pack in the system, the HVESS parameters should be used. If there a...";
CM_ SG_ 2364648190 Hvsp2HghstCllVltgMdlNmr "HVESP2 Highest Cell Voltage Module Number: Identifies the location of the module containing SPN 11171 (HVESP2 Highest Cell Voltage).This parameter is for one of multiple packs in an HVESS.  If there is only one pack in the system, the HVESS parameter...";
CM_ SG_ 2364648190 Hvsp2HghstCllVltgCllNmr "HVESP2 Highest Cell Voltage Cell Number: Identifies the location of SPN 11171 (HVESP2 Highest Cell Voltage) within SPN 11231 (HVESP2 Highest Cell Voltage Module Number).This parameter is for one of multiple packs in an HVESS.  If there is only one pa...";
CM_ SG_ 2364648190 Hvsp2LwstCllVltgMdlNmr "HVESP2 Lowest Cell Voltage Module Number: Identifies the location of the module containing SPN 11172 (HVESP2 Lowest Cell Voltage).This parameter is for one of multiple packs in an HVESS.  If there is only one pack in the system, the HVESS parameters ...";
CM_ SG_ 2364648190 Hvsp2LwstCllVltgCllNmr "HVESP2 Lowest Cell Voltage Cell Number: Identifies the location of SPN 11172 (HVESP2 Lowest Cell Voltage) within SPN 11233 (HVESP2 Lowest Cell Voltage Module Number).This parameter is for one of multiple packs in an HVESS.  If there is only one pack ...";
CM_ BO_ 2364648446 "High Voltage Energy Storage Pack 2 Data 9";
CM_ SG_ 2364648446 Hvsp2HghstCllTmprtrMdlNmr "HVESP2 Highest Cell Temperature Module Number: Identifies the location of the module containing SPN 11174 (HVESP2 Highest Cell Temperature).This parameter is for one of multiple packs in an HVESS.  If there is only one pack in the system, the HVESS p...";
CM_ SG_ 2364648446 Hvsp2HghstCllTmprtrCllNmr "HVESP2 Highest Cell Temperature Cell Number: Identifies the location of SPN 11174 (HVESP2 Highest Cell Temperature) within SPN 11236 (HVESP2 Highest Cell Temperature Module Number).This parameter is for one of multiple packs in an HVESS.  If there is...";
CM_ SG_ 2364648446 Hvsp2LwstCllTmprtrMdlNmr "HVESP2 Lowest Cell Temperature Module Number: Identifies the location of the module containing SPN 11175 (HVESP2 Lowest Cell Temperature).This parameter is for one of multiple packs in an HVESS.  If there is only one pack in the system, the HVESS par...";
CM_ SG_ 2364648446 Hvsp2LwstCllTmprtrCllNmr "HVESP2 Lowest Cell Temperature Cell Number: Identifies the location of SPN 11175 (HVESP2 Lowest Cell Temperature) within SPN 11238 (HVESP2 Lowest Cell Temperature Module Number).This parameter is for one of multiple packs in an HVESS.  If there is on...";
CM_ SG_ 2364648446 Hvess2ThermalEventDetected "HVESS2 Thermal Event Detected: A sensor has detected the presence of a thermal event at or near High Voltage Energy Storage Pack instance.00b = No Thermal Event Detected01b = Thermal Event Detected10b = Error11b = Not availableThis parameter is for o...";
CM_ SG_ 2364648446 Hvsp2Dt9EmdddIntgrtSpprt "HVESP2 Data 9 Embedded Integrity Support: Indicates SPN 22979 (HVESP2 Data 9 CRC) and SPN 22978 (HVESP2 Data 9 Counter) are supported by the sender.00b = Embedded CRC and Counter are supported by the sender01b = Protection is provided using an extern...";
CM_ SG_ 2364648446 Hvesp2Data9Counter "HVESP2 Data 9 Counter: The message counter is used to detect situations where the transmitting ECU malfunction repeats the same frame all the time. The receiver of the information may use the counter parameter to detect this situation. The transmitti...";
CM_ SG_ 2364648446 Hvesp2Data9Crc "HVESP2 Data 9 CRC: The CRC is defined as follows: - Length: 8 bits- Polynomial: x^8+x^5+x^3+x^2+x+1- Initial Value: FFh- Input Data Reflection: Not reflected- Result Data Reflection: Not reflected- XOR value: FFh SAE makes no claim of the functional ...";
CM_ BO_ 2364648702 "High Voltage Energy Storage Pack 2 Data 10";
CM_ SG_ 2364648702 Hvsp2HghstCllSttOfChrgMdlNmr "HVESP2 Highest Cell State of Charge Module Number: Identifies the location of the module containing SPN 11184 (HVESP2 Highest Cell State of Charge).This parameter is for one of multiple packs in an HVESS.  If there is only one pack in the system, the...";
CM_ SG_ 2364648702 Hvsp2HghstCllSttOfChrgCllNmr "HVESP2 Highest Cell State of Charge Cell Number: Identifies the location of SPN 11184 (HVESP2 Highest Cell State of Charge) within SPN 11240 (HVESP2 Highest Cell State of Charge Module Number).This parameter is for one of multiple packs in an HVESS. ...";
CM_ SG_ 2364648702 Hvsp2LwstCllSttOfChrgMdlNmr "HVESP2 Lowest Cell State of Charge Module Number: Identifies the location of the module containing SPN 11183 (HVESP2 Lowest Cell State of Charge).This parameter is for one of multiple packs in an HVESS.  If there is only one pack in the system, the H...";
CM_ SG_ 2364648702 Hvsp2LwstCllSttOfChrgCllNmr "HVESP2 Lowest Cell State of Charge Cell Number: Identifies the location of SPN 11183 (HVESP2 Lowest Cell State of Charge) within SPN 11242 (HVESP2 Lowest Cell State of Charge Module Number).This parameter is for one of multiple packs in an HVESS.  If...";
CM_ SG_ 2364648702 Hvsp2HghVltgBsAtvIsltnTstRslts "HVESP2 High-Voltage Bus Active Isolation Test Results: The isolation resistance expressed in Ohms per Volt that resulted from the High-Voltage Bus Active Isolation Test.See SPN 11196 (HVESP2 High-Voltage Bus Active Isolation Test Status) for test sta...";
CM_ SG_ 2364648702 Hvsp2HghVltgBsPssvIsltnTstRslts "HVESP2 High-Voltage Bus Passive Isolation Test Results: The isolation resistance expressed in Ohms per Volt that resulted from the High-Voltage Bus Passive Isolation Test.See SPN 11197 (HVESP2 High-Voltage Bus Passive Isolation Test Status) for test ...";
CM_ BO_ 2364648958 "High Voltage Energy Storage Pack 2 Data 11";
CM_ SG_ 2364648958 Hvesp2ActualChargeRate "HVESP2 Actual Charge Rate: This signal represents the actual present charge rate of this High Voltage Energy Storage Pack instance.This parameter is for one of multiple packs in an HVESS. If there is only one pack in the system, the HVESS parameters ...";
CM_ SG_ 2364648958 Hvsp2BsVltgNgtvTChsssGrndVltg "HVESP2 Bus Voltage Negative to Chassis Ground Voltage: Voltage difference between the most negative terminal of the HVES battery and chassis measured on the hybrid or EV system bus side (not the battery side) of any HVES contained output contactor.  ...";
CM_ SG_ 2364648958 Hvsp2VltgLvlNgtvTChsssGrndVltg "HVESP2 Voltage Level Negative to Chassis Ground Voltage: Voltage difference between the most negative terminal of the HVES battery and chassis measured at the battery side of any HVES contained output contactor.  This voltage may be used for system l...";
CM_ BO_ 2364649214 "High Voltage Energy Storage Pack 3 Status 2";
CM_ SG_ 2364649214 Hvsp3DshrgPwrLmtDTSttOfChrg "HVESP3 Discharge Power Limit Due to State of Charge: Indicates whether or not discharge power of this HVES instance is being limited due to state of charge.This parameter is for one of multiple packs in an HVESS.  If there is only one pack in the sys...";
CM_ SG_ 2364649214 Hvsp3DshrgPwrLmtDTBttrTmprtr "HVESP3 Discharge Power Limit Due to Battery Temperature: Indicates whether or not discharge power of this HVES instance is being limited due to battery temperature.This parameter is for one of multiple packs in an HVESS.  If there is only one pack in...";
CM_ SG_ 2364649214 Hvsp3DsPwLtDTBttDstCdt "HVESP3 Discharge Power Limit Due to Battery Diagnostic Condition: Indicates whether or not discharge power of this HVES instance is being limited due to a battery diagnostic condition.This parameter is for one of multiple packs in an HVESS.  If there...";
CM_ SG_ 2364649214 Hvsp3DshrgPwrLmtDTBttrOrCllVltg "HVESP3 Discharge Power Limit Due to Battery or Cell Voltage: Indicates whether or not discharge power of this HVES instance is being limited due to a battery or cell voltage level.This parameter is for one of multiple packs in an HVESS.  If there is ...";
CM_ SG_ 2364649214 Hvsp3DshrgPwrLmtDTBttrCrrnt "HVESP3 Discharge Power Limit Due to Battery Current: Indicates whether or not discharge power of this HVES instance is being limited due to battery current.This parameter is for one of multiple packs in an HVESS.  If there is only one pack in the sys...";
CM_ SG_ 2364649214 Hvsp3DshrgPwrLmtDTAnUndfndCs "HVESP3 Discharge Power Limit Due to an Undefined Cause: Indicates whether or not discharge power of this HVES instance is being limited due to an undefined cause.This parameter is for one of multiple packs in an HVESS.  If there is only one pack in t...";
CM_ SG_ 2364649214 Hvsp3ChrgPwrLmtDTSttOfChrg "HVESP3 Charge Power Limit Due to State of Charge: Indicates whether or not charge power of this HVES instance is being limited due to state of charge.This parameter is for one of multiple packs in an HVESS.  If there is only one pack in the system, t...";
CM_ SG_ 2364649214 Hvsp3ChrgPwrLmtDTBttrTmprtr "HVESP3 Charge Power Limit Due to Battery Temperature: Indicates whether or not charge power of this HVES instance is being limited due to battery temperature.This parameter is for one of multiple packs in an HVESS.  If there is only one pack in the s...";
CM_ SG_ 2364649214 Hvsp3ChrgPwrLmtDTBttrDgnstCndtn "HVESP3 Charge Power Limit Due to Battery Diagnostic Condition: Indicates whether or not charge power of this HVES instance is being limited due to a battery diagnostic condition.This parameter is for one of multiple packs in an HVESS.  If there is on...";
CM_ SG_ 2364649214 Hvsp3ChrgPwrLmtDTBttrOrCllVltg "HVESP3 Charge Power Limit Due to Battery or Cell Voltage: Indicates whether or not charge power of this HVES instance is being limited due to a battery or cell voltage level.This parameter is for one of multiple packs in an HVESS.  If there is only o...";
CM_ SG_ 2364649214 Hvsp3ChrgPwrLmtDTBttrCrrnt "HVESP3 Charge Power Limit Due to Battery Current: Indicates whether or not charge power of this HVES instance is being limited due to battery current.This parameter is for one of multiple packs in an HVESS.  If there is only one pack in the system, t...";
CM_ SG_ 2364649214 Hvsp3ChrgPwrLmtDTAnUndfndCs "HVESP3 Charge Power Limit Due to an Undefined Cause: Indicates whether or not charge power of this HVES instance is being limited due to an undefined cause.This parameter is for one of multiple packs in an HVESS.  If there is only one pack in the sys...";
CM_ BO_ 2364649470 "High Voltage Energy Storage Pack 3 Data 1";
CM_ SG_ 2364649470 Hvesp3AvailableDischargePower "HVESP3 Available Discharge Power: The rate at which this High Voltage Energy Storage Pack instance can currently provide energy for propulsion or other uses.This parameter is for one of multiple packs in an HVESS.  If there is only one pack in the sy...";
CM_ SG_ 2364649470 Hvesp3AvailableChargePower "HVESP3 Available Charge Power: The rate at which this High Voltage Energy Storage Pack instance can currently receive energy from a regenerative or recharging system.This parameter is for one of multiple packs in an HVESS.  If there is only one pack ...";
CM_ SG_ 2364649470 Hvesp3VoltageLevel "HVESP3 Voltage Level: The voltage level of this High Voltage Energy Storage Pack instance. This parameter should be synchronized with SPN 11285 (HVESP3 Current) such that a realized power value can be calculated.  If the HVES component physically con...";
CM_ SG_ 2364649470 Hvesp3Current "HVESP3 Current: The current in or out of this High Voltage Energy Storage Pack instance. This parameter should be synchronized with SPN 11284 (HVESP3 Voltage Level) such that a realized power value can be calculated.  This parameter is defined from t...";
CM_ BO_ 2364649726 "High Voltage Energy Storage Pack 3 Data 2";
CM_ SG_ 2364649726 Hvesp3FastUpdateStateOfCharge "HVESP3 Fast Update State of Charge: Indicates this High Voltage Energy Storage Pack instance state of charge.  0% means no charge remaining, 100% means the system is fully charged in terms of physical limits of this energy storage pack instance.  Acc...";
CM_ SG_ 2364649726 Hvesp3HighestCellVoltage "HVESP3 Highest Cell Voltage: The highest voltage level reported by any cell in this High Voltage Energy Storage Pack instance. If a single voltage sensor covers more than one cell, the value in this parameter is for the smallest group of cells measur...";
CM_ SG_ 2364649726 Hvesp3LowestCellVoltage "HVESP3 Lowest Cell Voltage: The lowest voltage level reported by any cell in this High Voltage Energy Storage Pack instance. If a single voltage sensor covers more than one cell, the value in this parameter is for the smallest group of cells measured...";
CM_ SG_ 2364649726 Hvsp3CllVltgDffrntlStts "HVESP3 Cell Voltage Differential Status: Indicates whether or not the differential between the highest and lowest cell voltages are within acceptable limits, according to this High Voltage Energy Storage Pack instance. The actual voltage differential...";
CM_ BO_ 2364649982 "High Voltage Energy Storage Pack 3 Data 3";
CM_ SG_ 2364649982 Hvesp3HighestCellTemperature "HVESP3 Highest Cell Temperature: The highest temperature level reported by any cell in this High Voltage Energy Storage Pack instance.  If a single temperature sensor covers more than one cell, the value in this parameter is for the smallest group of...";
CM_ SG_ 2364649982 Hvesp3LowestCellTemperature "HVESP3 Lowest Cell Temperature: The lowest temperature level reported by any cell in this High Voltage Energy Storage Pack instance.  If a single temperature sensor covers more than one cell, the value in this parameter is for the smallest group of c...";
CM_ SG_ 2364649982 Hvesp3AverageCellTemperature "HVESP3 Average Cell Temperature: The average temperature level of all cells in this High Voltage Energy Storage Pack instance.This parameter is for one of multiple packs in an HVESS.  If there is only one pack in the system, the HVESS parameters shou...";
CM_ SG_ 2364649982 Hvsp3CllTmprtrDffrntlStts "HVESP3 Cell Temperature Differential Status: Indicates whether or not the differential between the highest and lowest cell temperatures are within acceptable limits per this High Voltage Energy Storage Pack instance.  The actual temperature different...";
CM_ BO_ 2364650238 "High Voltage Energy Storage Pack 3 Data 4";
CM_ SG_ 2364650238 Hvesp3DischargeCapacity "HVESP3 Discharge Capacity: The amount of stored electrical charge in this High Voltage Energy Storage Pack instance that is available for use by the hybrid or EV system, i.e. 'how full is the tank'.  See SPN 11322 (HVESP3 Discharge Energy Capacity) f...";
CM_ SG_ 2364650238 Hvesp3ChargeCapacity "HVESP3 Charge Capacity: The amount of unused electrical charge storage in this High Voltage Energy Storage Pack instance that is available to be filled by charging, i.e. 'how much empty space is remaining in the tank'.  See SPN 11323 (HVESP3 Charge E...";
CM_ SG_ 2364650238 Hvesp3CellBalancingCount "HVESP3 Cell Balancing Count: The number of cells that are currently being balanced in this High Voltage Energy Storage Pack instance.This parameter is for one of multiple packs in an HVESS.  If there is only one pack in the system, the HVESS paramete...";
CM_ BO_ 2364650494 "High Voltage Energy Storage Pack 3 Data 5";
CM_ SG_ 2364650494 Hvesp3LowestCellStateOfCharge "HVESP3 Lowest Cell State of Charge: Indicates the state of charge of the lowest-charged cell in this High Voltage Energy Storage Pack instance.  0% means no charge remaining, 100% means the cell is fully charged.   If a single state of charge value c...";
CM_ SG_ 2364650494 Hvesp3HighestCellStateOfCharge "HVESP3 Highest Cell State of Charge: Indicates the state of charge of the highest-charged cell in this High Voltage Energy Storage Pack instance.  0% means no charge remaining, 100% means the cell is fully charged.  If a single state of charge value ...";
CM_ SG_ 2364650494 Hvsp3MxmmInstntnsDshrgCrrntLmt "HVESP3 Maximum Instantaneous Discharge Current Limit: The maximum instantaneous current flow limit out of this High Voltage Energy Storage Pack instance. This parameter is defined from the high voltage energy storage pack's point of view and should r...";
CM_ SG_ 2364650494 Hvsp3MxmmInstntnsChrgCrrntLmt "HVESP3 Maximum Instantaneous Charge Current Limit: The maximum instantaneous current flow limit into this High Voltage Energy Storage Pack instance. This parameter is defined from the high voltage energy storage pack's point of view and should reflec...";
CM_ BO_ 2364650750 "High Voltage Energy Storage Pack 3 Data 6";
CM_ SG_ 2364650750 Hvesp3BusVoltage "HVESP3 Bus Voltage: The voltage level of the high voltage bus, as measured by this High Voltage Energy Storage Pack instance on the bus side (not the battery side) of its contactors.This parameter is for one of multiple packs in an HVESS.  If there i...";
CM_ SG_ 2364650750 Hvesp3IgnitionVoltage "HVESP3 Ignition Voltage: The voltage level at the ignition input of this High Voltage Energy Storage Pack controller.This parameter is for one of multiple packs in an HVESS.  If there is only one pack in the system, the HVESS parameters should be use...";
CM_ SG_ 2364650750 Hvesp3IntakeCoolantTemperature "HVESP3 Intake Coolant Temperature: The temperature of liquid coolant as it enters this High Voltage Energy Storage Pack instance.This parameter is for one of multiple packs in an HVESS.  If there is only one pack in the system, the HVESS parameters s...";
CM_ SG_ 2364650750 Hvesp3OutletCoolantTemperature "HVESP3 Outlet Coolant Temperature: The temperature of liquid coolant as it exits this High Voltage Energy Storage Pack instance.This parameter is for one of multiple packs in an HVESS.  If there is only one pack in the system, the HVESS parameters sh...";
CM_ SG_ 2364650750 Hvesp3ElectronicsTemperature "HVESP3 Electronics Temperature: The temperature of the electronics or control modules in this High Voltage Energy Storage Pack instance.  If there are multiple temperature sensors then this parameter would be set to the maximum sensor reading.This pa...";
CM_ SG_ 2364650750 Hvesp3Temperature "HVESP3 Temperature: The temperature of this High Voltage Energy Storage Pack instance. The value may be determined from a unique sensor specifically for this purpose, or by aggregating various temperature sensor readings within the pack.This paramete...";
CM_ BO_ 2364651006 "High Voltage Energy Storage Pack 3 Status 1";
CM_ SG_ 2364651006 Hvesp3HvilStatus "HVESP3 HVIL Status: Status of the High Voltage Interlock Loop from the viewpoint of this High Voltage Energy Storage Pack instance.This parameter is for one of multiple packs in an HVESS. If there is only one pack in the system, the HVESS parameters ...";
CM_ SG_ 2364651006 Hvesp3InertiaSwitchStatus "HVESP3 Inertia Switch Status: Switch indicating that an impact has been sensed by this High Voltage Energy Storage Pack instance. The impact indication may require action by another controller, or by this HVES instance itself.  For example, a control...";
CM_ SG_ 2364651006 Hvesp3StateOfChargeStatus "HVESP3 State of Charge Status: Status of this High Voltage Energy Storage Pack instance State of Charge (SOC).  Note:  A given HVES controller may not support all of the states.This parameter is for one of multiple packs in an HVESS.  If there is onl...";
CM_ SG_ 2364651006 Hvesp3CellBalanceStatus "HVESP3 Cell Balance Status: Indicates whether or not the cells in this High Voltage Energy Storage Pack instance are balanced.This parameter is for one of multiple packs in an HVESS.  If there is only one pack in the system, the HVESS parameters shou...";
CM_ SG_ 2364651006 Hvesp3CellBalancingActive "HVESP3 Cell Balancing Active: Indicates whether or not the cells in this High Voltage Energy Storage Pack instance are currently being balanced.This parameter is for one of multiple packs in an HVESS.  If there is only one pack in the system, the HVE...";
CM_ SG_ 2364651006 Hvesp3InternalChargerStatus "HVESP3 Internal Charger Status: Indicates that the charger in this HVES instance is on.  External chargers may use the External Energy Source Connection Status (SPN 7898) and related SPs.This parameter is for one of multiple packs in an HVESS. If the...";
CM_ SG_ 2364651006 Hvesp3OperationalStatus "HVESP3 Operational Status: Provides feedback on where this High Voltage Energy Storage Pack instance is in its operating spectrum, and includes feedback in response to the Operation Consent [i.e. SPN 11267 (HVESP3 Operation Consent)] and Power Down C...";
CM_ SG_ 2364651006 Hvesp3Status1Counter "HVESP3 Status 1 Counter: The message counter is used to detect situations where the transmitting ECU malfunction repeats the same frame all the time. The receiver of the information may use the counter parameter to detect this situation. The transmit...";
CM_ SG_ 2364651006 Hvesp3Status1Crc "HVESP3 Status 1 CRC: The CRC is defined as follows: - Length: 8 bits- Polynomial: x^8+x^5+x^3+x^2+x+1- Initial Value: FFh- Input Data Reflection: Not reflected- Result Data Reflection: Not reflected- XOR value: FFh SAE makes no claim of the functiona...";
CM_ SG_ 2364651006 Hvsp3HghVltgBsPstvCnttrStt "HVESP3 High-Voltage Bus (Positive) Contactor State: Position of this High Voltage Energy Storage Pack instance positive side bus contactor.  When this contactor is closed, the positive side of this HVES instance is connected to the positive side of t...";
CM_ SG_ 2364651006 Hvsp3HghVltgBsNgtvCnttrStt "HVESP3 High-Voltage Bus (Negative) Contactor State: Position of this High Voltage Energy Storage Pack instance negative side bus contactor.  When this contactor is closed, the negative side of this HVES instance is connected to the negative side of t...";
CM_ SG_ 2364651006 Hvsp3HghVltgBsDsnntFrwrnng "HVESP3 High-Voltage Bus Disconnect Forewarning: Indicates that this High Voltage Energy Storage Pack instance is about to disconnect from the high voltage bus due to unacceptable conditions.This parameter is for one of multiple packs in an HVESS. If ...";
CM_ SG_ 2364651006 Hvsp3HghVltgBsPrChrgRlStt "HVESP3 High-Voltage Bus Pre-Charge Relay State: Position of the high-voltage bus contactor pre-charge relay.  When this relay is closed, this High Voltage Energy Storage Pack instance is bringing the high-voltage bus up to its operating level.This pa...";
CM_ SG_ 2364651006 Hvsp3CntrOfPkCnttrStt "HVESP3 Center of Pack Contactor State: Position of the center high-voltage contactor.  When this contactor is closed, the positive half of this High Voltage Energy Storage Pack instance is connected to the negative half.  If a system controls the pos...";
CM_ SG_ 2364651006 Hvsp3HghVltgBsAtvIsltnTstStts "HVESP3 High-Voltage Bus Active Isolation Test Status: Status of the high-voltage bus electrical active isolation test as performed by this High Voltage Energy Storage Pack instance.This parameter is for one of multiple packs in an HVESS. If there is ...";
CM_ SG_ 2364651006 Hvsp3HghVltgBsPssvIsltnTstStts "HVESP3 High-Voltage Bus Passive Isolation Test Status: Status of the high-voltage bus electrical passive isolation test as performed by this High Voltage Energy Storage Pack instance.This parameter is for one of multiple packs in an HVESS. If there i...";
CM_ SG_ 2364651006 Hvsp3HghVltgBsCnntnStts "HVESP3 High-Voltage Bus Connection Status: This parameter provides high level feedback on this High Voltage Energy Storage Pack instance high voltage bus connection.  For specific contactor information, see SPN 11307 (HVESP3 High-Voltage Bus (Positiv...";
CM_ BO_ 2364651262 "High Voltage Energy Storage Pack 3 Data 7";
CM_ SG_ 2364651262 Hvesp3DischargeEnergyCapacity "HVESP3 Discharge Energy Capacity: The amount of stored electrical energy in this High Voltage Energy Storage Pack instance that is available for use by the hybrid or EV system, i.e. 'how full is the tank'.  See SPN 11294 (HVESP3 Discharge Capacity) f...";
CM_ SG_ 2364651262 Hvesp3ChargeEnergyCapacity "HVESP3 Charge Energy Capacity: The amount of unused electrical energy storage available to be filled by charging this High Voltage Energy Storage Pack instance, i.e. 'how much empty space is remaining in the tank'.  See SPN 11295 (HVESP3 Charge Capac...";
CM_ SG_ 2364651262 Hvesp3MaximumChargeVoltageLimit "HVESP3 Maximum Charge Voltage Limit: The maximum voltage level not to be exceeded while charging this High Voltage Energy Storage Pack instance.  If this parameter is not supported, the maximum charge voltage should be limited to SPN 11366 (HVESP3 Re...";
CM_ BO_ 2364651518 "High Voltage Energy Storage Pack 3 Module Status 1";
CM_ SG_ 2364651518 Hvesp3Module1OperationalStatus "HVESP3 Module 1 Operational Status: Operational Status of Module 1 in this High Voltage Energy Storage Pack Instance.  Not Operational is used when the module is initializing or not able to function (e.g. internal module level monitors have failed). ...";
CM_ SG_ 2364651518 Hvesp3Module2OperationalStatus "HVESP3 Module 2 Operational Status: Operational Status of Module 2 in this High Voltage Energy Storage Pack Instance.  Not Operational is used when the module is initializing or not able to function (e.g. internal module level monitors have failed). ...";
CM_ SG_ 2364651518 Hvesp3Module3OperationalStatus "HVESP3 Module 3 Operational Status: Operational Status of Module 3 in this High Voltage Energy Storage Pack Instance.  Not Operational is used when the module is initializing or not able to function (e.g. internal module level monitors have failed). ...";
CM_ SG_ 2364651518 Hvesp3Module4OperationalStatus "HVESP3 Module 4 Operational Status: Operational Status of Module 4 in this High Voltage Energy Storage Pack Instance.  Not Operational is used when the module is initializing or not able to function (e.g. internal module level monitors have failed). ...";
CM_ SG_ 2364651518 Hvesp3Module5OperationalStatus "HVESP3 Module 5 Operational Status: Operational Status of Module 5 in this High Voltage Energy Storage Pack Instance.  Not Operational is used when the module is initializing or not able to function (e.g. internal module level monitors have failed). ...";
CM_ SG_ 2364651518 Hvesp3Module6OperationalStatus "HVESP3 Module 6 Operational Status: Operational Status of Module 6 in this High Voltage Energy Storage Pack Instance.  Not Operational is used when the module is initializing or not able to function (e.g. internal module level monitors have failed). ...";
CM_ SG_ 2364651518 Hvesp3Module7OperationalStatus "HVESP3 Module 7 Operational Status: Operational Status of Module 7 in this High Voltage Energy Storage Pack Instance.  Not Operational is used when the module is initializing or not able to function (e.g. internal module level monitors have failed). ...";
CM_ SG_ 2364651518 Hvesp3Module8OperationalStatus "HVESP3 Module 8 Operational Status: Operational Status of Module 8 in this High Voltage Energy Storage Pack Instance.  Not Operational is used when the module is initializing or not able to function (e.g. internal module level monitors have failed). ...";
CM_ SG_ 2364651518 Hvesp3Module9OperationalStatus "HVESP3 Module 9 Operational Status: Operational Status of Module 9 in this High Voltage Energy Storage Pack Instance.  Not Operational is used when the module is initializing or not able to function (e.g. internal module level monitors have failed). ...";
CM_ SG_ 2364651518 Hvesp3Module10OperationalStatus "HVESP3 Module 10 Operational Status: Operational Status of Module 10 in this High Voltage Energy Storage Pack Instance.  Not Operational is used when the module is initializing or not able to function (e.g. internal module level monitors have failed)...";
CM_ SG_ 2364651518 Hvesp3Module11OperationalStatus "HVESP3 Module 11 Operational Status: Operational Status of Module 11 in this High Voltage Energy Storage Pack Instance.  Not Operational is used when the module is initializing or not able to function (e.g. internal module level monitors have failed)...";
CM_ SG_ 2364651518 Hvesp3Module12OperationalStatus "HVESP3 Module 12 Operational Status: Operational Status of Module 12 in this High Voltage Energy Storage Pack Instance.  Not Operational is used when the module is initializing or not able to function (e.g. internal module level monitors have failed)...";
CM_ SG_ 2364651518 Hvesp3Module13OperationalStatus "HVESP3 Module 13 Operational Status: Operational Status of Module 13 in this High Voltage Energy Storage Pack Instance.  Not Operational is used when the module is initializing or not able to function (e.g. internal module level monitors have failed)...";
CM_ SG_ 2364651518 Hvesp3Module14OperationalStatus "HVESP3 Module 14 Operational Status: Operational Status of Module 14 in this High Voltage Energy Storage Pack Instance.  Not Operational is used when the module is initializing or not able to function (e.g. internal module level monitors have failed)...";
CM_ SG_ 2364651518 Hvesp3Module15OperationalStatus "HVESP3 Module 15 Operational Status: Operational Status of Module 15 in this High Voltage Energy Storage Pack Instance.  Not Operational is used when the module is initializing or not able to function (e.g. internal module level monitors have failed)...";
CM_ SG_ 2364651518 Hvesp3Module16OperationalStatus "HVESP3 Module 16 Operational Status: Operational Status of Module 16 in this High Voltage Energy Storage Pack Instance.  Not Operational is used when the module is initializing or not able to function (e.g. internal module level monitors have failed)...";
CM_ SG_ 2364651518 Hvesp3Module17OperationalStatus "HVESP3 Module 17 Operational Status: Operational Status of Module 17 in this High Voltage Energy Storage System (or Pack 1 in systems with only one pack).  Not Operational is used when the module is initializing or not able to function (e.g. internal...";
CM_ SG_ 2364651518 Hvesp3Module18OperationalStatus "HVESP3 Module 18 Operational Status: Operational Status of Module 18 in this High Voltage Energy Storage System (or Pack 1 in systems with only one pack).  Not Operational is used when the module is initializing or not able to function (e.g. internal...";
CM_ SG_ 2364651518 Hvesp3Module19OperationalStatus "HVESP3 Module 19 Operational Status: Operational Status of Module 19 in this High Voltage Energy Storage System (or Pack 1 in systems with only one pack).  Not Operational is used when the module is initializing or not able to function (e.g. internal...";
CM_ SG_ 2364651518 Hvesp3Module20OperationalStatus "HVESP3 Module 20 Operational Status: Operational Status of Module 20 in this High Voltage Energy Storage System (or Pack 1 in systems with only one pack).  Not Operational is used when the module is initializing or not able to function (e.g. internal...";
CM_ SG_ 2364651518 Hvesp3Module21OperationalStatus "HVESP3 Module 21 Operational Status: Operational Status of Module 21 in this High Voltage Energy Storage System (or Pack 1 in systems with only one pack).  Not Operational is used when the module is initializing or not able to function (e.g. internal...";
CM_ SG_ 2364651518 Hvesp3Module22OperationalStatus "HVESP3 Module 22 Operational Status: Operational Status of Module 22 in this High Voltage Energy Storage System (or Pack 1 in systems with only one pack).  Not Operational is used when the module is initializing or not able to function (e.g. internal...";
CM_ SG_ 2364651518 Hvesp3Module23OperationalStatus "HVESP3 Module 23 Operational Status: Operational Status of Module 23 in this High Voltage Energy Storage System (or Pack 1 in systems with only one pack).  Not Operational is used when the module is initializing or not able to function (e.g. internal...";
CM_ SG_ 2364651518 Hvesp3Module24OperationalStatus "HVESP3 Module 24 Operational Status: Operational Status of Module 24 in this High Voltage Energy Storage System (or Pack 1 in systems with only one pack).  Not Operational is used when the module is initializing or not able to function (e.g. internal...";
CM_ SG_ 2364651518 Hvesp3Module25OperationalStatus "HVESP3 Module 25 Operational Status: Operational Status of Module 25 in this High Voltage Energy Storage System (or Pack 1 in systems with only one pack).  Not Operational is used when the module is initializing or not able to function (e.g. internal...";
CM_ SG_ 2364651518 Hvesp3Module26OperationalStatus "HVESP3 Module 26 Operational Status: Operational Status of Module 26 in this High Voltage Energy Storage System (or Pack 1 in systems with only one pack).  Not Operational is used when the module is initializing or not able to function (e.g. internal...";
CM_ SG_ 2364651518 Hvesp3Module27OperationalStatus "HVESP3 Module 27 Operational Status: Operational Status of Module 27 in this High Voltage Energy Storage System (or Pack 1 in systems with only one pack).  Not Operational is used when the module is initializing or not able to function (e.g. internal...";
CM_ SG_ 2364651518 Hvesp3Module28OperationalStatus "HVESP3 Module 28 Operational Status: Operational Status of Module 28 in this High Voltage Energy Storage System (or Pack 1 in systems with only one pack).  Not Operational is used when the module is initializing or not able to function (e.g. internal...";
CM_ SG_ 2364651518 Hvesp3Module29OperationalStatus "HVESP3 Module 29 Operational Status: Operational Status of Module 29 in this High Voltage Energy Storage System (or Pack 1 in systems with only one pack).  Not Operational is used when the module is initializing or not able to function (e.g. internal...";
CM_ SG_ 2364651518 Hvesp3Module30OperationalStatus "HVESP3 Module 30 Operational Status: Operational Status of Module 30 in this High Voltage Energy Storage System (or Pack 1 in systems with only one pack).  Not Operational is used when the module is initializing or not able to function (e.g. internal...";
CM_ SG_ 2364651518 Hvesp3Module31OperationalStatus "HVESP3 Module 31 Operational Status: Operational Status of Module 31 in this High Voltage Energy Storage System (or Pack 1 in systems with only one pack).  Not Operational is used when the module is initializing or not able to function (e.g. internal...";
CM_ SG_ 2364651518 Hvesp3Module32OperationalStatus "HVESP3 Module 32 Operational Status: Operational Status of Module 32 in this High Voltage Energy Storage System (or Pack 1 in systems with only one pack).  Not Operational is used when the module is initializing or not able to function (e.g. internal...";
CM_ BO_ 2364651774 "High Voltage Energy Storage Pack 3 Thermal Management System Status 1";
CM_ SG_ 2364651774 Hvsp3ThrmlMngmntSstmSlInptPwr "HVESP3 Thermal Management System SLI Input Power: This is the low-voltage power consumed by this HVES Thermal Management System (TMS).This parameter is for one of multiple packs in an HVESS.  If there is only one pack in the system, the HVESS paramet...";
CM_ SG_ 2364651774 Hvsp3TMtSstHVtIptPw "HVESP3 Thermal Management System High-Voltage Input Power: This is the high-voltage power consumed by this HVES Thermal Management System (TMS).This parameter is for one of multiple packs in an HVESS.  If there is only one pack in the system, the HVE...";
CM_ SG_ 2364651774 Hvsp3ThrmlMngmntSstmCmprssrSpd "HVESP3 Thermal Management System Compressor Speed: When this High Voltage Energy Storage Pack Thermal Management System is equipped with an active cooling system (e.g. air conditioner), this is the Compressor Speed.This parameter is for one of multip...";
CM_ SG_ 2364651774 Hvsp3ThrmlMngmntSstmRltvHmdt "HVESP3 Thermal Management System Relative Humidty: When this High Voltage Energy Storage Pack Thermal Management System is equipped with a relative humidity sensor, this is the  measured Relative Humidity.This parameter is for one of multiple packs i...";
CM_ SG_ 2364651774 Hvsp3ThrmlMngmntSstmHtrStts "HVESP3 Thermal Management System Heater Status: The state of this High Voltage Energy Storage Pack heaterThis parameter is for one of multiple packs in an HVESS.  If there is only one pack in the system, the HVESS parameters should be used. If there ...";
CM_ SG_ 2364651774 Hvsp3ThrmlMngmntSstmHvlStts "HVESP3 Thermal Management System HVIL Status: In multiple HVES configurations, this is the status of the High Voltage Interlock Loop from the viewpoint of this Thermal Management System.00b = HVIL Closed01b = HVIL Open10b = Error11b = Not AvailableTh...";
CM_ SG_ 2364651774 Hvsp3ThrmlMngmntSstmMd "HVESP3 Thermal Management System Mode: Indicates the operating mode of the Thermal Management System.  The heat transfer medium may be (e.g. liquid or air).  The cooling system may be fans, liquid coolant, or a combination of mediums.  The system may...";
CM_ SG_ 2364651774 Hvsp3ThrmlMngmntSstmClntLvl "HVESP3 Thermal Management System Coolant Level: Indicates the coolant level in this HVES Thermal Management System (TMS).This parameter is for one of multiple packs in an HVESS.  If there is only one pack in the system, the HVESS parameters should be...";
CM_ BO_ 2364652030 "High Voltage Energy Storage Pack 3 Data 8";
CM_ SG_ 2364652030 Hvesp3AverageCellVoltage "HVESP3 Average Cell Voltage: The average cell voltage in this High Voltage Energy Storage Pack instance.This parameter is for one of multiple packs in an HVESS.  If there is only one pack in the system, the HVESS parameters should be used. If there a...";
CM_ SG_ 2364652030 Hvsp3HghstCllVltgMdlNmr "HVESP3 Highest Cell Voltage Module Number: Identifies the location of the module containing SPN 11287 (HVESP3 Highest Cell Voltage).This parameter is for one of multiple packs in an HVESS.  If there is only one pack in the system, the HVESS parameter...";
CM_ SG_ 2364652030 Hvsp3HghstCllVltgCllNmr "HVESP3 Highest Cell Voltage Cell Number: Identifies the location of SPN 11287 (HVESP3 Highest Cell Voltage) within SPN 11347 (HVESP3 Highest Cell Voltage Module Number).This parameter is for one of multiple packs in an HVESS.  If there is only one pa...";
CM_ SG_ 2364652030 Hvsp3LwstCllVltgMdlNmr "HVESP3 Lowest Cell Voltage Module Number: Identifies the location of the module containing SPN 11288 (HVESP3 Lowest Cell Voltage).This parameter is for one of multiple packs in an HVESS.  If there is only one pack in the system, the HVESS parameters ...";
CM_ SG_ 2364652030 Hvsp3LwstCllVltgCllNmr "HVESP3 Lowest Cell Voltage Cell Number: Identifies the location of SPN 11288 (HVESP3 Lowest Cell Voltage) within SPN 11349 (HVESP3 Lowest Cell Voltage Module Number).This parameter is for one of multiple packs in an HVESS.  If there is only one pack ...";
CM_ BO_ 2364652286 "High Voltage Energy Storage Pack 3 Data 9";
CM_ SG_ 2364652286 Hvsp3HghstCllTmprtrMdlNmr "HVESP3 Highest Cell Temperature Module Number: Identifies the location of the module containing SPN 11290 (HVESP3 Highest Cell Temperature).This parameter is for one of multiple packs in an HVESS.  If there is only one pack in the system, the HVESS p...";
CM_ SG_ 2364652286 Hvsp3HghstCllTmprtrCllNmr "HVESP3 Highest Cell Temperature Cell Number: Identifies the location of SPN 11290 (HVESP3 Highest Cell Temperature) within SPN 11352 (HVESP3 Highest Cell Temperature Module Number).This parameter is for one of multiple packs in an HVESS.  If there is...";
CM_ SG_ 2364652286 Hvsp3LwstCllTmprtrMdlNmr "HVESP3 Lowest Cell Temperature Module Number: Identifies the location of the module containing SPN 11291 (HVESP3 Lowest Cell Temperature).This parameter is for one of multiple packs in an HVESS.  If there is only one pack in the system, the HVESS par...";
CM_ SG_ 2364652286 Hvsp3LwstCllTmprtrCllNmr "HVESP3 Lowest Cell Temperature Cell Number: Identifies the location of SPN 11291 (HVESP3 Lowest Cell Temperature) within SPN 11354 (HVESP3 Lowest Cell Temperature Module Number).This parameter is for one of multiple packs in an HVESS.  If there is on...";
CM_ SG_ 2364652286 Hvess3ThermalEventDetected "HVESS3 Thermal Event Detected: A sensor has detected the presence of a thermal event at or near High Voltage Energy Storage Pack instance.00b = No Thermal Event Detected01b = Thermal Event Detected10b = Error11b = Not availableThis parameter is for o...";
CM_ SG_ 2364652286 Hvsp3Dt9EmdddIntgrtSpprt "HVESP3 Data 9 Embedded Integrity Support: Indicates SPN 22982 (HVESP3 Data 9 CRC) and SPN 22981 (HVESP3 Data 9 Counter) are supported by the sender.00b = Embedded CRC and Counter are supported by the sender01b = Protection is provided using an extern...";
CM_ SG_ 2364652286 Hvesp3Data9Counter "HVESP3 Data 9 Counter: The message counter is used to detect situations where the transmitting ECU malfunction repeats the same frame all the time. The receiver of the information may use the counter parameter to detect this situation. The transmitti...";
CM_ SG_ 2364652286 Hvesp3Data9Crc "HVESP3 Data 9 CRC: The CRC is defined as follows: - Length: 8 bits- Polynomial: x^8+x^5+x^3+x^2+x+1- Initial Value: FFh- Input Data Reflection: Not reflected- Result Data Reflection: Not reflected- XOR value: FFh SAE makes no claim of the functional ...";
BA_DEF_ SG_  "SPN" INT 0 524287;
BA_DEF_ BO_  "VFrameFormat" ENUM  "StandardCAN","ExtendedCAN","reserved","J1939PG";
BA_DEF_DEF_  "SPN" 0;
BA_DEF_DEF_  "VFrameFormat" "J1939PG";
BA_ "SPN" SG_ 2351824638 Hvesp4PowerDownCommand 11378;
BA_ "SPN" SG_ 2351824638 Hvesp4CellBalancingCommand 11381;
BA_ "SPN" SG_ 2351824638 Hvesp4OperationConsent 11383;
BA_ "SPN" SG_ 2351824638 Hvesp4Control1Counter 13035;
BA_ "SPN" SG_ 2351824638 Hvesp4Control1Crc 13036;
BA_ "SPN" SG_ 2351824638 Hvsp4HghVltgBsCnntCmmnd 11377;
BA_ "SPN" SG_ 2351824638 Hvsp4HghVltgBsAtvIsltnTstCmmnd 11379;
BA_ "SPN" SG_ 2351824638 Hvsp4HghVltgBsPssvIsltnTstCmmnd 11380;
BA_ "SPN" SG_ 2351824638 Hvsp4EnlIntrnlChrgrCmmnd 11382;
BA_ "SPN" SG_ 2351824638 Hvsp4HVtBsHSdRsstCtRqst 11384;
BA_ "SPN" SG_ 2351824638 Hvsp4HghVltgBsLwSdRsstrCnntRqst 11385;
BA_ "SPN" SG_ 2351824638 Hvsp4ThrmlMngmntMntnnRqst 20882;
BA_ "SPN" SG_ 2351890174 Hvesp5PowerDownCommand 11494;
BA_ "SPN" SG_ 2351890174 Hvesp5CellBalancingCommand 11497;
BA_ "SPN" SG_ 2351890174 Hvesp5OperationConsent 11499;
BA_ "SPN" SG_ 2351890174 Hvesp5Control1Counter 13037;
BA_ "SPN" SG_ 2351890174 Hvesp5Control1Crc 13038;
BA_ "SPN" SG_ 2351890174 Hvsp5HghVltgBsCnntCmmnd 11493;
BA_ "SPN" SG_ 2351890174 Hvsp5HghVltgBsAtvIsltnTstCmmnd 11495;
BA_ "SPN" SG_ 2351890174 Hvsp5HghVltgBsPssvIsltnTstCmmnd 11496;
BA_ "SPN" SG_ 2351890174 Hvsp5EnlIntrnlChrgrCmmnd 11498;
BA_ "SPN" SG_ 2351890174 Hvsp5HVtBsHSdRsstCtRqst 11500;
BA_ "SPN" SG_ 2351890174 Hvsp5HghVltgBsLwSdRsstrCnntRqst 11501;
BA_ "SPN" SG_ 2351890174 Hvsp5ThrmlMngmntMntnnRqst 20883;
BA_ "SPN" SG_ 2351955710 Hvesp6PowerDownCommand 11610;
BA_ "SPN" SG_ 2351955710 Hvesp6CellBalancingCommand 11613;
BA_ "SPN" SG_ 2351955710 Hvesp6OperationConsent 11615;
BA_ "SPN" SG_ 2351955710 Hvesp6Control1Counter 13039;
BA_ "SPN" SG_ 2351955710 Hvesp6Control1Crc 13040;
BA_ "SPN" SG_ 2351955710 Hvsp6HghVltgBsCnntCmmnd 11609;
BA_ "SPN" SG_ 2351955710 Hvsp6HghVltgBsAtvIsltnTstCmmnd 11611;
BA_ "SPN" SG_ 2351955710 Hvsp6HghVltgBsPssvIsltnTstCmmnd 11612;
BA_ "SPN" SG_ 2351955710 Hvsp6EnlIntrnlChrgrCmmnd 11614;
BA_ "SPN" SG_ 2351955710 Hvsp6HVtBsHSdRsstCtRqst 11616;
BA_ "SPN" SG_ 2351955710 Hvsp6HghVltgBsLwSdRsstrCnntRqst 11617;
BA_ "SPN" SG_ 2351955710 Hvsp6ThrmlMngmntMntnnRqst 20884;
BA_ "SPN" SG_ 2555641598 EvReady 21085;
BA_ "SPN" SG_ 2555641598 EvseConnectorLockRequest 12864;
BA_ "SPN" SG_ 2555641598 EvseDcStageRequest 21084;
BA_ "SPN" SG_ 2555641598 EvseContactorCommand 22687;
BA_ "SPN" SG_ 2555707134 WinchPositionReset 12312;
BA_ "SPN" SG_ 2354446078 LiftAxle3PositionCommand 12300;
BA_ "SPN" SG_ 2354511614 MtrGnrtr2InvrtrCntrl2Cntr 11765;
BA_ "SPN" SG_ 2354511614 MtrGnrtr2InvrtrCntrl2Cr 11764;
BA_ "SPN" SG_ 2354511614 MtrGnrtr2InvrtrPdCntrlAppllMd 11766;
BA_ "SPN" SG_ 2354511614 MtGt2IvtPdCtNzdDtG 11767;
BA_ "SPN" SG_ 2354511614 MtGt2IvtPdCtNzdItG 11768;
BA_ "SPN" SG_ 2354511614 MtGt2IvtPdCtNzdPptG 11769;
BA_ "SPN" SG_ 2354511614 MtGt2IvtPdCtFdFwdTq 12295;
BA_ "SPN" SG_ 2354577150 MtrGnrtr1InvrtrCntrl2Cntr 11759;
BA_ "SPN" SG_ 2354577150 MtrGnrtr1InvrtrCntrl2Cr 11758;
BA_ "SPN" SG_ 2354577150 MtrGnrtr1InvrtrPdCntrlAppllMd 11760;
BA_ "SPN" SG_ 2354577150 MtGt1IvtPdCtNzdDtG 11761;
BA_ "SPN" SG_ 2354577150 MtGt1IvtPdCtNzdItG 11762;
BA_ "SPN" SG_ 2354577150 MtGt1IvtPdCtNzdPptG 11763;
BA_ "SPN" SG_ 2354577150 MtGt1IvtPdCtFdFwdTq 12294;
BA_ "SPN" SG_ 2488860414 HoistCommand 11729;
BA_ "SPN" SG_ 2488860414 HoistDetentStatus 11730;
BA_ "SPN" SG_ 2556034814 MtGt2IvtHVtBsAtvIstTstCd 10806;
BA_ "SPN" SG_ 2556034814 MtGt2IvtHVtBsPssvIstTstCd 10807;
BA_ "SPN" SG_ 2556034814 MtGt2IvtHVtBsHSdRsstCtRqst 10808;
BA_ "SPN" SG_ 2556034814 MtGt2IvtHVtBsLwSdRsstCtRqst 10809;
BA_ "SPN" SG_ 2556100350 MtGt1IvtHVtBsAtvIstTstCd 10768;
BA_ "SPN" SG_ 2556100350 MtGt1IvtHVtBsPssvIstTstCd 10769;
BA_ "SPN" SG_ 2556100350 MtGt1IvtHVtBsHSdRsstCtRqst 10770;
BA_ "SPN" SG_ 2556100350 MtGt1IvtHVtBsLwSdRsstCtRqst 10771;
BA_ "SPN" SG_ 2565966846 MtrGnrtr1InvrtrStts2Cntr 10765;
BA_ "SPN" SG_ 2565966846 MtrGnrtr1AvllMxmmTrq 10766;
BA_ "SPN" SG_ 2565966846 MtrGnrtr1AvllMnmmTrq 10767;
BA_ "SPN" SG_ 2565966846 MtrGnrtr1InvrtrStts2Cr 10764;
BA_ "SPN" SG_ 2565967102 MtrGnrtr1InvrtrRtLmtsAtv1Cntr 10799;
BA_ "SPN" SG_ 2565967102 MtGt1IvtRtLtsAtvAstSpdRtLt 10800;
BA_ "SPN" SG_ 2565967102 MtGt1IvtRtLtsAtvAstTqRtLt 10801;
BA_ "SPN" SG_ 2565967102 MtrGnrtr1InvrtrRtLmtsAtv1Cr 10798;
BA_ "SPN" SG_ 2565967358 MtrGnrtr2InvrtrStts2Cntr 10803;
BA_ "SPN" SG_ 2565967358 MtrGnrtr2AvllMxmmTrq 10804;
BA_ "SPN" SG_ 2565967358 MtrGnrtr2AvllMnmmTrq 10805;
BA_ "SPN" SG_ 2565967358 MtrGnrtr2InvrtrStts2Cr 10802;
BA_ "SPN" SG_ 2565967614 MtrGnrtr2InvrtrRtLmtsAtv1Cntr 10837;
BA_ "SPN" SG_ 2565967614 MtGt2IvtRtLtsAtvAstSpdRtLt 10838;
BA_ "SPN" SG_ 2565967614 MtGt2IvtRtLtsAtvAstTqRtLt 10839;
BA_ "SPN" SG_ 2565967614 MtrGnrtr2InvrtrRtLmtsAtv1Cr 10836;
BA_ "SPN" SG_ 2297532414 ImpostorPgEventDetectionCounter 10840;
BA_ "SPN" SG_ 2297532414 ImpostorPgSourceAddress 10841;
BA_ "SPN" SG_ 2297532414 ImpostorPgDestinationAddress 10842;
BA_ "SPN" SG_ 2297532414 ImpostorPgn 10843;
BA_ "SPN" SG_ 2297532414 TimeSinceLastImpostorPgDetected 10844;
BA_ "SPN" SG_ 2364641534 Hvsp1DshrgPwrLmtDTSttOfChrg 11038;
BA_ "SPN" SG_ 2364641534 Hvsp1DshrgPwrLmtDTBttrTmprtr 11039;
BA_ "SPN" SG_ 2364641534 Hvsp1DsPwLtDTBttDstCdt 11040;
BA_ "SPN" SG_ 2364641534 Hvsp1DshrgPwrLmtDTBttrOrCllVltg 11041;
BA_ "SPN" SG_ 2364641534 Hvsp1DshrgPwrLmtDTBttrCrrnt 11042;
BA_ "SPN" SG_ 2364641534 Hvsp1DshrgPwrLmtDTAnUndfndCs 11043;
BA_ "SPN" SG_ 2364641534 Hvsp1ChrgPwrLmtDTSttOfChrg 11044;
BA_ "SPN" SG_ 2364641534 Hvsp1ChrgPwrLmtDTBttrTmprtr 11045;
BA_ "SPN" SG_ 2364641534 Hvsp1ChrgPwrLmtDTBttrDgnstCndtn 11046;
BA_ "SPN" SG_ 2364641534 Hvsp1ChrgPwrLmtDTBttrOrCllVltg 11047;
BA_ "SPN" SG_ 2364641534 Hvsp1ChrgPwrLmtDTBttrCrrnt 11048;
BA_ "SPN" SG_ 2364641534 Hvsp1ChrgPwrLmtDTAnUndfndCs 11049;
BA_ "SPN" SG_ 2364641790 Hvesp1AvailableDischargePower 11050;
BA_ "SPN" SG_ 2364641790 Hvesp1AvailableChargePower 11051;
BA_ "SPN" SG_ 2364641790 Hvesp1VoltageLevel 11052;
BA_ "SPN" SG_ 2364641790 Hvesp1Current 11053;
BA_ "SPN" SG_ 2364642046 Hvesp1FastUpdateStateOfCharge 11054;
BA_ "SPN" SG_ 2364642046 Hvesp1HighestCellVoltage 11055;
BA_ "SPN" SG_ 2364642046 Hvesp1LowestCellVoltage 11056;
BA_ "SPN" SG_ 2364642046 Hvsp1CllVltgDffrntlStts 11057;
BA_ "SPN" SG_ 2364642302 Hvesp1HighestCellTemperature 11058;
BA_ "SPN" SG_ 2364642302 Hvesp1LowestCellTemperature 11059;
BA_ "SPN" SG_ 2364642302 Hvesp1AverageCellTemperature 11060;
BA_ "SPN" SG_ 2364642302 Hvsp1CllTmprtrDffrntlStts 11061;
BA_ "SPN" SG_ 2364642558 Hvesp1DischargeCapacity 11062;
BA_ "SPN" SG_ 2364642558 Hvesp1ChargeCapacity 11063;
BA_ "SPN" SG_ 2364642558 Hvesp1CellBalancingCount 11064;
BA_ "SPN" SG_ 2364642814 Hvesp1LowestCellStateOfCharge 11067;
BA_ "SPN" SG_ 2364642814 Hvesp1HighestCellStateOfCharge 11068;
BA_ "SPN" SG_ 2364642814 Hvsp1MxmmInstntnsDshrgCrrntLmt 11065;
BA_ "SPN" SG_ 2364642814 Hvsp1MxmmInstntnsChrgCrrntLmt 11066;
BA_ "SPN" SG_ 2364643070 Hvesp1BusVoltage 11069;
BA_ "SPN" SG_ 2364643070 Hvesp1IgnitionVoltage 11070;
BA_ "SPN" SG_ 2364643070 Hvesp1IntakeCoolantTemperature 11071;
BA_ "SPN" SG_ 2364643070 Hvesp1OutletCoolantTemperature 11072;
BA_ "SPN" SG_ 2364643070 Hvesp1ElectronicsTemperature 11073;
BA_ "SPN" SG_ 2364643070 Hvesp1Temperature 11074;
BA_ "SPN" SG_ 2364643326 Hvesp1HvilStatus 11082;
BA_ "SPN" SG_ 2364643326 Hvesp1InertiaSwitchStatus 11083;
BA_ "SPN" SG_ 2364643326 Hvesp1StateOfChargeStatus 11084;
BA_ "SPN" SG_ 2364643326 Hvesp1CellBalanceStatus 11085;
BA_ "SPN" SG_ 2364643326 Hvesp1CellBalancingActive 11086;
BA_ "SPN" SG_ 2364643326 Hvesp1InternalChargerStatus 11087;
BA_ "SPN" SG_ 2364643326 Hvesp1OperationalStatus 11089;
BA_ "SPN" SG_ 2364643326 Hvesp1Status1Counter 13015;
BA_ "SPN" SG_ 2364643326 Hvesp1Status1Crc 13016;
BA_ "SPN" SG_ 2364643326 Hvsp1HghVltgBsPstvCnttrStt 11075;
BA_ "SPN" SG_ 2364643326 Hvsp1HghVltgBsNgtvCnttrStt 11076;
BA_ "SPN" SG_ 2364643326 Hvsp1HghVltgBsDsnntFrwrnng 11077;
BA_ "SPN" SG_ 2364643326 Hvsp1HghVltgBsPrChrgRlStt 11078;
BA_ "SPN" SG_ 2364643326 Hvsp1CntrOfPkCnttrStt 11079;
BA_ "SPN" SG_ 2364643326 Hvsp1HghVltgBsAtvIsltnTstStts 11080;
BA_ "SPN" SG_ 2364643326 Hvsp1HghVltgBsPssvIsltnTstStts 11081;
BA_ "SPN" SG_ 2364643326 Hvsp1HghVltgBsCnntnStts 11088;
BA_ "SPN" SG_ 2364643582 Hvesp1DischargeEnergyCapacity 11090;
BA_ "SPN" SG_ 2364643582 Hvesp1ChargeEnergyCapacity 11091;
BA_ "SPN" SG_ 2364643582 Hvesp1MaximumChargeVoltageLimit 11092;
BA_ "SPN" SG_ 2364643838 Hvesp1Module1OperationalStatus 11093;
BA_ "SPN" SG_ 2364643838 Hvesp1Module2OperationalStatus 11094;
BA_ "SPN" SG_ 2364643838 Hvesp1Module3OperationalStatus 11095;
BA_ "SPN" SG_ 2364643838 Hvesp1Module4OperationalStatus 11096;
BA_ "SPN" SG_ 2364643838 Hvesp1Module5OperationalStatus 11097;
BA_ "SPN" SG_ 2364643838 Hvesp1Module6OperationalStatus 11098;
BA_ "SPN" SG_ 2364643838 Hvesp1Module7OperationalStatus 11099;
BA_ "SPN" SG_ 2364643838 Hvesp1Module8OperationalStatus 11100;
BA_ "SPN" SG_ 2364643838 Hvesp1Module9OperationalStatus 11101;
BA_ "SPN" SG_ 2364643838 Hvesp1Module10OperationalStatus 11102;
BA_ "SPN" SG_ 2364643838 Hvesp1Module11OperationalStatus 11103;
BA_ "SPN" SG_ 2364643838 Hvesp1Module12OperationalStatus 11104;
BA_ "SPN" SG_ 2364643838 Hvesp1Module13OperationalStatus 11105;
BA_ "SPN" SG_ 2364643838 Hvesp1Module14OperationalStatus 11106;
BA_ "SPN" SG_ 2364643838 Hvesp1Module15OperationalStatus 11107;
BA_ "SPN" SG_ 2364643838 Hvesp1Module16OperationalStatus 11108;
BA_ "SPN" SG_ 2364643838 Hvesp1Module17OperationalStatus 14625;
BA_ "SPN" SG_ 2364643838 Hvesp1Module18OperationalStatus 14626;
BA_ "SPN" SG_ 2364643838 Hvesp1Module19OperationalStatus 14627;
BA_ "SPN" SG_ 2364643838 Hvesp1Module20OperationalStatus 14628;
BA_ "SPN" SG_ 2364643838 Hvesp1Module21OperationalStatus 14629;
BA_ "SPN" SG_ 2364643838 Hvesp1Module22OperationalStatus 14630;
BA_ "SPN" SG_ 2364643838 Hvesp1Module23OperationalStatus 14631;
BA_ "SPN" SG_ 2364643838 Hvesp1Module24OperationalStatus 14632;
BA_ "SPN" SG_ 2364643838 Hvesp1Module25OperationalStatus 14633;
BA_ "SPN" SG_ 2364643838 Hvesp1Module26OperationalStatus 14634;
BA_ "SPN" SG_ 2364643838 Hvesp1Module27OperationalStatus 14635;
BA_ "SPN" SG_ 2364643838 Hvesp1Module28OperationalStatus 14636;
BA_ "SPN" SG_ 2364643838 Hvesp1Module29OperationalStatus 14637;
BA_ "SPN" SG_ 2364643838 Hvesp1Module30OperationalStatus 14638;
BA_ "SPN" SG_ 2364643838 Hvesp1Module31OperationalStatus 14639;
BA_ "SPN" SG_ 2364643838 Hvesp1Module32OperationalStatus 14640;
BA_ "SPN" SG_ 2364644094 Hvsp1ThrmlMngmntSstmSlInptPwr 11109;
BA_ "SPN" SG_ 2364644094 Hvsp1TMtSstHVtIptPw 11110;
BA_ "SPN" SG_ 2364644094 Hvsp1ThrmlMngmntSstmCmprssrSpd 11111;
BA_ "SPN" SG_ 2364644094 Hvsp1ThrmlMngmntSstmRltvHmdt 11112;
BA_ "SPN" SG_ 2364644094 Hvsp1ThrmlMngmntSstmHtrStts 11113;
BA_ "SPN" SG_ 2364644094 Hvsp1ThrmlMngmntSstmHvlStts 12819;
BA_ "SPN" SG_ 2364644094 Hvsp1ThrmlMngmntSstmMd 11114;
BA_ "SPN" SG_ 2364644094 Hvsp1ThrmlMngmntSstmClntLvl 12898;
BA_ "SPN" SG_ 2364644350 Hvesp1AverageCellVoltage 11119;
BA_ "SPN" SG_ 2364644350 Hvsp1HghstCllVltgMdlNmr 11115;
BA_ "SPN" SG_ 2364644350 Hvsp1HghstCllVltgCllNmr 11116;
BA_ "SPN" SG_ 2364644350 Hvsp1LwstCllVltgMdlNmr 11117;
BA_ "SPN" SG_ 2364644350 Hvsp1LwstCllVltgCllNmr 11118;
BA_ "SPN" SG_ 2364644606 Hvsp1HghstCllTmprtrMdlNmr 11120;
BA_ "SPN" SG_ 2364644606 Hvsp1HghstCllTmprtrCllNmr 11121;
BA_ "SPN" SG_ 2364644606 Hvsp1LwstCllTmprtrMdlNmr 11122;
BA_ "SPN" SG_ 2364644606 Hvsp1LwstCllTmprtrCllNmr 11123;
BA_ "SPN" SG_ 2364644606 Hvess1ThermalEventDetected 21288;
BA_ "SPN" SG_ 2364644606 Hvsp1Dt9EmdddIntgrtSpprt 22974;
BA_ "SPN" SG_ 2364644606 Hvesp1Data9Counter 22975;
BA_ "SPN" SG_ 2364644606 Hvesp1Data9Crc 22976;
BA_ "SPN" SG_ 2364644862 Hvsp1HghstCllSttOfChrgMdlNmr 11124;
BA_ "SPN" SG_ 2364644862 Hvsp1HghstCllSttOfChrgCllNmr 11125;
BA_ "SPN" SG_ 2364644862 Hvsp1LwstCllSttOfChrgMdlNmr 11126;
BA_ "SPN" SG_ 2364644862 Hvsp1LwstCllSttOfChrgCllNmr 11127;
BA_ "SPN" SG_ 2364644862 Hvsp1HghVltgBsAtvIsltnTstRslts 11128;
BA_ "SPN" SG_ 2364644862 Hvsp1HghVltgBsPssvIsltnTstRslts 11129;
BA_ "SPN" SG_ 2364645118 Hvesp1ActualChargeRate 13065;
BA_ "SPN" SG_ 2364645118 Hvsp1BsVltgNgtvTChsssGrndVltg 11130;
BA_ "SPN" SG_ 2364645118 Hvsp1VltgLvlNgtvTChsssGrndVltg 11131;
BA_ "SPN" SG_ 2364645374 Hvsp2DshrgPwrLmtDTSttOfChrg 11154;
BA_ "SPN" SG_ 2364645374 Hvsp2DshrgPwrLmtDTBttrTmprtr 11155;
BA_ "SPN" SG_ 2364645374 Hvsp2DsPwLtDTBttDstCdt 11156;
BA_ "SPN" SG_ 2364645374 Hvsp2DshrgPwrLmtDTBttrOrCllVltg 11157;
BA_ "SPN" SG_ 2364645374 Hvsp2DshrgPwrLmtDTBttrCrrnt 11158;
BA_ "SPN" SG_ 2364645374 Hvsp2DshrgPwrLmtDTAnUndfndCs 11159;
BA_ "SPN" SG_ 2364645374 Hvsp2ChrgPwrLmtDTSttOfChrg 11160;
BA_ "SPN" SG_ 2364645374 Hvsp2ChrgPwrLmtDTBttrTmprtr 11161;
BA_ "SPN" SG_ 2364645374 Hvsp2ChrgPwrLmtDTBttrDgnstCndtn 11162;
BA_ "SPN" SG_ 2364645374 Hvsp2ChrgPwrLmtDTBttrOrCllVltg 11163;
BA_ "SPN" SG_ 2364645374 Hvsp2ChrgPwrLmtDTBttrCrrnt 11164;
BA_ "SPN" SG_ 2364645374 Hvsp2ChrgPwrLmtDTAnUndfndCs 11165;
BA_ "SPN" SG_ 2364645630 Hvesp2AvailableDischargePower 11166;
BA_ "SPN" SG_ 2364645630 Hvesp2AvailableChargePower 11167;
BA_ "SPN" SG_ 2364645630 Hvesp2VoltageLevel 11168;
BA_ "SPN" SG_ 2364645630 Hvesp2Current 11169;
BA_ "SPN" SG_ 2364645886 Hvesp2FastUpdateStateOfCharge 11170;
BA_ "SPN" SG_ 2364645886 Hvesp2HighestCellVoltage 11171;
BA_ "SPN" SG_ 2364645886 Hvesp2LowestCellVoltage 11172;
BA_ "SPN" SG_ 2364645886 Hvsp2CllVltgDffrntlStts 11173;
BA_ "SPN" SG_ 2364646142 Hvesp2HighestCellTemperature 11174;
BA_ "SPN" SG_ 2364646142 Hvesp2LowestCellTemperature 11175;
BA_ "SPN" SG_ 2364646142 Hvesp2AverageCellTemperature 11176;
BA_ "SPN" SG_ 2364646142 Hvsp2CllTmprtrDffrntlStts 11177;
BA_ "SPN" SG_ 2364646398 Hvesp2DischargeCapacity 11178;
BA_ "SPN" SG_ 2364646398 Hvesp2ChargeCapacity 11179;
BA_ "SPN" SG_ 2364646398 Hvesp2CellBalancingCount 11180;
BA_ "SPN" SG_ 2364646654 Hvesp2LowestCellStateOfCharge 11183;
BA_ "SPN" SG_ 2364646654 Hvesp2HighestCellStateOfCharge 11184;
BA_ "SPN" SG_ 2364646654 Hvsp2MxmmInstntnsDshrgCrrntLmt 11181;
BA_ "SPN" SG_ 2364646654 Hvsp2MxmmInstntnsChrgCrrntLmt 11182;
BA_ "SPN" SG_ 2364646910 Hvesp2BusVoltage 11185;
BA_ "SPN" SG_ 2364646910 Hvesp2IgnitionVoltage 11186;
BA_ "SPN" SG_ 2364646910 Hvesp2IntakeCoolantTemperature 11187;
BA_ "SPN" SG_ 2364646910 Hvesp2OutletCoolantTemperature 11188;
BA_ "SPN" SG_ 2364646910 Hvesp2ElectronicsTemperature 11189;
BA_ "SPN" SG_ 2364646910 Hvesp2Temperature 11190;
BA_ "SPN" SG_ 2364647166 Hvesp2HvilStatus 11198;
BA_ "SPN" SG_ 2364647166 Hvesp2InertiaSwitchStatus 11199;
BA_ "SPN" SG_ 2364647166 Hvesp2StateOfChargeStatus 11200;
BA_ "SPN" SG_ 2364647166 Hvesp2CellBalanceStatus 11201;
BA_ "SPN" SG_ 2364647166 Hvesp2CellBalancingActive 11202;
BA_ "SPN" SG_ 2364647166 Hvesp2InternalChargerStatus 11203;
BA_ "SPN" SG_ 2364647166 Hvesp2OperationalStatus 11205;
BA_ "SPN" SG_ 2364647166 Hvesp2Status1Counter 13017;
BA_ "SPN" SG_ 2364647166 Hvesp2Status1Crc 13018;
BA_ "SPN" SG_ 2364647166 Hvsp2HghVltgBsPstvCnttrStt 11191;
BA_ "SPN" SG_ 2364647166 Hvsp2HghVltgBsNgtvCnttrStt 11192;
BA_ "SPN" SG_ 2364647166 Hvsp2HghVltgBsDsnntFrwrnng 11193;
BA_ "SPN" SG_ 2364647166 Hvsp2HghVltgBsPrChrgRlStt 11194;
BA_ "SPN" SG_ 2364647166 Hvsp2CntrOfPkCnttrStt 11195;
BA_ "SPN" SG_ 2364647166 Hvsp2HghVltgBsAtvIsltnTstStts 11196;
BA_ "SPN" SG_ 2364647166 Hvsp2HghVltgBsPssvIsltnTstStts 11197;
BA_ "SPN" SG_ 2364647166 Hvsp2HghVltgBsCnntnStts 11204;
BA_ "SPN" SG_ 2364647422 Hvesp2DischargeEnergyCapacity 11206;
BA_ "SPN" SG_ 2364647422 Hvesp2ChargeEnergyCapacity 11207;
BA_ "SPN" SG_ 2364647422 Hvesp2MaximumChargeVoltageLimit 11208;
BA_ "SPN" SG_ 2364647678 Hvesp2Module1OperationalStatus 11209;
BA_ "SPN" SG_ 2364647678 Hvesp2Module2OperationalStatus 11210;
BA_ "SPN" SG_ 2364647678 Hvesp2Module3OperationalStatus 11211;
BA_ "SPN" SG_ 2364647678 Hvesp2Module4OperationalStatus 11212;
BA_ "SPN" SG_ 2364647678 Hvesp2Module5OperationalStatus 11213;
BA_ "SPN" SG_ 2364647678 Hvesp2Module6OperationalStatus 11214;
BA_ "SPN" SG_ 2364647678 Hvesp2Module7OperationalStatus 11215;
BA_ "SPN" SG_ 2364647678 Hvesp2Module8OperationalStatus 11216;
BA_ "SPN" SG_ 2364647678 Hvesp2Module9OperationalStatus 11217;
BA_ "SPN" SG_ 2364647678 Hvesp2Module10OperationalStatus 11218;
BA_ "SPN" SG_ 2364647678 Hvesp2Module11OperationalStatus 11219;
BA_ "SPN" SG_ 2364647678 Hvesp2Module12OperationalStatus 11220;
BA_ "SPN" SG_ 2364647678 Hvesp2Module13OperationalStatus 11221;
BA_ "SPN" SG_ 2364647678 Hvesp2Module14OperationalStatus 11222;
BA_ "SPN" SG_ 2364647678 Hvesp2Module15OperationalStatus 11223;
BA_ "SPN" SG_ 2364647678 Hvesp2Module16OperationalStatus 11224;
BA_ "SPN" SG_ 2364647678 Hvesp2Module17OperationalStatus 14641;
BA_ "SPN" SG_ 2364647678 Hvesp2Module18OperationalStatus 14642;
BA_ "SPN" SG_ 2364647678 Hvesp2Module19OperationalStatus 14643;
BA_ "SPN" SG_ 2364647678 Hvesp2Module20OperationalStatus 14644;
BA_ "SPN" SG_ 2364647678 Hvesp2Module21OperationalStatus 14645;
BA_ "SPN" SG_ 2364647678 Hvesp2Module22OperationalStatus 14646;
BA_ "SPN" SG_ 2364647678 Hvesp2Module23OperationalStatus 14647;
BA_ "SPN" SG_ 2364647678 Hvesp2Module24OperationalStatus 14648;
BA_ "SPN" SG_ 2364647678 Hvesp2Module25OperationalStatus 14649;
BA_ "SPN" SG_ 2364647678 Hvesp2Module26OperationalStatus 14650;
BA_ "SPN" SG_ 2364647678 Hvesp2Module27OperationalStatus 14651;
BA_ "SPN" SG_ 2364647678 Hvesp2Module28OperationalStatus 14652;
BA_ "SPN" SG_ 2364647678 Hvesp2Module29OperationalStatus 14653;
BA_ "SPN" SG_ 2364647678 Hvesp2Module30OperationalStatus 14654;
BA_ "SPN" SG_ 2364647678 Hvesp2Module31OperationalStatus 14655;
BA_ "SPN" SG_ 2364647678 Hvesp2Module32OperationalStatus 14656;
BA_ "SPN" SG_ 2364647934 Hvsp2ThrmlMngmntSstmSlInptPwr 11225;
BA_ "SPN" SG_ 2364647934 Hvsp2TMtSstHVtIptPw 11226;
BA_ "SPN" SG_ 2364647934 Hvsp2ThrmlMngmntSstmCmprssrSpd 11227;
BA_ "SPN" SG_ 2364647934 Hvsp2ThrmlMngmntSstmRltvHmdt 11228;
BA_ "SPN" SG_ 2364647934 Hvsp2ThrmlMngmntSstmHtrStts 11229;
BA_ "SPN" SG_ 2364647934 Hvsp2ThrmlMngmntSstmHvlStts 12818;
BA_ "SPN" SG_ 2364647934 Hvsp2ThrmlMngmntSstmMd 11230;
BA_ "SPN" SG_ 2364647934 Hvsp2ThrmlMngmntSstmClntLvl 12899;
BA_ "SPN" SG_ 2364648190 Hvesp2AverageCellVoltage 11235;
BA_ "SPN" SG_ 2364648190 Hvsp2HghstCllVltgMdlNmr 11231;
BA_ "SPN" SG_ 2364648190 Hvsp2HghstCllVltgCllNmr 11232;
BA_ "SPN" SG_ 2364648190 Hvsp2LwstCllVltgMdlNmr 11233;
BA_ "SPN" SG_ 2364648190 Hvsp2LwstCllVltgCllNmr 11234;
BA_ "SPN" SG_ 2364648446 Hvsp2HghstCllTmprtrMdlNmr 11236;
BA_ "SPN" SG_ 2364648446 Hvsp2HghstCllTmprtrCllNmr 11237;
BA_ "SPN" SG_ 2364648446 Hvsp2LwstCllTmprtrMdlNmr 11238;
BA_ "SPN" SG_ 2364648446 Hvsp2LwstCllTmprtrCllNmr 11239;
BA_ "SPN" SG_ 2364648446 Hvess2ThermalEventDetected 21289;
BA_ "SPN" SG_ 2364648446 Hvsp2Dt9EmdddIntgrtSpprt 22977;
BA_ "SPN" SG_ 2364648446 Hvesp2Data9Counter 22978;
BA_ "SPN" SG_ 2364648446 Hvesp2Data9Crc 22979;
BA_ "SPN" SG_ 2364648702 Hvsp2HghstCllSttOfChrgMdlNmr 11240;
BA_ "SPN" SG_ 2364648702 Hvsp2HghstCllSttOfChrgCllNmr 11241;
BA_ "SPN" SG_ 2364648702 Hvsp2LwstCllSttOfChrgMdlNmr 11242;
BA_ "SPN" SG_ 2364648702 Hvsp2LwstCllSttOfChrgCllNmr 11243;
BA_ "SPN" SG_ 2364648702 Hvsp2HghVltgBsAtvIsltnTstRslts 11244;
BA_ "SPN" SG_ 2364648702 Hvsp2HghVltgBsPssvIsltnTstRslts 11245;
BA_ "SPN" SG_ 2364648958 Hvesp2ActualChargeRate 13066;
BA_ "SPN" SG_ 2364648958 Hvsp2BsVltgNgtvTChsssGrndVltg 11246;
BA_ "SPN" SG_ 2364648958 Hvsp2VltgLvlNgtvTChsssGrndVltg 11247;
BA_ "SPN" SG_ 2364649214 Hvsp3DshrgPwrLmtDTSttOfChrg 11270;
BA_ "SPN" SG_ 2364649214 Hvsp3DshrgPwrLmtDTBttrTmprtr 11271;
BA_ "SPN" SG_ 2364649214 Hvsp3DsPwLtDTBttDstCdt 11272;
BA_ "SPN" SG_ 2364649214 Hvsp3DshrgPwrLmtDTBttrOrCllVltg 11273;
BA_ "SPN" SG_ 2364649214 Hvsp3DshrgPwrLmtDTBttrCrrnt 11274;
BA_ "SPN" SG_ 2364649214 Hvsp3DshrgPwrLmtDTAnUndfndCs 11275;
BA_ "SPN" SG_ 2364649214 Hvsp3ChrgPwrLmtDTSttOfChrg 11276;
BA_ "SPN" SG_ 2364649214 Hvsp3ChrgPwrLmtDTBttrTmprtr 11277;
BA_ "SPN" SG_ 2364649214 Hvsp3ChrgPwrLmtDTBttrDgnstCndtn 11278;
BA_ "SPN" SG_ 2364649214 Hvsp3ChrgPwrLmtDTBttrOrCllVltg 11279;
BA_ "SPN" SG_ 2364649214 Hvsp3ChrgPwrLmtDTBttrCrrnt 11280;
BA_ "SPN" SG_ 2364649214 Hvsp3ChrgPwrLmtDTAnUndfndCs 11281;
BA_ "SPN" SG_ 2364649470 Hvesp3AvailableDischargePower 11282;
BA_ "SPN" SG_ 2364649470 Hvesp3AvailableChargePower 11283;
BA_ "SPN" SG_ 2364649470 Hvesp3VoltageLevel 11284;
BA_ "SPN" SG_ 2364649470 Hvesp3Current 11285;
BA_ "SPN" SG_ 2364649726 Hvesp3FastUpdateStateOfCharge 11286;
BA_ "SPN" SG_ 2364649726 Hvesp3HighestCellVoltage 11287;
BA_ "SPN" SG_ 2364649726 Hvesp3LowestCellVoltage 11288;
BA_ "SPN" SG_ 2364649726 Hvsp3CllVltgDffrntlStts 11289;
BA_ "SPN" SG_ 2364649982 Hvesp3HighestCellTemperature 11290;
BA_ "SPN" SG_ 2364649982 Hvesp3LowestCellTemperature 11291;
BA_ "SPN" SG_ 2364649982 Hvesp3AverageCellTemperature 11292;
BA_ "SPN" SG_ 2364649982 Hvsp3CllTmprtrDffrntlStts 11293;
BA_ "SPN" SG_ 2364650238 Hvesp3DischargeCapacity 11294;
BA_ "SPN" SG_ 2364650238 Hvesp3ChargeCapacity 11295;
BA_ "SPN" SG_ 2364650238 Hvesp3CellBalancingCount 11296;
BA_ "SPN" SG_ 2364650494 Hvesp3LowestCellStateOfCharge 11299;
BA_ "SPN" SG_ 2364650494 Hvesp3HighestCellStateOfCharge 11300;
BA_ "SPN" SG_ 2364650494 Hvsp3MxmmInstntnsDshrgCrrntLmt 11297;
BA_ "SPN" SG_ 2364650494 Hvsp3MxmmInstntnsChrgCrrntLmt 11298;
BA_ "SPN" SG_ 2364650750 Hvesp3BusVoltage 11301;
BA_ "SPN" SG_ 2364650750 Hvesp3IgnitionVoltage 11302;
BA_ "SPN" SG_ 2364650750 Hvesp3IntakeCoolantTemperature 11303;
BA_ "SPN" SG_ 2364650750 Hvesp3OutletCoolantTemperature 11304;
BA_ "SPN" SG_ 2364650750 Hvesp3ElectronicsTemperature 11305;
BA_ "SPN" SG_ 2364650750 Hvesp3Temperature 11306;
BA_ "SPN" SG_ 2364651006 Hvesp3HvilStatus 11314;
BA_ "SPN" SG_ 2364651006 Hvesp3InertiaSwitchStatus 11315;
BA_ "SPN" SG_ 2364651006 Hvesp3StateOfChargeStatus 11316;
BA_ "SPN" SG_ 2364651006 Hvesp3CellBalanceStatus 11317;
BA_ "SPN" SG_ 2364651006 Hvesp3CellBalancingActive 11318;
BA_ "SPN" SG_ 2364651006 Hvesp3InternalChargerStatus 11319;
BA_ "SPN" SG_ 2364651006 Hvesp3OperationalStatus 11321;
BA_ "SPN" SG_ 2364651006 Hvesp3Status1Counter 13019;
BA_ "SPN" SG_ 2364651006 Hvesp3Status1Crc 13020;
BA_ "SPN" SG_ 2364651006 Hvsp3HghVltgBsPstvCnttrStt 11307;
BA_ "SPN" SG_ 2364651006 Hvsp3HghVltgBsNgtvCnttrStt 11308;
BA_ "SPN" SG_ 2364651006 Hvsp3HghVltgBsDsnntFrwrnng 11309;
BA_ "SPN" SG_ 2364651006 Hvsp3HghVltgBsPrChrgRlStt 11310;
BA_ "SPN" SG_ 2364651006 Hvsp3CntrOfPkCnttrStt 11311;
BA_ "SPN" SG_ 2364651006 Hvsp3HghVltgBsAtvIsltnTstStts 11312;
BA_ "SPN" SG_ 2364651006 Hvsp3HghVltgBsPssvIsltnTstStts 11313;
BA_ "SPN" SG_ 2364651006 Hvsp3HghVltgBsCnntnStts 11320;
BA_ "SPN" SG_ 2364651262 Hvesp3DischargeEnergyCapacity 11322;
BA_ "SPN" SG_ 2364651262 Hvesp3ChargeEnergyCapacity 11323;
BA_ "SPN" SG_ 2364651262 Hvesp3MaximumChargeVoltageLimit 11324;
BA_ "SPN" SG_ 2364651518 Hvesp3Module1OperationalStatus 11325;
BA_ "SPN" SG_ 2364651518 Hvesp3Module2OperationalStatus 11326;
BA_ "SPN" SG_ 2364651518 Hvesp3Module3OperationalStatus 11327;
BA_ "SPN" SG_ 2364651518 Hvesp3Module4OperationalStatus 11328;
BA_ "SPN" SG_ 2364651518 Hvesp3Module5OperationalStatus 11329;
BA_ "SPN" SG_ 2364651518 Hvesp3Module6OperationalStatus 11330;
BA_ "SPN" SG_ 2364651518 Hvesp3Module7OperationalStatus 11331;
BA_ "SPN" SG_ 2364651518 Hvesp3Module8OperationalStatus 11332;
BA_ "SPN" SG_ 2364651518 Hvesp3Module9OperationalStatus 11333;
BA_ "SPN" SG_ 2364651518 Hvesp3Module10OperationalStatus 11334;
BA_ "SPN" SG_ 2364651518 Hvesp3Module11OperationalStatus 11335;
BA_ "SPN" SG_ 2364651518 Hvesp3Module12OperationalStatus 11336;
BA_ "SPN" SG_ 2364651518 Hvesp3Module13OperationalStatus 11337;
BA_ "SPN" SG_ 2364651518 Hvesp3Module14OperationalStatus 11338;
BA_ "SPN" SG_ 2364651518 Hvesp3Module15OperationalStatus 11339;
BA_ "SPN" SG_ 2364651518 Hvesp3Module16OperationalStatus 11340;
BA_ "SPN" SG_ 2364651518 Hvesp3Module17OperationalStatus 14657;
BA_ "SPN" SG_ 2364651518 Hvesp3Module18OperationalStatus 14658;
BA_ "SPN" SG_ 2364651518 Hvesp3Module19OperationalStatus 14659;
BA_ "SPN" SG_ 2364651518 Hvesp3Module20OperationalStatus 14660;
BA_ "SPN" SG_ 2364651518 Hvesp3Module21OperationalStatus 14661;
BA_ "SPN" SG_ 2364651518 Hvesp3Module22OperationalStatus 14662;
BA_ "SPN" SG_ 2364651518 Hvesp3Module23OperationalStatus 14663;
BA_ "SPN" SG_ 2364651518 Hvesp3Module24OperationalStatus 14664;
BA_ "SPN" SG_ 2364651518 Hvesp3Module25OperationalStatus 14665;
BA_ "SPN" SG_ 2364651518 Hvesp3Module26OperationalStatus 14666;
BA_ "SPN" SG_ 2364651518 Hvesp3Module27OperationalStatus 14667;
BA_ "SPN" SG_ 2364651518 Hvesp3Module28OperationalStatus 14668;
BA_ "SPN" SG_ 2364651518 Hvesp3Module29OperationalStatus 14669;
BA_ "SPN" SG_ 2364651518 Hvesp3Module30OperationalStatus 14670;
BA_ "SPN" SG_ 2364651518 Hvesp3Module31OperationalStatus 14671;
BA_ "SPN" SG_ 2364651518 Hvesp3Module32OperationalStatus 14672;
BA_ "SPN" SG_ 2364651774 Hvsp3ThrmlMngmntSstmSlInptPwr 11341;
BA_ "SPN" SG_ 2364651774 Hvsp3TMtSstHVtIptPw 11342;
BA_ "SPN" SG_ 2364651774 Hvsp3ThrmlMngmntSstmCmprssrSpd 11343;
BA_ "SPN" SG_ 2364651774 Hvsp3ThrmlMngmntSstmRltvHmdt 11344;
BA_ "SPN" SG_ 2364651774 Hvsp3ThrmlMngmntSstmHtrStts 11345;
BA_ "SPN" SG_ 2364651774 Hvsp3ThrmlMngmntSstmHvlStts 12817;
BA_ "SPN" SG_ 2364651774 Hvsp3ThrmlMngmntSstmMd 11346;
BA_ "SPN" SG_ 2364651774 Hvsp3ThrmlMngmntSstmClntLvl 12900;
BA_ "SPN" SG_ 2364652030 Hvesp3AverageCellVoltage 11351;
BA_ "SPN" SG_ 2364652030 Hvsp3HghstCllVltgMdlNmr 11347;
BA_ "SPN" SG_ 2364652030 Hvsp3HghstCllVltgCllNmr 11348;
BA_ "SPN" SG_ 2364652030 Hvsp3LwstCllVltgMdlNmr 11349;
BA_ "SPN" SG_ 2364652030 Hvsp3LwstCllVltgCllNmr 11350;
BA_ "SPN" SG_ 2364652286 Hvsp3HghstCllTmprtrMdlNmr 11352;
BA_ "SPN" SG_ 2364652286 Hvsp3HghstCllTmprtrCllNmr 11353;
BA_ "SPN" SG_ 2364652286 Hvsp3LwstCllTmprtrMdlNmr 11354;
BA_ "SPN" SG_ 2364652286 Hvsp3LwstCllTmprtrCllNmr 11355;
BA_ "SPN" SG_ 2364652286 Hvess3ThermalEventDetected 21290;
BA_ "SPN" SG_ 2364652286 Hvsp3Dt9EmdddIntgrtSpprt 22980;
BA_ "SPN" SG_ 2364652286 Hvesp3Data9Counter 22981;
BA_ "SPN" SG_ 2364652286 Hvesp3Data9Crc 22982;
